[part 1 of 3: package /STLASWCs]
AUTOSAR XML (schema 4-3-0)
package /STLASWCs
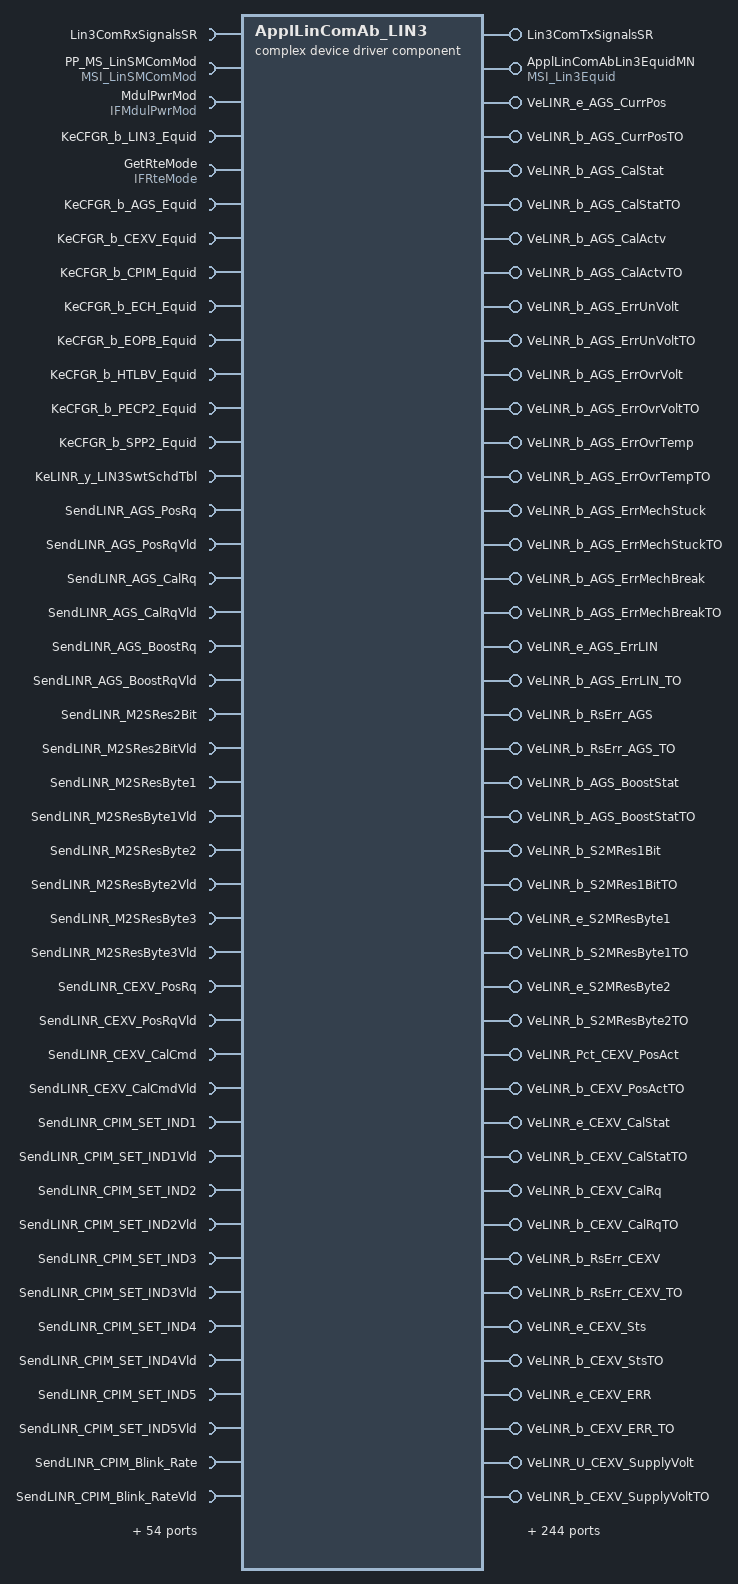
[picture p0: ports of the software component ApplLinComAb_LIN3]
  complex device driver sw component type ApplLinComAb_LIN3  # Application CAN Communication Abstraction Component - is responsible with receiving and sending CAN data from/to the lower BSW COM layers
    provide port Lin3ComTxSignalsSR: provided-interface=Lin3ComTxSignalsSR
      provided-com-specs:
        data-element=COMTXL_AGS_PosRq_ECM_AGS_DEMAND_Lin3, init-value=constant-reference=COMTXL_AGS_PosRq_ECM_AGS_DEMAND_Lin3_Init
        data-element=COMTXL_AGS_CalRq_ECM_AGS_DEMAND_Lin3, init-value=constant-reference=COMTXL_AGS_CalRq_ECM_AGS_DEMAND_Lin3_Init
        data-element=COMTXL_AGS_BoostRq_ECM_AGS_DEMAND_Lin3, init-value=constant-reference=COMTXL_AGS_BoostRq_ECM_AGS_DEMAND_Lin3_Init
        data-element=COMTXL_M2SRes2Bit_ECM_AGS_DEMAND_Lin3, init-value=constant-reference=COMTXL_M2SRes2Bit_ECM_AGS_DEMAND_Lin3_Init
        data-element=COMTXL_M2SResByte{1..3}_ECM_AGS_DEMAND_Lin3, init-value=constant-reference=COMTXL_M2SResByte{1..3}_ECM_AGS_DEMAND_Lin3_Init
        data-element=COMTXL_CEXV_PosRq_CEXV_REQ_Lin3, init-value=constant-reference=COMTXL_CEXV_PosRq_CEXV_REQ_Lin3_Init
        data-element=COMTXL_CEXV_CalCmd_CEXV_REQ_Lin3, init-value=constant-reference=COMTXL_CEXV_CalCmd_CEXV_REQ_Lin3_Init
        data-element=COMTXL_CPIM_SET_IND{1..5}_HCP_CPIM_COMMAND_Lin3, init-value=constant-reference=COMTXL_CPIM_SET_IND{1..5}_HCP_CPIM_COMMAND_Lin3_Init
        data-element=COMTXL_CPIM_Blink_Rate_HCP_CPIM_COMMAND_Lin3, init-value=constant-reference=COMTXL_CPIM_Blink_Rate_HCP_CPIM_COMMAND_Lin3_Init
        data-element=COMTXL_CPIM_IND_Color_HCP_CPIM_COMMAND_Lin3, init-value=constant-reference=COMTXL_CPIM_IND_Color_HCP_CPIM_COMMAND_Lin3_Init
        data-element=COMTXL_ChrgPortLock_Cmd_HCP_CPIM_COMMAND_Lin3, init-value=constant-reference=COMTXL_ChrgPortLock_Cmd_HCP_CPIM_COMMAND_Lin3_Init
        data-element=COMTXL_Set_Icon1_cmd_HCP_CPIM_COMMAND_Lin3, init-value=constant-reference=COMTXL_Set_Icon1_cmd_HCP_CPIM_COMMAND_Lin3_Init
        data-element=COMTXL_Set_Icon2_cmd_HCP_CPIM_COMMAND_Lin3, init-value=constant-reference=COMTXL_Set_Icon2_cmd_HCP_CPIM_COMMAND_Lin3_Init
        data-element=COMTXL_DAY_LGT_MD_CPIM_HCP_CPIM_COMMAND_Lin3, init-value=constant-reference=COMTXL_DAY_LGT_MD_CPIM_HCP_CPIM_COMMAND_Lin3_Init
        data-element=COMTXL_Backlight_Cmd_HCP_CPIM_COMMAND_Lin3, init-value=constant-reference=COMTXL_Backlight_Cmd_HCP_CPIM_COMMAND_Lin3_Init
        data-element=COMTXL_HvWtrHeatrPwrCnsAllwd_CCMLIN18Fr02_Lin3, init-value=constant-reference=COMTXL_HvWtrHeatrPwrCnsAllwd_CCMLIN18Fr02_Lin3_Init
        data-element=COMTXL_HvWtrHeatrWtrTDes_CCMLIN18Fr02_Lin3, init-value=constant-reference=COMTXL_HvWtrHeatrWtrTDes_CCMLIN18Fr02_Lin3_Init
        data-element=COMTXL_HvCooltHeatrEnad_CCMLIN18Fr02_Lin3, init-value=constant-reference=COMTXL_HvCooltHeatrEnad_CCMLIN18Fr02_Lin3_Init
        data-element=COMTXL_HVH_OverheatUnlock_CCMLIN18Fr02_Lin3, init-value=constant-reference=COMTXL_HVH_OverheatUnlock_CCMLIN18Fr02_Lin3_Init
        data-element=COMTXL_EOPB_RPM_COM_EOPB_REQ_Lin3, init-value=constant-reference=COMTXL_EOPB_RPM_COM_EOPB_REQ_Lin3_Init
        data-element=COMTXL_EOPB_POST_RUN_COM_EOPB_REQ_Lin3, init-value=constant-reference=COMTXL_EOPB_POST_RUN_COM_EOPB_REQ_Lin3_Init
        data-element=COMTXL_HTLBV_PosRq_HTLBV_REQ_Lin3, init-value=constant-reference=COMTXL_HTLBV_PosRq_HTLBV_REQ_Lin3_Init
        data-element=COMTXL_HTLBV_PosSv_HTLBV_REQ_Lin3, init-value=constant-reference=COMTXL_HTLBV_PosSv_HTLBV_REQ_Lin3_Init
        data-element=COMTXL_HTLBV_CalRq_HTLBV_REQ_Lin3, init-value=constant-reference=COMTXL_HTLBV_CalRq_HTLBV_REQ_Lin3_Init
        data-element=COMTXL_PECP2_RPM_REQ_PERCT_PECP2_REQ_GLOBAL_Lin3, init-value=constant-reference=COMTXL_PECP2_RPM_REQ_PERCT_PECP2_REQ_GLOBAL_Lin3_Init
        data-element=COMTXL_PECP2_POST_RUN_REQ_PECP2_REQ_GLOBAL_Lin3, init-value=constant-reference=COMTXL_PECP2_POST_RUN_REQ_PECP2_REQ_GLOBAL_Lin3_Init
        data-element=COMTXL_PECP2_FL_SAFE_ACTVT_PECP2_REQ_GLOBAL_Lin3, init-value=constant-reference=COMTXL_PECP2_FL_SAFE_ACTVT_PECP2_REQ_GLOBAL_Lin3_Init
        data-element=COMTXL_PowerPanel2_LED_A_Command_PowerPanel2_REQ_Lin3, init-value=constant-reference=COMTXL_PowerPanel2_LED_A_Command_PowerPanel2_REQ_Lin3_Init
        data-element=COMTXL_PowerPanel2_LED_B_Command_PowerPanel2_REQ_Lin3, init-value=constant-reference=COMTXL_PowerPanel2_LED_B_Command_PowerPanel2_REQ_Lin3_Init
        data-element=COMTXL_DAY_LGT_MD_PowerPanel2_PowerPanel2_REQ_Lin3, init-value=constant-reference=COMTXL_DAY_LGT_MD_PowerPanel2_PowerPanel2_REQ_Lin3_Init
        data-element=COMTXL_PowerPanel2_LED_A_Color_Command_PowerPanel2_REQ_Lin3, init-value=constant-reference=COMTXL_PowerPanel2_LED_A_Color_Command_PowerPanel2_REQ_Lin3_Init
        data-element=COMTXL_PowerPanel2_LED_B_Color_Command_PowerPanel2_REQ_Lin3, init-value=constant-reference=COMTXL_PowerPanel2_LED_B_Color_Command_PowerPanel2_REQ_Lin3_Init
    14 x require port:
      Lin3ComRxSignalsSR: required-interface=Lin3ComRxSignalsSR
        required-com-specs:
          data-element=COMRXL_AGS_CurrPos_AGS_ECM_STATUS_Lin3, alive-timeout=2.5, handle-never-received=true, init-value=constant-reference=COMRXL_AGS_CurrPos_AGS_ECM_STATUS_Lin3_Init
          data-element=COMRXL_AGS_CalStat_AGS_ECM_STATUS_Lin3, alive-timeout=2.5, handle-never-received=true, init-value=constant-reference=COMRXL_AGS_CalStat_AGS_ECM_STATUS_Lin3_Init
          data-element=COMRXL_AGS_CalActv_AGS_ECM_STATUS_Lin3, alive-timeout=2.5, handle-never-received=true, init-value=constant-reference=COMRXL_AGS_CalActv_AGS_ECM_STATUS_Lin3_Init
          data-element=COMRXL_AGS_ErrUnVolt_AGS_ECM_STATUS_Lin3, alive-timeout=2.5, handle-never-received=true, init-value=constant-reference=COMRXL_AGS_ErrUnVolt_AGS_ECM_STATUS_Lin3_Init
          data-element=COMRXL_AGS_ErrOvrVolt_AGS_ECM_STATUS_Lin3, alive-timeout=2.5, handle-never-received=true, init-value=constant-reference=COMRXL_AGS_ErrOvrVolt_AGS_ECM_STATUS_Lin3_Init
          data-element=COMRXL_AGS_ErrOvrTemp_AGS_ECM_STATUS_Lin3, alive-timeout=2.5, handle-never-received=true, init-value=constant-reference=COMRXL_AGS_ErrOvrTemp_AGS_ECM_STATUS_Lin3_Init
          data-element=COMRXL_AGS_ErrMechStuck_AGS_ECM_STATUS_Lin3, alive-timeout=2.5, handle-never-received=true, init-value=constant-reference=COMRXL_AGS_ErrMechStuck_AGS_ECM_STATUS_Lin3_Init
          data-element=COMRXL_AGS_ErrMechBreak_AGS_ECM_STATUS_Lin3, alive-timeout=2.5, handle-never-received=true, init-value=constant-reference=COMRXL_AGS_ErrMechBreak_AGS_ECM_STATUS_Lin3_Init
          data-element=COMRXL_AGS_ErrLIN_AGS_ECM_STATUS_Lin3, alive-timeout=2.5, handle-never-received=true, init-value=constant-reference=COMRXL_AGS_ErrLIN_AGS_ECM_STATUS_Lin3_Init
          data-element=COMRXL_RsErr_AGS_AGS_ECM_STATUS_Lin3, alive-timeout=2.5, handle-never-received=true, init-value=constant-reference=COMRXL_RsErr_AGS_AGS_ECM_STATUS_Lin3_Init
          data-element=COMRXL_AGS_BoostStat_AGS_ECM_STATUS_Lin3, alive-timeout=2.5, handle-never-received=true, init-value=constant-reference=COMRXL_AGS_BoostStat_AGS_ECM_STATUS_Lin3_Init
          data-element=COMRXL_S2MRes1Bit_AGS_ECM_STATUS_Lin3, alive-timeout=2.5, handle-never-received=true, init-value=constant-reference=COMRXL_S2MRes1Bit_AGS_ECM_STATUS_Lin3_Init
          data-element=COMRXL_S2MResByte1_AGS_ECM_STATUS_Lin3, alive-timeout=2.5, handle-never-received=true, init-value=constant-reference=COMRXL_S2MResByte1_AGS_ECM_STATUS_Lin3_Init
          data-element=COMRXL_S2MResByte2_AGS_ECM_STATUS_Lin3, alive-timeout=2.5, handle-never-received=true, init-value=constant-reference=COMRXL_S2MResByte2_AGS_ECM_STATUS_Lin3_Init
          data-element=COMRXL_CEXV_PosAct_CEXV_STAT_Lin3, alive-timeout=2.5, handle-never-received=true, init-value=constant-reference=COMRXL_CEXV_PosAct_CEXV_STAT_Lin3_Init
          data-element=COMRXL_CEXV_CalStat_CEXV_STAT_Lin3, alive-timeout=2.5, handle-never-received=true, init-value=constant-reference=COMRXL_CEXV_CalStat_CEXV_STAT_Lin3_Init
          data-element=COMRXL_CEXV_CalRq_CEXV_STAT_Lin3, alive-timeout=2.5, handle-never-received=true, init-value=constant-reference=COMRXL_CEXV_CalRq_CEXV_STAT_Lin3_Init
          data-element=COMRXL_RsErr_CEXV_CEXV_STAT_Lin3, alive-timeout=2.5, handle-never-received=true, init-value=constant-reference=COMRXL_RsErr_CEXV_CEXV_STAT_Lin3_Init
          data-element=COMRXL_CEXV_Sts_CEXV_STAT_Lin3, alive-timeout=2.5, handle-never-received=true, init-value=constant-reference=COMRXL_CEXV_Sts_CEXV_STAT_Lin3_Init
          data-element=COMRXL_CEXV_ERR_CEXV_STAT_Lin3, alive-timeout=2.5, handle-never-received=true, init-value=constant-reference=COMRXL_CEXV_ERR_CEXV_STAT_Lin3_Init
          data-element=COMRXL_CEXV_SupplyVolt_CEXV_STAT_Lin3, alive-timeout=2.5, handle-never-received=true, init-value=constant-reference=COMRXL_CEXV_SupplyVolt_CEXV_STAT_Lin3_Init
          data-element=COMRXL_CEXV_Refrigerant_Pressure_CEXV_STAT_Lin3, alive-timeout=2.5, handle-never-received=true, init-value=constant-reference=COMRXL_CEXV_Refrigerant_Pressure_CEXV_STAT_Lin3_Init
          data-element=COMRXL_CEXV_Board_Temp_CEXV_STAT_Lin3, alive-timeout=2.5, handle-never-received=true, init-value=constant-reference=COMRXL_CEXV_Board_Temp_CEXV_STAT_Lin3_Init
          data-element=COMRXL_CEXV_Refrigerant_Temp_CEXV_STAT_Lin3, alive-timeout=2.5, handle-never-received=true, init-value=constant-reference=COMRXL_CEXV_Refrigerant_Temp_CEXV_STAT_Lin3_Init
          data-element=COMRXL_Inlet_Temp1_DC_CPIM_HCP_FEEDBACK2_Lin3, alive-timeout=2.5, handle-never-received=true, init-value=constant-reference=COMRXL_Inlet_Temp1_DC_CPIM_HCP_FEEDBACK2_Lin3_Init
          data-element=COMRXL_Inlet_Temp2_DC_CPIM_HCP_FEEDBACK2_Lin3, alive-timeout=2.5, handle-never-received=true, init-value=constant-reference=COMRXL_Inlet_Temp2_DC_CPIM_HCP_FEEDBACK2_Lin3_Init
          data-element=COMRXL_CPIM_IND{1..5}_Fdbk_CPIM_HCP_FEEDBACK_Lin3, alive-timeout=2.5, handle-never-received=true, init-value=constant-reference=COMRXL_CPIM_IND{1..5}_Fdbk_CPIM_HCP_FEEDBACK_Lin3_Init
          data-element=COMRXL_CPIM_IND_Color_Fdbk_CPIM_HCP_FEEDBACK_Lin3, alive-timeout=2.5, handle-never-received=true, init-value=constant-reference=COMRXL_CPIM_IND_Color_Fdbk_CPIM_HCP_FEEDBACK_Lin3_Init
          data-element=COMRXL_CPIM_IND{1..5}_FailSts_CPIM_HCP_FEEDBACK_Lin3, alive-timeout=2.5, handle-never-received=true, init-value=constant-reference=COMRXL_CPIM_IND{1..5}_FailSts_CPIM_HCP_FEEDBACK_Lin3_Init
          data-element=COMRXL_CPIM_Undervoltage_CPIM_HCP_FEEDBACK_Lin3, alive-timeout=2.5, handle-never-received=true, init-value=constant-reference=COMRXL_CPIM_Undervoltage_CPIM_HCP_FEEDBACK_Lin3_Init
          data-element=COMRXL_CPIM_Over_Temperature_CPIM_HCP_FEEDBACK_Lin3, alive-timeout=2.5, handle-never-received=true, init-value=constant-reference=COMRXL_CPIM_Over_Temperature_CPIM_HCP_FEEDBACK_Lin3_Init
          data-element=COMRXL_CPIM_LIN_Parity_Error_CPIM_HCP_FEEDBACK_Lin3, alive-timeout=2.5, handle-never-received=true, init-value=constant-reference=COMRXL_CPIM_LIN_Parity_Error_CPIM_HCP_FEEDBACK_Lin3_Init
          data-element=COMRXL_CPIM_LIN_Checksum_Error_CPIM_HCP_FEEDBACK_Lin3, alive-timeout=2.5, handle-never-received=true, init-value=constant-reference=COMRXL_CPIM_LIN_Checksum_Error_CPIM_HCP_FEEDBACK_Lin3_Init
          data-element=COMRXL_CPIM_LIN_Data_Error_CPIM_HCP_FEEDBACK_Lin3, alive-timeout=2.5, handle-never-received=true, init-value=constant-reference=COMRXL_CPIM_LIN_Data_Error_CPIM_HCP_FEEDBACK_Lin3_Init
          data-element=COMRXL_ChrgPortLock_Sts_CPIM_HCP_FEEDBACK_Lin3, alive-timeout=2.5, handle-never-received=true, init-value=constant-reference=COMRXL_ChrgPortLock_Sts_CPIM_HCP_FEEDBACK_Lin3_Init
          data-element=COMRXL_ChrgPortButton_Sts_CPIM_HCP_FEEDBACK_Lin3, alive-timeout=2.5, handle-never-received=true, init-value=constant-reference=COMRXL_ChrgPortButton_Sts_CPIM_HCP_FEEDBACK_Lin3_Init
          data-element=COMRXL_Ambient_Temp_CPIM_HCP_FEEDBACK_Lin3, alive-timeout=2.5, handle-never-received=true, init-value=constant-reference=COMRXL_Ambient_Temp_CPIM_HCP_FEEDBACK_Lin3_Init
          data-element=COMRXL_Chrg_Inlet_Temp_CPIM_HCP_FEEDBACK_Lin3, alive-timeout=2.5, handle-never-received=true, init-value=constant-reference=COMRXL_Chrg_Inlet_Temp_CPIM_HCP_FEEDBACK_Lin3_Init
          data-element=COMRXL_ResponseErrorStsCPIM_CPIM_HCP_FEEDBACK_Lin3, alive-timeout=2.5, handle-never-received=true, init-value=constant-reference=COMRXL_ResponseErrorStsCPIM_CPIM_HCP_FEEDBACK_Lin3_Init
          data-element=COMRXL_ChrgPortLock_FailSts_CPIM_HCP_FEEDBACK_Lin3, alive-timeout=2.5, handle-never-received=true, init-value=constant-reference=COMRXL_ChrgPortLock_FailSts_CPIM_HCP_FEEDBACK_Lin3_Init
          data-element=COMRXL_Icon1_Sts_CPIM_HCP_FEEDBACK_Lin3, alive-timeout=2.5, handle-never-received=true, init-value=constant-reference=COMRXL_Icon1_Sts_CPIM_HCP_FEEDBACK_Lin3_Init
          data-element=COMRXL_Icon1_FailSts_CPIM_HCP_FEEDBACK_Lin3, alive-timeout=2.5, handle-never-received=true, init-value=constant-reference=COMRXL_Icon1_FailSts_CPIM_HCP_FEEDBACK_Lin3_Init
          data-element=COMRXL_Icon2_Sts_CPIM_HCP_FEEDBACK_Lin3, alive-timeout=2.5, handle-never-received=true, init-value=constant-reference=COMRXL_Icon2_Sts_CPIM_HCP_FEEDBACK_Lin3_Init
          data-element=COMRXL_Icon2_FailSts_CPIM_HCP_FEEDBACK_Lin3, alive-timeout=2.5, handle-never-received=true, init-value=constant-reference=COMRXL_Icon2_FailSts_CPIM_HCP_FEEDBACK_Lin3_Init
          data-element=COMRXL_ChrgPortDoor_Sts_CPIM_HCP_FEEDBACK_Lin3, alive-timeout=2.5, handle-never-received=true, init-value=constant-reference=COMRXL_ChrgPortDoor_Sts_CPIM_HCP_FEEDBACK_Lin3_Init
          data-element=COMRXL_HvCooltHeatrSts_HVCHLIN18Fr01_Lin3, alive-timeout=2.5, handle-never-received=true, init-value=constant-reference=COMRXL_HvCooltHeatrSts_HVCHLIN18Fr01_Lin3_Init
          data-element=COMRXL_ECH_InterlockStat_HVCHLIN18Fr01_Lin3, alive-timeout=2.5, handle-never-received=true, init-value=constant-reference=COMRXL_ECH_InterlockStat_HVCHLIN18Fr01_Lin3_Init
          data-element=COMRXL_Below_60V_HVCHLIN18Fr01_Lin3, alive-timeout=2.5, handle-never-received=true, init-value=constant-reference=COMRXL_Below_60V_HVCHLIN18Fr01_Lin3_Init
          data-element=COMRXL_HvCooltWtrHeatrWtrTInIntk_HVCHLIN18Fr01_Lin3, alive-timeout=2.5, handle-never-received=true, init-value=constant-reference=COMRXL_HvCooltWtrHeatrWtrTInIntk_HVCHLIN18Fr01_Lin3_Init
          data-element=COMRXL_HvWtrHeatrWtrT_HVCHLIN18Fr01_Lin3, alive-timeout=2.5, handle-never-received=true, init-value=constant-reference=COMRXL_HvWtrHeatrWtrT_HVCHLIN18Fr01_Lin3_Init
          data-element=COMRXL_HvCooltHeatrICns_HVCHLIN18Fr01_Lin3, alive-timeout=2.5, handle-never-received=true, init-value=constant-reference=COMRXL_HvCooltHeatrICns_HVCHLIN18Fr01_Lin3_Init
          data-element=COMRXL_HvCooltHVmeas_HVCHLIN18Fr01_Lin3, alive-timeout=2.5, handle-never-received=true, init-value=constant-reference=COMRXL_HvCooltHVmeas_HVCHLIN18Fr01_Lin3_Init
          data-element=COMRXL_HvHeatrPwrCns_HVCHLIN18Fr01_Lin3, alive-timeout=2.5, handle-never-received=true, init-value=constant-reference=COMRXL_HvHeatrPwrCns_HVCHLIN18Fr01_Lin3_Init
          data-element=COMRXL_HvHeatrPwrCnsDes_HVCHLIN18Fr01_Lin3, alive-timeout=2.5, handle-never-received=true, init-value=constant-reference=COMRXL_HvHeatrPwrCnsDes_HVCHLIN18Fr01_Lin3_Init
          data-element=COMRXL_HVH_UnlockCounter_HVCHLIN18Fr01_Lin3, alive-timeout=2.5, handle-never-received=true, init-value=constant-reference=COMRXL_HVH_UnlockCounter_HVCHLIN18Fr01_Lin3_Init
          data-element=COMRXL_RsErr_ECH_HVCHLIN18Fr02_Lin3, alive-timeout=2.5, handle-never-received=true, init-value=constant-reference=COMRXL_RsErr_ECH_HVCHLIN18Fr02_Lin3_Init
          data-element=COMRXL_HvCooltHeatrWarnFltInCom_HVCHLIN18Fr02_Lin3, alive-timeout=2.5, handle-never-received=true, init-value=constant-reference=COMRXL_HvCooltHeatrWarnFltInCom_HVCHLIN18Fr02_Lin3_Init
          data-element=COMRXL_HvCooltHeatrWarnHvOutOfRng_HVCHLIN18Fr02_Lin3, alive-timeout=2.5, handle-never-received=true, init-value=constant-reference=COMRXL_HvCooltHeatrWarnHvOutOfRng_HVCHLIN18Fr02_Lin3_Init
          data-element=COMRXL_HvCooltHeatrWarnULoOutOfRng_HVCHLIN18Fr02_Lin3, alive-timeout=2.5, handle-never-received=true, init-value=constant-reference=COMRXL_HvCooltHeatrWarnULoOutOfRng_HVCHLIN18Fr02_Lin3_Init
          data-element=COMRXL_HvCooltHeatrWarnCooltTOutOfRng_HVCHLIN18Fr02_Lin3, alive-timeout=2.5, handle-never-received=true, init-value=constant-reference=COMRXL_HvCooltHeatrWarnCooltTOutOfRng_HVCHLIN18Fr02_Lin3_Init
          data-element=COMRXL_HvCooltHeatrProtnOfSelfTmpHwProtn_HVCHLIN18Fr02_Lin3, alive-timeout=2.5, handle-never-received=true, init-value=constant-reference=COMRXL_HvCooltHeatrProtnOfSelfTmpHwProtn_HVCHLIN18Fr02_Lin3_Init
          data-element=COMRXL_HvCooltHeatrProtnOfSelfTmpOvrheatg_HVCHLIN18Fr02_Lin3, alive-timeout=2.5, handle-never-received=true, init-value=constant-reference=COMRXL_HvCooltHeatrProtnOfSelfTmpOvrheatg_HVCHLIN18Fr02_Lin3_Init
          data-element=COMRXL_HvCooltHeatrSnsrFltCooltTInSnsrFlt_HVCHLIN18Fr02_Lin3, alive-timeout=2.5, handle-never-received=true, init-value=constant-reference=COMRXL_HvCooltHeatrSnsrFltCooltTInSnsrFlt_HVCHLIN18Fr02_Lin3_Init
          data-element=COMRXL_HvCooltHeatrSnsrFltCooltTOutSnsrFlt_HVCHLIN18Fr02_Lin3, alive-timeout=2.5, handle-never-received=true, init-value=constant-reference=COMRXL_HvCooltHeatrSnsrFltCooltTOutSnsrFlt_HVCHLIN18Fr02_Lin3_Init
          data-element=COMRXL_HvCooltHeatrSnsrFltTInMtrlSnsrFlt_HVCHLIN18Fr02_Lin3, alive-timeout=2.5, handle-never-received=true, init-value=constant-reference=COMRXL_HvCooltHeatrSnsrFltTInMtrlSnsrFlt_HVCHLIN18Fr02_Lin3_Init
          data-element=COMRXL_HvCooltHeatrSrvRqrdCircForDrvrShoOrOpen_HVCHLIN18Fr02_Lin3, alive-timeout=2.5, handle-never-received=true, init-value=constant-reference=COMRXL_HvCooltHeatrSrvRqrdCircForDrvrShoOrOpen_HVCHLIN18Fr02_Lin3_Init
          data-element=COMRXL_HvCooltHeatrSrvRqrdICnsOutOfRng_HVCHLIN18Fr02_Lin3, alive-timeout=2.5, handle-never-received=true, init-value=constant-reference=COMRXL_HvCooltHeatrSrvRqrdICnsOutOfRng_HVCHLIN18Fr02_Lin3_Init
          data-element=COMRXL_HvCooltHeatrSrvRqrdMemErr_HVCHLIN18Fr02_Lin3, alive-timeout=2.5, handle-never-received=true, init-value=constant-reference=COMRXL_HvCooltHeatrSrvRqrdMemErr_HVCHLIN18Fr02_Lin3_Init
          data-element=COMRXL_HvCooltHeatrSrvRqrdSrvRqrd_HVCHLIN18Fr02_Lin3, alive-timeout=2.5, handle-never-received=true, init-value=constant-reference=COMRXL_HvCooltHeatrSrvRqrdSrvRqrd_HVCHLIN18Fr02_Lin3_Init
          data-element=COMRXL_EOPB_RPM_TGT_EOPB_STAT_Lin3, alive-timeout=2.5, handle-never-received=true, init-value=constant-reference=COMRXL_EOPB_RPM_TGT_EOPB_STAT_Lin3_Init
          data-element=COMRXL_EOPB_RPM_ACTL_EOPB_STAT_Lin3, alive-timeout=2.5, handle-never-received=true, init-value=constant-reference=COMRXL_EOPB_RPM_ACTL_EOPB_STAT_Lin3_Init
          data-element=COMRXL_EOPB_VLTG_EOPB_STAT_Lin3, alive-timeout=2.5, handle-never-received=true, init-value=constant-reference=COMRXL_EOPB_VLTG_EOPB_STAT_Lin3_Init
          data-element=COMRXL_EOPB_TEMP_EOPB_STAT_Lin3, alive-timeout=2.5, handle-never-received=true, init-value=constant-reference=COMRXL_EOPB_TEMP_EOPB_STAT_Lin3_Init
          data-element=COMRXL_EOPB_CURR_EOPB_STAT_Lin3, alive-timeout=2.5, handle-never-received=true, init-value=constant-reference=COMRXL_EOPB_CURR_EOPB_STAT_Lin3_Init
          data-element=COMRXL_EOPB_LOW_TMP_STAT_EOPB_STAT_Lin3, alive-timeout=2.5, handle-never-received=true, init-value=constant-reference=COMRXL_EOPB_LOW_TMP_STAT_EOPB_STAT_Lin3_Init
          data-element=COMRXL_EOPB_MONTRNG_RPM_EOPB_STAT_Lin3, alive-timeout=2.5, handle-never-received=true, init-value=constant-reference=COMRXL_EOPB_MONTRNG_RPM_EOPB_STAT_Lin3_Init
          data-element=COMRXL_EOPB_LMP_HM_AN_ON_EOPB_STAT_Lin3, alive-timeout=2.5, handle-never-received=true, init-value=constant-reference=COMRXL_EOPB_LMP_HM_AN_ON_EOPB_STAT_Lin3_Init
          data-element=COMRXL_EOPB_OV_TMP_ER_EOPB_STAT_Lin3, alive-timeout=2.5, handle-never-received=true, init-value=constant-reference=COMRXL_EOPB_OV_TMP_ER_EOPB_STAT_Lin3_Init
          data-element=COMRXL_EOPB_OV_CUR_ER_EOPB_STAT_Lin3, alive-timeout=2.5, handle-never-received=true, init-value=constant-reference=COMRXL_EOPB_OV_CUR_ER_EOPB_STAT_Lin3_Init
          data-element=COMRXL_EOPB_DR_RN_ER_EOPB_STAT_Lin3, alive-timeout=2.5, handle-never-received=true, init-value=constant-reference=COMRXL_EOPB_DR_RN_ER_EOPB_STAT_Lin3_Init
          data-element=COMRXL_EOPB_VLTG_ER_EOPB_STAT_Lin3, alive-timeout=2.5, handle-never-received=true, init-value=constant-reference=COMRXL_EOPB_VLTG_ER_EOPB_STAT_Lin3_Init
          data-element=COMRXL_EOPB_Stall_Event_EOPB_STAT_Lin3, alive-timeout=2.5, handle-never-received=true, init-value=constant-reference=COMRXL_EOPB_Stall_Event_EOPB_STAT_Lin3_Init
          data-element=COMRXL_EOPB_POST_RUN_STAT_EOPB_STAT_Lin3, alive-timeout=2.5, handle-never-received=true, init-value=constant-reference=COMRXL_EOPB_POST_RUN_STAT_EOPB_STAT_Lin3_Init
          data-element=COMRXL_RsErr_EOPB_EOPB_STAT_Lin3, alive-timeout=2.5, handle-never-received=true, init-value=constant-reference=COMRXL_RsErr_EOPB_EOPB_STAT_Lin3_Init
          data-element=COMRXL_EOPB_OIL_TEMP_EOPB_STAT2_Lin3, alive-timeout=2.5, handle-never-received=true, init-value=constant-reference=COMRXL_EOPB_OIL_TEMP_EOPB_STAT2_Lin3_Init
          data-element=COMRXL_EOPB_HW_VER_EOPB_VER_Lin3, alive-timeout=2.5, handle-never-received=true, init-value=constant-reference=COMRXL_EOPB_HW_VER_EOPB_VER_Lin3_Init
          data-element=COMRXL_EOPB_SW_VER_EOPB_VER_Lin3, alive-timeout=2.5, handle-never-received=true, init-value=constant-reference=COMRXL_EOPB_SW_VER_EOPB_VER_Lin3_Init
          data-element=COMRXL_HTLBV_PosAct_HTLBV_STAT_Lin3, alive-timeout=2.5, handle-never-received=true, init-value=constant-reference=COMRXL_HTLBV_PosAct_HTLBV_STAT_Lin3_Init
          data-element=COMRXL_HTLBV_ERR_HTLBV_STAT_Lin3, alive-timeout=2.5, handle-never-received=true, init-value=constant-reference=COMRXL_HTLBV_ERR_HTLBV_STAT_Lin3_Init
          data-element=COMRXL_HTLBV_MotorVolt_HTLBV_STAT_Lin3, alive-timeout=2.5, handle-never-received=true, init-value=constant-reference=COMRXL_HTLBV_MotorVolt_HTLBV_STAT_Lin3_Init
          data-element=COMRXL_HTLBV_Sts_HTLBV_STAT_Lin3, alive-timeout=2.5, handle-never-received=true, init-value=constant-reference=COMRXL_HTLBV_Sts_HTLBV_STAT_Lin3_Init
          data-element=COMRXL_RsErr_HTLBV_HTLBV_STAT_Lin3, alive-timeout=2.5, handle-never-received=true, init-value=constant-reference=COMRXL_RsErr_HTLBV_HTLBV_STAT_Lin3_Init
          data-element=COMRXL_HTLBV_CalStat_HTLBV_STAT_Lin3, alive-timeout=2.5, handle-never-received=true, init-value=constant-reference=COMRXL_HTLBV_CalStat_HTLBV_STAT_Lin3_Init
          data-element=COMRXL_PECP2_RPM_TGT_PERCT_PECP2_STAT_GLOBAL_Lin3, alive-timeout=2.5, handle-never-received=true, init-value=constant-reference=COMRXL_PECP2_RPM_TGT_PERCT_PECP2_STAT_GLOBAL_Lin3_Init
          data-element=COMRXL_PECP2_RPM_ACTL_PERCT_PECP2_STAT_GLOBAL_Lin3, alive-timeout=2.5, handle-never-received=true, init-value=constant-reference=COMRXL_PECP2_RPM_ACTL_PERCT_PECP2_STAT_GLOBAL_Lin3_Init
          data-element=COMRXL_PECP2_VLTG_PECP2_STAT_GLOBAL_Lin3, alive-timeout=2.5, handle-never-received=true, init-value=constant-reference=COMRXL_PECP2_VLTG_PECP2_STAT_GLOBAL_Lin3_Init
          data-element=COMRXL_PECP2_TEMP_PECP2_STAT_GLOBAL_Lin3, alive-timeout=2.5, handle-never-received=true, init-value=constant-reference=COMRXL_PECP2_TEMP_PECP2_STAT_GLOBAL_Lin3_Init
          data-element=COMRXL_PECP2_CURR_PECP2_STAT_GLOBAL_Lin3, alive-timeout=2.5, handle-never-received=true, init-value=constant-reference=COMRXL_PECP2_CURR_PECP2_STAT_GLOBAL_Lin3_Init
          data-element=COMRXL_PECP2_FL_SAFE_ACTVTD_PECP2_STAT_GLOBAL_Lin3, alive-timeout=2.5, handle-never-received=true, init-value=constant-reference=COMRXL_PECP2_FL_SAFE_ACTVTD_PECP2_STAT_GLOBAL_Lin3_Init
          data-element=COMRXL_PECP2_LMP_HM_AN_ON_PECP2_STAT_GLOBAL_Lin3, alive-timeout=2.5, handle-never-received=true, init-value=constant-reference=COMRXL_PECP2_LMP_HM_AN_ON_PECP2_STAT_GLOBAL_Lin3_Init
          data-element=COMRXL_PECP2_AIR_PRE_ERR_PECP2_STAT_GLOBAL_Lin3, alive-timeout=2.5, handle-never-received=true, init-value=constant-reference=COMRXL_PECP2_AIR_PRE_ERR_PECP2_STAT_GLOBAL_Lin3_Init
          data-element=COMRXL_PECP2_OVR_TMP_ERR_PECP2_STAT_GLOBAL_Lin3, alive-timeout=2.5, handle-never-received=true, init-value=constant-reference=COMRXL_PECP2_OVR_TMP_ERR_PECP2_STAT_GLOBAL_Lin3_Init
          data-element=COMRXL_PECP2_OVR_CUR_ERR_PECP2_STAT_GLOBAL_Lin3, alive-timeout=2.5, handle-never-received=true, init-value=constant-reference=COMRXL_PECP2_OVR_CUR_ERR_PECP2_STAT_GLOBAL_Lin3_Init
          data-element=COMRXL_PECP2_DR_RN_ERR_PECP2_STAT_GLOBAL_Lin3, alive-timeout=2.5, handle-never-received=true, init-value=constant-reference=COMRXL_PECP2_DR_RN_ERR_PECP2_STAT_GLOBAL_Lin3_Init
          data-element=COMRXL_PECP2_VLTG_ERR_PECP2_STAT_GLOBAL_Lin3, alive-timeout=2.5, handle-never-received=true, init-value=constant-reference=COMRXL_PECP2_VLTG_ERR_PECP2_STAT_GLOBAL_Lin3_Init
          data-element=COMRXL_PECP2_DBLK_ACTV_PECP2_STAT_GLOBAL_Lin3, alive-timeout=2.5, handle-never-received=true, init-value=constant-reference=COMRXL_PECP2_DBLK_ACTV_PECP2_STAT_GLOBAL_Lin3_Init
          data-element=COMRXL_PECP2_MONTRNG_RPM_PECP2_STAT_GLOBAL_Lin3, alive-timeout=2.5, handle-never-received=true, init-value=constant-reference=COMRXL_PECP2_MONTRNG_RPM_PECP2_STAT_GLOBAL_Lin3_Init
          data-element=COMRXL_PECP2_NODE_ERR_PECP2_STAT_GLOBAL_Lin3, alive-timeout=2.5, handle-never-received=true, init-value=constant-reference=COMRXL_PECP2_NODE_ERR_PECP2_STAT_GLOBAL_Lin3_Init
          data-element=COMRXL_PECP2_POST_RUN_STAT_PECP2_STAT_GLOBAL_Lin3, alive-timeout=2.5, handle-never-received=true, init-value=constant-reference=COMRXL_PECP2_POST_RUN_STAT_PECP2_STAT_GLOBAL_Lin3_Init
          data-element=COMRXL_RsErr_PECP2_PUMP_PECP2_STAT_GLOBAL_Lin3, alive-timeout=2.5, handle-never-received=true, init-value=constant-reference=COMRXL_RsErr_PECP2_PUMP_PECP2_STAT_GLOBAL_Lin3_Init
          data-element=COMRXL_PECP2_VERSION_PECP2_VER_Lin3, alive-timeout=2.5, handle-never-received=true, init-value=constant-reference=COMRXL_PECP2_VERSION_PECP2_VER_Lin3_Init
          data-element=COMRXL_PECP2_SUPPLIER_PECP2_VER_Lin3, alive-timeout=2.5, handle-never-received=true, init-value=constant-reference=COMRXL_PECP2_SUPPLIER_PECP2_VER_Lin3_Init
          data-element=COMRXL_PowerPanel2_Button_State_PowerPanel2_STAT_Lin3, alive-timeout=2.5, handle-never-received=true, init-value=constant-reference=COMRXL_PowerPanel2_Button_State_PowerPanel2_STAT_Lin3_Init
          data-element=COMRXL_PowerPanel2_Lid_Switch_Sts_120A_PowerPanel2_STAT_Lin3, alive-timeout=2.5, handle-never-received=true, init-value=constant-reference=COMRXL_PowerPanel2_Lid_Switch_Sts_120A_PowerPanel2_STAT_Lin3_Init
          data-element=COMRXL_PowerPanel2_Lid_Switch_Sts_120B_PowerPanel2_STAT_Lin3, alive-timeout=2.5, handle-never-received=true, init-value=constant-reference=COMRXL_PowerPanel2_Lid_Switch_Sts_120B_PowerPanel2_STAT_Lin3_Init
          data-element=COMRXL_PowerPanel2_Lid_Switch_Sts_240_PowerPanel2_STAT_Lin3, alive-timeout=2.5, handle-never-received=true, init-value=constant-reference=COMRXL_PowerPanel2_Lid_Switch_Sts_240_PowerPanel2_STAT_Lin3_Init
          data-element=COMRXL_PowerPanel2_AC_Present_Sens1_PowerPanel2_STAT_Lin3, alive-timeout=2.5, handle-never-received=true, init-value=constant-reference=COMRXL_PowerPanel2_AC_Present_Sens1_PowerPanel2_STAT_Lin3_Init
          data-element=COMRXL_PowerPanel2_AC_Present_Sens2_PowerPanel2_STAT_Lin3, alive-timeout=2.5, handle-never-received=true, init-value=constant-reference=COMRXL_PowerPanel2_AC_Present_Sens2_PowerPanel2_STAT_Lin3_Init
          data-element=COMRXL_PowerPanel2_Fault_Reason_PowerPanel2_STAT_Lin3, alive-timeout=2.5, handle-never-received=true, init-value=constant-reference=COMRXL_PowerPanel2_Fault_Reason_PowerPanel2_STAT_Lin3_Init
          data-element=COMRXL_RsErr_SPP2_PowerPanel2_STAT_Lin3, alive-timeout=2.5, handle-never-received=true, init-value=constant-reference=COMRXL_RsErr_SPP2_PowerPanel2_STAT_Lin3_Init
          data-element=COMRXL_PowerPanel2_LED_A_Feedback_PowerPanel2_STAT_Lin3, alive-timeout=2.5, handle-never-received=true, init-value=constant-reference=COMRXL_PowerPanel2_LED_A_Feedback_PowerPanel2_STAT_Lin3_Init
          data-element=COMRXL_PowerPanel2_LED_B_Feedback_PowerPanel2_STAT_Lin3, alive-timeout=2.5, handle-never-received=true, init-value=constant-reference=COMRXL_PowerPanel2_LED_B_Feedback_PowerPanel2_STAT_Lin3_Init
          data-element=COMRXL_PowerPanel2_LED_A_FailStatus_PowerPanel2_STAT_Lin3, alive-timeout=2.5, handle-never-received=true, init-value=constant-reference=COMRXL_PowerPanel2_LED_A_FailStatus_PowerPanel2_STAT_Lin3_Init
          data-element=COMRXL_PowerPanel2_LED_B_FailStatus_PowerPanel2_STAT_Lin3, alive-timeout=2.5, handle-never-received=true, init-value=constant-reference=COMRXL_PowerPanel2_LED_B_FailStatus_PowerPanel2_STAT_Lin3_Init
          data-element=COMRXL_PowerPanel2_LED_A_Color_Feedback_PowerPanel2_STAT_Lin3, alive-timeout=2.5, handle-never-received=true, init-value=constant-reference=COMRXL_PowerPanel2_LED_A_Color_Feedback_PowerPanel2_STAT_Lin3_Init
          data-element=COMRXL_PowerPanel2_LED_B_Color_Feedback_PowerPanel2_STAT_Lin3, alive-timeout=2.5, handle-never-received=true, init-value=constant-reference=COMRXL_PowerPanel2_LED_B_Color_Feedback_PowerPanel2_STAT_Lin3_Init
          data-element=COMRXL_PowerPanel2_LIN_Checksum_Error_PowerPanel2_STAT_Lin3, alive-timeout=2.5, handle-never-received=true, init-value=constant-reference=COMRXL_PowerPanel2_LIN_Checksum_Error_PowerPanel2_STAT_Lin3_Init
          data-element=COMRXL_PowerPanel2_LIN_Data_Error_PowerPanel2_STAT_Lin3, alive-timeout=2.5, handle-never-received=true, init-value=constant-reference=COMRXL_PowerPanel2_LIN_Data_Error_PowerPanel2_STAT_Lin3_Init
          data-element=COMRXL_PowerPanel2_LIN_Parity_Error_PowerPanel2_STAT_Lin3, alive-timeout=2.5, handle-never-received=true, init-value=constant-reference=COMRXL_PowerPanel2_LIN_Parity_Error_PowerPanel2_STAT_Lin3_Init
          data-element=COMRXL_PowerPanel2_Gnd_Fault_Detected_PowerPanel2_STAT_Lin3, alive-timeout=2.5, handle-never-received=true, init-value=constant-reference=COMRXL_PowerPanel2_Gnd_Fault_Detected_PowerPanel2_STAT_Lin3_Init
          data-element=COMRXL_PowerPanel2_Current_Draw_Sens1_PowerPanel2_STAT_Lin3, alive-timeout=2.5, handle-never-received=true, init-value=constant-reference=COMRXL_PowerPanel2_Current_Draw_Sens1_PowerPanel2_STAT_Lin3_Init
          data-element=COMRXL_PowerPanel2_Current_Draw_Sens2_PowerPanel2_STAT_Lin3, alive-timeout=2.5, handle-never-received=true, init-value=constant-reference=COMRXL_PowerPanel2_Current_Draw_Sens2_PowerPanel2_STAT_Lin3_Init
          data-element=COMRXL_PowerPanel2_Fault_PowerPanel2_STAT_Lin3, alive-timeout=2.5, handle-never-received=true, init-value=constant-reference=COMRXL_PowerPanel2_Fault_PowerPanel2_STAT_Lin3_Init
          data-element=COMRXL_PowerPanel2_RatedPower_PowerPanel2_STAT_Lin3, alive-timeout=2.5, handle-never-received=true, init-value=constant-reference=COMRXL_PowerPanel2_RatedPower_PowerPanel2_STAT_Lin3_Init
      PP_MS_LinSMComMod: mode-switch-receiver-com-spec=MDGP_MSI_LinSMComMod, required-interface=MSI_LinSMComMod  # Mode switch port used to indicate Linsm comm state
      MdulPwrMod: mode-switch-receiver-com-spec=AppMode_MDGP_ESH_Mode, required-interface=IFMdulPwrMod  # Mode switch port used to indicate ECU state
      KeCFGR_b_LIN3_Equid: parameter-require-com-spec{init-value=Value:1, parameter=KeCFGR_b_LIN3_Equid}, required-interface=KeCFGR_b_LIN3_Equid
      GetRteMode: client-com-spec=GetMODR_b_InPostRunMode, required-interface=IFRteMode
      KeCFGR_b_AGS_Equid: parameter-require-com-spec{init-value=Value:0, parameter=KeCFGR_b_AGS_Equid}, required-interface=KeCFGR_b_AGS_Equid
      KeCFGR_b_CEXV_Equid: parameter-require-com-spec{init-value=Value:0, parameter=KeCFGR_b_CEXV_Equid}, required-interface=KeCFGR_b_CEXV_Equid
      KeCFGR_b_CPIM_Equid: parameter-require-com-spec{init-value=Value:0, parameter=KeCFGR_b_CPIM_Equid}, required-interface=KeCFGR_b_CPIM_Equid
      KeCFGR_b_ECH_Equid: parameter-require-com-spec{init-value=Value:0, parameter=KeCFGR_b_ECH_Equid}, required-interface=KeCFGR_b_ECH_Equid
      KeCFGR_b_EOPB_Equid: parameter-require-com-spec{init-value=Value:0, parameter=KeCFGR_b_EOPB_Equid}, required-interface=KeCFGR_b_EOPB_Equid
      KeCFGR_b_HTLBV_Equid: parameter-require-com-spec{init-value=Value:0, parameter=KeCFGR_b_HTLBV_Equid}, required-interface=KeCFGR_b_HTLBV_Equid
      KeCFGR_b_PECP2_Equid: parameter-require-com-spec{init-value=Value:0, parameter=KeCFGR_b_PECP2_Equid}, required-interface=KeCFGR_b_PECP2_Equid
      KeCFGR_b_SPP2_Equid: parameter-require-com-spec{init-value=Value:0, parameter=KeCFGR_b_SPP2_Equid}, required-interface=KeCFGR_b_SPP2_Equid
      KeLINR_y_LIN3SwtSchdTbl: parameter-require-com-spec{init-value=Value:0, parameter=KeLINR_y_LIN3SwtSchdTbl}, required-interface=KeLINR_y_LIN3SwtSchdTbl
    257 x provide port:
      ApplLinComAbLin3EquidMN: mode-switch-sender-com-spec{mode-group=MDGP_MSI_Lin3Equid, queue-length=1}, provided-interface=MSI_Lin3Equid
      VeLINR_e_AGS_CurrPos: nonqueued-sender-com-spec{data-element=VeLINR_e_AGS_CurrPos, init-value=VeLINR_e_AGS_CurrPosValue:0}, provided-interface=VeLINR_e_AGS_CurrPos
      VeLINR_b_AGS_CurrPosTO: nonqueued-sender-com-spec{data-element=VeLINR_b_AGS_CurrPosTO, init-value=VeLINR_b_AGS_CurrPosTOValue:0}, provided-interface=VeLINR_b_AGS_CurrPosTO
      VeLINR_b_AGS_CalStat: nonqueued-sender-com-spec{data-element=VeLINR_b_AGS_CalStat, init-value=VeLINR_b_AGS_CalStatValue:0}, provided-interface=VeLINR_b_AGS_CalStat
      VeLINR_b_AGS_CalStatTO: nonqueued-sender-com-spec{data-element=VeLINR_b_AGS_CalStatTO, init-value=VeLINR_b_AGS_CalStatTOValue:0}, provided-interface=VeLINR_b_AGS_CalStatTO
      VeLINR_b_AGS_CalActv: nonqueued-sender-com-spec{data-element=VeLINR_b_AGS_CalActv, init-value=VeLINR_b_AGS_CalActvValue:0}, provided-interface=VeLINR_b_AGS_CalActv
      VeLINR_b_AGS_CalActvTO: nonqueued-sender-com-spec{data-element=VeLINR_b_AGS_CalActvTO, init-value=VeLINR_b_AGS_CalActvTOValue:0}, provided-interface=VeLINR_b_AGS_CalActvTO
      VeLINR_b_AGS_ErrUnVolt: nonqueued-sender-com-spec{data-element=VeLINR_b_AGS_ErrUnVolt, init-value=VeLINR_b_AGS_ErrUnVoltValue:0}, provided-interface=VeLINR_b_AGS_ErrUnVolt
      VeLINR_b_AGS_ErrUnVoltTO: nonqueued-sender-com-spec{data-element=VeLINR_b_AGS_ErrUnVoltTO, init-value=VeLINR_b_AGS_ErrUnVoltTOValue:0}, provided-interface=VeLINR_b_AGS_ErrUnVoltTO
      VeLINR_b_AGS_ErrOvrVolt: nonqueued-sender-com-spec{data-element=VeLINR_b_AGS_ErrOvrVolt, init-value=VeLINR_b_AGS_ErrOvrVoltValue:0}, provided-interface=VeLINR_b_AGS_ErrOvrVolt
      VeLINR_b_AGS_ErrOvrVoltTO: nonqueued-sender-com-spec{data-element=VeLINR_b_AGS_ErrOvrVoltTO, init-value=VeLINR_b_AGS_ErrOvrVoltTOValue:0}, provided-interface=VeLINR_b_AGS_ErrOvrVoltTO
      VeLINR_b_AGS_ErrOvrTemp: nonqueued-sender-com-spec{data-element=VeLINR_b_AGS_ErrOvrTemp, init-value=VeLINR_b_AGS_ErrOvrTempValue:0}, provided-interface=VeLINR_b_AGS_ErrOvrTemp
      VeLINR_b_AGS_ErrOvrTempTO: nonqueued-sender-com-spec{data-element=VeLINR_b_AGS_ErrOvrTempTO, init-value=VeLINR_b_AGS_ErrOvrTempTOValue:0}, provided-interface=VeLINR_b_AGS_ErrOvrTempTO
      VeLINR_b_AGS_ErrMechStuck: nonqueued-sender-com-spec{data-element=VeLINR_b_AGS_ErrMechStuck, init-value=VeLINR_b_AGS_ErrMechStuckValue:0}, provided-interface=VeLINR_b_AGS_ErrMechStuck
      VeLINR_b_AGS_ErrMechStuckTO: nonqueued-sender-com-spec{data-element=VeLINR_b_AGS_ErrMechStuckTO, init-value=VeLINR_b_AGS_ErrMechStuckTOValue:0}, provided-interface=VeLINR_b_AGS_ErrMechStuckTO
      VeLINR_b_AGS_ErrMechBreak: nonqueued-sender-com-spec{data-element=VeLINR_b_AGS_ErrMechBreak, init-value=VeLINR_b_AGS_ErrMechBreakValue:0}, provided-interface=VeLINR_b_AGS_ErrMechBreak
      VeLINR_b_AGS_ErrMechBreakTO: nonqueued-sender-com-spec{data-element=VeLINR_b_AGS_ErrMechBreakTO, init-value=VeLINR_b_AGS_ErrMechBreakTOValue:0}, provided-interface=VeLINR_b_AGS_ErrMechBreakTO
      VeLINR_e_AGS_ErrLIN: nonqueued-sender-com-spec{data-element=VeLINR_e_AGS_ErrLIN, init-value=VeLINR_e_AGS_ErrLINValue:0}, provided-interface=VeLINR_e_AGS_ErrLIN
      VeLINR_b_AGS_ErrLIN_TO: nonqueued-sender-com-spec{data-element=VeLINR_b_AGS_ErrLIN_TO, init-value=VeLINR_b_AGS_ErrLIN_TOValue:0}, provided-interface=VeLINR_b_AGS_ErrLIN_TO
      VeLINR_b_RsErr_AGS: nonqueued-sender-com-spec{data-element=VeLINR_b_RsErr_AGS, init-value=VeLINR_b_RsErr_AGSValue:0}, provided-interface=VeLINR_b_RsErr_AGS
      VeLINR_b_RsErr_AGS_TO: nonqueued-sender-com-spec{data-element=VeLINR_b_RsErr_AGS_TO, init-value=VeLINR_b_RsErr_AGS_TOValue:0}, provided-interface=VeLINR_b_RsErr_AGS_TO
      VeLINR_b_AGS_BoostStat: nonqueued-sender-com-spec{data-element=VeLINR_b_AGS_BoostStat, init-value=VeLINR_b_AGS_BoostStatValue:0}, provided-interface=VeLINR_b_AGS_BoostStat
      VeLINR_b_AGS_BoostStatTO: nonqueued-sender-com-spec{data-element=VeLINR_b_AGS_BoostStatTO, init-value=VeLINR_b_AGS_BoostStatTOValue:0}, provided-interface=VeLINR_b_AGS_BoostStatTO
      VeLINR_b_S2MRes1Bit: nonqueued-sender-com-spec{data-element=VeLINR_b_S2MRes1Bit, init-value=VeLINR_b_S2MRes1BitValue:0}, provided-interface=VeLINR_b_S2MRes1Bit
      VeLINR_b_S2MRes1BitTO: nonqueued-sender-com-spec{data-element=VeLINR_b_S2MRes1BitTO, init-value=VeLINR_b_S2MRes1BitTOValue:0}, provided-interface=VeLINR_b_S2MRes1BitTO
      VeLINR_e_S2MResByte1: nonqueued-sender-com-spec{data-element=VeLINR_e_S2MResByte1, init-value=VeLINR_e_S2MResByte1Value:0}, provided-interface=VeLINR_e_S2MResByte1
      VeLINR_b_S2MResByte1TO: nonqueued-sender-com-spec{data-element=VeLINR_b_S2MResByte1TO, init-value=VeLINR_b_S2MResByte1TOValue:0}, provided-interface=VeLINR_b_S2MResByte1TO
      VeLINR_e_S2MResByte2: nonqueued-sender-com-spec{data-element=VeLINR_e_S2MResByte2, init-value=VeLINR_e_S2MResByte2Value:0}, provided-interface=VeLINR_e_S2MResByte2
      VeLINR_b_S2MResByte2TO: nonqueued-sender-com-spec{data-element=VeLINR_b_S2MResByte2TO, init-value=VeLINR_b_S2MResByte2TOValue:0}, provided-interface=VeLINR_b_S2MResByte2TO
      VeLINR_Pct_CEXV_PosAct: nonqueued-sender-com-spec{data-element=VeLINR_Pct_CEXV_PosAct, init-value=VeLINR_Pct_CEXV_PosActValue:0}, provided-interface=VeLINR_Pct_CEXV_PosAct
      VeLINR_b_CEXV_PosActTO: nonqueued-sender-com-spec{data-element=VeLINR_b_CEXV_PosActTO, init-value=VeLINR_b_CEXV_PosActTOValue:0}, provided-interface=VeLINR_b_CEXV_PosActTO
      VeLINR_e_CEXV_CalStat: nonqueued-sender-com-spec{data-element=VeLINR_e_CEXV_CalStat, init-value=VeLINR_e_CEXV_CalStatValue:0}, provided-interface=VeLINR_e_CEXV_CalStat
      VeLINR_b_CEXV_CalStatTO: nonqueued-sender-com-spec{data-element=VeLINR_b_CEXV_CalStatTO, init-value=VeLINR_b_CEXV_CalStatTOValue:0}, provided-interface=VeLINR_b_CEXV_CalStatTO
      VeLINR_b_CEXV_CalRq: nonqueued-sender-com-spec{data-element=VeLINR_b_CEXV_CalRq, init-value=VeLINR_b_CEXV_CalRqValue:0}, provided-interface=VeLINR_b_CEXV_CalRq
      VeLINR_b_CEXV_CalRqTO: nonqueued-sender-com-spec{data-element=VeLINR_b_CEXV_CalRqTO, init-value=VeLINR_b_CEXV_CalRqTOValue:0}, provided-interface=VeLINR_b_CEXV_CalRqTO
      VeLINR_b_RsErr_CEXV: nonqueued-sender-com-spec{data-element=VeLINR_b_RsErr_CEXV, init-value=VeLINR_b_RsErr_CEXVValue:0}, provided-interface=VeLINR_b_RsErr_CEXV
      VeLINR_b_RsErr_CEXV_TO: nonqueued-sender-com-spec{data-element=VeLINR_b_RsErr_CEXV_TO, init-value=VeLINR_b_RsErr_CEXV_TOValue:0}, provided-interface=VeLINR_b_RsErr_CEXV_TO
      VeLINR_e_CEXV_Sts: nonqueued-sender-com-spec{data-element=VeLINR_e_CEXV_Sts, init-value=VeLINR_e_CEXV_StsValue:0}, provided-interface=VeLINR_e_CEXV_Sts
      VeLINR_b_CEXV_StsTO: nonqueued-sender-com-spec{data-element=VeLINR_b_CEXV_StsTO, init-value=VeLINR_b_CEXV_StsTOValue:0}, provided-interface=VeLINR_b_CEXV_StsTO
      VeLINR_e_CEXV_ERR: nonqueued-sender-com-spec{data-element=VeLINR_e_CEXV_ERR, init-value=VeLINR_e_CEXV_ERRValue:0}, provided-interface=VeLINR_e_CEXV_ERR
      VeLINR_b_CEXV_ERR_TO: nonqueued-sender-com-spec{data-element=VeLINR_b_CEXV_ERR_TO, init-value=VeLINR_b_CEXV_ERR_TOValue:0}, provided-interface=VeLINR_b_CEXV_ERR_TO
      VeLINR_U_CEXV_SupplyVolt: nonqueued-sender-com-spec{data-element=VeLINR_U_CEXV_SupplyVolt, init-value=VeLINR_U_CEXV_SupplyVoltValue:0}, provided-interface=VeLINR_U_CEXV_SupplyVolt
      VeLINR_b_CEXV_SupplyVoltTO: nonqueued-sender-com-spec{data-element=VeLINR_b_CEXV_SupplyVoltTO, init-value=VeLINR_b_CEXV_SupplyVoltTOValue:0}, provided-interface=VeLINR_b_CEXV_SupplyVoltTO
      VeLINR_e_CEXV_Refrigerant_Press: nonqueued-sender-com-spec{data-element=VeLINR_e_CEXV_Refrigerant_Press, init-value=VeLINR_e_CEXV_Refrigerant_PressValue:1638.3}, provided-interface=VeLINR_e_CEXV_Refrigerant_Press
      VeLINR_b_CEXV_Refrigerant_PressTO: nonqueued-sender-com-spec{data-element=VeLINR_b_CEXV_Refrigerant_PressTO, init-value=VeLINR_b_CEXV_Refrigerant_PressTOValue:0}, provided-interface=VeLINR_b_CEXV_Refrigerant_PressTO
      VeLINR_T_CEXV_Board_Temp: nonqueued-sender-com-spec{data-element=VeLINR_T_CEXV_Board_Temp, init-value=VeLINR_T_CEXV_Board_TempValue:-40}, provided-interface=VeLINR_T_CEXV_Board_Temp
      VeLINR_b_CEXV_Board_TempTO: nonqueued-sender-com-spec{data-element=VeLINR_b_CEXV_Board_TempTO, init-value=VeLINR_b_CEXV_Board_TempTOValue:0}, provided-interface=VeLINR_b_CEXV_Board_TempTO
      VeLINR_e_CEXV_Refrigerant_Temp: nonqueued-sender-com-spec{data-element=VeLINR_e_CEXV_Refrigerant_Temp, init-value=VeLINR_e_CEXV_Refrigerant_TempValue:-40}, provided-interface=VeLINR_e_CEXV_Refrigerant_Temp
      VeLINR_b_CEXV_Refrigerant_TempTO: nonqueued-sender-com-spec{data-element=VeLINR_b_CEXV_Refrigerant_TempTO, init-value=VeLINR_b_CEXV_Refrigerant_TempTOValue:0}, provided-interface=VeLINR_b_CEXV_Refrigerant_TempTO
      VeLINR_e_Inlet_Temp1_DC: nonqueued-sender-com-spec{data-element=VeLINR_e_Inlet_Temp1_DC, init-value=VeLINR_e_Inlet_Temp1_DCValue:-40}, provided-interface=VeLINR_e_Inlet_Temp1_DC
      VeLINR_b_Inlet_Temp1_DC_TO: nonqueued-sender-com-spec{data-element=VeLINR_b_Inlet_Temp1_DC_TO, init-value=VeLINR_b_Inlet_Temp1_DC_TOValue:0}, provided-interface=VeLINR_b_Inlet_Temp1_DC_TO
      VeLINR_e_Inlet_Temp2_DC: nonqueued-sender-com-spec{data-element=VeLINR_e_Inlet_Temp2_DC, init-value=VeLINR_e_Inlet_Temp2_DCValue:-40}, provided-interface=VeLINR_e_Inlet_Temp2_DC
      VeLINR_b_Inlet_Temp2_DC_TO: nonqueued-sender-com-spec{data-element=VeLINR_b_Inlet_Temp2_DC_TO, init-value=VeLINR_b_Inlet_Temp2_DC_TOValue:0}, provided-interface=VeLINR_b_Inlet_Temp2_DC_TO
      VeLINR_e_CPIM_IND1_Fdbk: nonqueued-sender-com-spec{data-element=VeLINR_e_CPIM_IND1_Fdbk, init-value=VeLINR_e_CPIM_IND1_FdbkValue:0}, provided-interface=VeLINR_e_CPIM_IND1_Fdbk
      VeLINR_b_CPIM_IND1_FdbkTO: nonqueued-sender-com-spec{data-element=VeLINR_b_CPIM_IND1_FdbkTO, init-value=VeLINR_b_CPIM_IND1_FdbkTOValue:0}, provided-interface=VeLINR_b_CPIM_IND1_FdbkTO
      VeLINR_e_CPIM_IND2_Fdbk: nonqueued-sender-com-spec{data-element=VeLINR_e_CPIM_IND2_Fdbk, init-value=VeLINR_e_CPIM_IND2_FdbkValue:0}, provided-interface=VeLINR_e_CPIM_IND2_Fdbk
      VeLINR_b_CPIM_IND2_FdbkTO: nonqueued-sender-com-spec{data-element=VeLINR_b_CPIM_IND2_FdbkTO, init-value=VeLINR_b_CPIM_IND2_FdbkTOValue:0}, provided-interface=VeLINR_b_CPIM_IND2_FdbkTO
      VeLINR_e_CPIM_IND3_Fdbk: nonqueued-sender-com-spec{data-element=VeLINR_e_CPIM_IND3_Fdbk, init-value=VeLINR_e_CPIM_IND3_FdbkValue:0}, provided-interface=VeLINR_e_CPIM_IND3_Fdbk
      VeLINR_b_CPIM_IND3_FdbkTO: nonqueued-sender-com-spec{data-element=VeLINR_b_CPIM_IND3_FdbkTO, init-value=VeLINR_b_CPIM_IND3_FdbkTOValue:0}, provided-interface=VeLINR_b_CPIM_IND3_FdbkTO
      VeLINR_e_CPIM_IND4_Fdbk: nonqueued-sender-com-spec{data-element=VeLINR_e_CPIM_IND4_Fdbk, init-value=VeLINR_e_CPIM_IND4_FdbkValue:0}, provided-interface=VeLINR_e_CPIM_IND4_Fdbk
      VeLINR_b_CPIM_IND4_FdbkTO: nonqueued-sender-com-spec{data-element=VeLINR_b_CPIM_IND4_FdbkTO, init-value=VeLINR_b_CPIM_IND4_FdbkTOValue:0}, provided-interface=VeLINR_b_CPIM_IND4_FdbkTO
      VeLINR_e_CPIM_IND5_Fdbk: nonqueued-sender-com-spec{data-element=VeLINR_e_CPIM_IND5_Fdbk, init-value=VeLINR_e_CPIM_IND5_FdbkValue:0}, provided-interface=VeLINR_e_CPIM_IND5_Fdbk
      VeLINR_b_CPIM_IND5_FdbkTO: nonqueued-sender-com-spec{data-element=VeLINR_b_CPIM_IND5_FdbkTO, init-value=VeLINR_b_CPIM_IND5_FdbkTOValue:0}, provided-interface=VeLINR_b_CPIM_IND5_FdbkTO
      VeLINR_e_CPIM_IND_Color_Fdbk: nonqueued-sender-com-spec{data-element=VeLINR_e_CPIM_IND_Color_Fdbk, init-value=VeLINR_e_CPIM_IND_Color_FdbkValue:0}, provided-interface=VeLINR_e_CPIM_IND_Color_Fdbk
      VeLINR_b_CPIM_IND_Color_FdbkTO: nonqueued-sender-com-spec{data-element=VeLINR_b_CPIM_IND_Color_FdbkTO, init-value=VeLINR_b_CPIM_IND_Color_FdbkTOValue:0}, provided-interface=VeLINR_b_CPIM_IND_Color_FdbkTO
      VeLINR_e_CPIM_IND1_FailSts: nonqueued-sender-com-spec{data-element=VeLINR_e_CPIM_IND1_FailSts, init-value=VeLINR_e_CPIM_IND1_FailStsValue:0}, provided-interface=VeLINR_e_CPIM_IND1_FailSts
      VeLINR_b_CPIM_IND1_FailStsTO: nonqueued-sender-com-spec{data-element=VeLINR_b_CPIM_IND1_FailStsTO, init-value=VeLINR_b_CPIM_IND1_FailStsTOValue:0}, provided-interface=VeLINR_b_CPIM_IND1_FailStsTO
      VeLINR_e_CPIM_IND2_FailSts: nonqueued-sender-com-spec{data-element=VeLINR_e_CPIM_IND2_FailSts, init-value=VeLINR_e_CPIM_IND2_FailStsValue:0}, provided-interface=VeLINR_e_CPIM_IND2_FailSts
      VeLINR_b_CPIM_IND2_FailStsTO: nonqueued-sender-com-spec{data-element=VeLINR_b_CPIM_IND2_FailStsTO, init-value=VeLINR_b_CPIM_IND2_FailStsTOValue:0}, provided-interface=VeLINR_b_CPIM_IND2_FailStsTO
      VeLINR_e_CPIM_IND3_FailSts: nonqueued-sender-com-spec{data-element=VeLINR_e_CPIM_IND3_FailSts, init-value=VeLINR_e_CPIM_IND3_FailStsValue:0}, provided-interface=VeLINR_e_CPIM_IND3_FailSts
      VeLINR_b_CPIM_IND3_FailStsTO: nonqueued-sender-com-spec{data-element=VeLINR_b_CPIM_IND3_FailStsTO, init-value=VeLINR_b_CPIM_IND3_FailStsTOValue:0}, provided-interface=VeLINR_b_CPIM_IND3_FailStsTO
      VeLINR_e_CPIM_IND4_FailSts: nonqueued-sender-com-spec{data-element=VeLINR_e_CPIM_IND4_FailSts, init-value=VeLINR_e_CPIM_IND4_FailStsValue:0}, provided-interface=VeLINR_e_CPIM_IND4_FailSts
      VeLINR_b_CPIM_IND4_FailStsTO: nonqueued-sender-com-spec{data-element=VeLINR_b_CPIM_IND4_FailStsTO, init-value=VeLINR_b_CPIM_IND4_FailStsTOValue:0}, provided-interface=VeLINR_b_CPIM_IND4_FailStsTO
      VeLINR_e_CPIM_IND5_FailSts: nonqueued-sender-com-spec{data-element=VeLINR_e_CPIM_IND5_FailSts, init-value=VeLINR_e_CPIM_IND5_FailStsValue:0}, provided-interface=VeLINR_e_CPIM_IND5_FailSts
      VeLINR_b_CPIM_IND5_FailStsTO: nonqueued-sender-com-spec{data-element=VeLINR_b_CPIM_IND5_FailStsTO, init-value=VeLINR_b_CPIM_IND5_FailStsTOValue:0}, provided-interface=VeLINR_b_CPIM_IND5_FailStsTO
      VeLINR_b_CPIM_Undervoltage: nonqueued-sender-com-spec{data-element=VeLINR_b_CPIM_Undervoltage, init-value=VeLINR_b_CPIM_UndervoltageValue:0}, provided-interface=VeLINR_b_CPIM_Undervoltage
      VeLINR_b_CPIM_UndervoltageTO: nonqueued-sender-com-spec{data-element=VeLINR_b_CPIM_UndervoltageTO, init-value=VeLINR_b_CPIM_UndervoltageTOValue:0}, provided-interface=VeLINR_b_CPIM_UndervoltageTO
      VeLINR_b_CPIM_Over_Temperature: nonqueued-sender-com-spec{data-element=VeLINR_b_CPIM_Over_Temperature, init-value=VeLINR_b_CPIM_Over_TemperatureValue:0}, provided-interface=VeLINR_b_CPIM_Over_Temperature
      VeLINR_b_CPIM_Over_TemperatureTO: nonqueued-sender-com-spec{data-element=VeLINR_b_CPIM_Over_TemperatureTO, init-value=VeLINR_b_CPIM_Over_TemperatureTOValue:0}, provided-interface=VeLINR_b_CPIM_Over_TemperatureTO
      VeLINR_b_CPIM_LIN_Parity_Error: nonqueued-sender-com-spec{data-element=VeLINR_b_CPIM_LIN_Parity_Error, init-value=VeLINR_b_CPIM_LIN_Parity_ErrorValue:0}, provided-interface=VeLINR_b_CPIM_LIN_Parity_Error
      VeLINR_b_CPIM_LIN_Parity_ErrorTO: nonqueued-sender-com-spec{data-element=VeLINR_b_CPIM_LIN_Parity_ErrorTO, init-value=VeLINR_b_CPIM_LIN_Parity_ErrorTOValue:0}, provided-interface=VeLINR_b_CPIM_LIN_Parity_ErrorTO
      VeLINR_b_CPIM_LIN_ChecksumError: nonqueued-sender-com-spec{data-element=VeLINR_b_CPIM_LIN_ChecksumError, init-value=VeLINR_b_CPIM_LIN_ChecksumErrorValue:0}, provided-interface=VeLINR_b_CPIM_LIN_ChecksumError
      VeLINR_b_CPIM_LIN_ChecksumErrorTO: nonqueued-sender-com-spec{data-element=VeLINR_b_CPIM_LIN_ChecksumErrorTO, init-value=VeLINR_b_CPIM_LIN_ChecksumErrorTOValue:0}, provided-interface=VeLINR_b_CPIM_LIN_ChecksumErrorTO
      VeLINR_b_CPIM_LIN_Data_Error: nonqueued-sender-com-spec{data-element=VeLINR_b_CPIM_LIN_Data_Error, init-value=VeLINR_b_CPIM_LIN_Data_ErrorValue:0}, provided-interface=VeLINR_b_CPIM_LIN_Data_Error
      VeLINR_b_CPIM_LIN_Data_ErrorTO: nonqueued-sender-com-spec{data-element=VeLINR_b_CPIM_LIN_Data_ErrorTO, init-value=VeLINR_b_CPIM_LIN_Data_ErrorTOValue:0}, provided-interface=VeLINR_b_CPIM_LIN_Data_ErrorTO
      VeLINR_b_ChrgPortLock_Sts: nonqueued-sender-com-spec{data-element=VeLINR_b_ChrgPortLock_Sts, init-value=VeLINR_b_ChrgPortLock_StsValue:0}, provided-interface=VeLINR_b_ChrgPortLock_Sts
      VeLINR_b_ChrgPortLock_StsTO: nonqueued-sender-com-spec{data-element=VeLINR_b_ChrgPortLock_StsTO, init-value=VeLINR_b_ChrgPortLock_StsTOValue:0}, provided-interface=VeLINR_b_ChrgPortLock_StsTO
      VeLINR_b_ChrgPortButton_Sts: nonqueued-sender-com-spec{data-element=VeLINR_b_ChrgPortButton_Sts, init-value=VeLINR_b_ChrgPortButton_StsValue:0}, provided-interface=VeLINR_b_ChrgPortButton_Sts
      VeLINR_b_ChrgPortButton_StsTO: nonqueued-sender-com-spec{data-element=VeLINR_b_ChrgPortButton_StsTO, init-value=VeLINR_b_ChrgPortButton_StsTOValue:0}, provided-interface=VeLINR_b_ChrgPortButton_StsTO
      VeLINR_e_Ambient_Temp: nonqueued-sender-com-spec{data-element=VeLINR_e_Ambient_Temp, init-value=VeLINR_e_Ambient_TempValue:-40}, provided-interface=VeLINR_e_Ambient_Temp
      VeLINR_b_Ambient_TempTO: nonqueued-sender-com-spec{data-element=VeLINR_b_Ambient_TempTO, init-value=VeLINR_b_Ambient_TempTOValue:0}, provided-interface=VeLINR_b_Ambient_TempTO
      VeLINR_e_Chrg_Inlet_Temp: nonqueued-sender-com-spec{data-element=VeLINR_e_Chrg_Inlet_Temp, init-value=VeLINR_e_Chrg_Inlet_TempValue:-40}, provided-interface=VeLINR_e_Chrg_Inlet_Temp
      VeLINR_b_Chrg_Inlet_TempTO: nonqueued-sender-com-spec{data-element=VeLINR_b_Chrg_Inlet_TempTO, init-value=VeLINR_b_Chrg_Inlet_TempTOValue:0}, provided-interface=VeLINR_b_Chrg_Inlet_TempTO
      VeLINR_b_ResponseErrorStsCPIM: nonqueued-sender-com-spec{data-element=VeLINR_b_ResponseErrorStsCPIM, init-value=VeLINR_b_ResponseErrorStsCPIMValue:0}, provided-interface=VeLINR_b_ResponseErrorStsCPIM
      VeLINR_b_ResponseErrorStsCPIM_TO: nonqueued-sender-com-spec{data-element=VeLINR_b_ResponseErrorStsCPIM_TO, init-value=VeLINR_b_ResponseErrorStsCPIM_TOValue:0}, provided-interface=VeLINR_b_ResponseErrorStsCPIM_TO
      VeLINR_e_ChrgPortLock_FailSts: nonqueued-sender-com-spec{data-element=VeLINR_e_ChrgPortLock_FailSts, init-value=VeLINR_e_ChrgPortLock_FailStsValue:0}, provided-interface=VeLINR_e_ChrgPortLock_FailSts
      VeLINR_b_ChrgPortLock_FailStsTO: nonqueued-sender-com-spec{data-element=VeLINR_b_ChrgPortLock_FailStsTO, init-value=VeLINR_b_ChrgPortLock_FailStsTOValue:0}, provided-interface=VeLINR_b_ChrgPortLock_FailStsTO
      VeLINR_e_Icon1_Sts: nonqueued-sender-com-spec{data-element=VeLINR_e_Icon1_Sts, init-value=VeLINR_e_Icon1_StsValue:0}, provided-interface=VeLINR_e_Icon1_Sts
      VeLINR_b_Icon1_StsTO: nonqueued-sender-com-spec{data-element=VeLINR_b_Icon1_StsTO, init-value=VeLINR_b_Icon1_StsTOValue:0}, provided-interface=VeLINR_b_Icon1_StsTO
      VeLINR_b_Icon1_FailSts: nonqueued-sender-com-spec{data-element=VeLINR_b_Icon1_FailSts, init-value=VeLINR_b_Icon1_FailStsValue:0}, provided-interface=VeLINR_b_Icon1_FailSts
      VeLINR_b_Icon1_FailStsTO: nonqueued-sender-com-spec{data-element=VeLINR_b_Icon1_FailStsTO, init-value=VeLINR_b_Icon1_FailStsTOValue:0}, provided-interface=VeLINR_b_Icon1_FailStsTO
      VeLINR_e_Icon2_Sts: nonqueued-sender-com-spec{data-element=VeLINR_e_Icon2_Sts, init-value=VeLINR_e_Icon2_StsValue:0}, provided-interface=VeLINR_e_Icon2_Sts
      VeLINR_b_Icon2_StsTO: nonqueued-sender-com-spec{data-element=VeLINR_b_Icon2_StsTO, init-value=VeLINR_b_Icon2_StsTOValue:0}, provided-interface=VeLINR_b_Icon2_StsTO
      VeLINR_b_Icon2_FailSts: nonqueued-sender-com-spec{data-element=VeLINR_b_Icon2_FailSts, init-value=VeLINR_b_Icon2_FailStsValue:0}, provided-interface=VeLINR_b_Icon2_FailSts
      VeLINR_b_Icon2_FailStsTO: nonqueued-sender-com-spec{data-element=VeLINR_b_Icon2_FailStsTO, init-value=VeLINR_b_Icon2_FailStsTOValue:0}, provided-interface=VeLINR_b_Icon2_FailStsTO
      VeLINR_e_ChrgPortDoor_Sts: nonqueued-sender-com-spec{data-element=VeLINR_e_ChrgPortDoor_Sts, init-value=VeLINR_e_ChrgPortDoor_StsValue:0}, provided-interface=VeLINR_e_ChrgPortDoor_Sts
      VeLINR_b_ChrgPortDoor_StsTO: nonqueued-sender-com-spec{data-element=VeLINR_b_ChrgPortDoor_StsTO, init-value=VeLINR_b_ChrgPortDoor_StsTOValue:0}, provided-interface=VeLINR_b_ChrgPortDoor_StsTO
      VeLINR_e_HvCooltHeatrSts: nonqueued-sender-com-spec{data-element=VeLINR_e_HvCooltHeatrSts, init-value=VeLINR_e_HvCooltHeatrStsValue:0}, provided-interface=VeLINR_e_HvCooltHeatrSts
      VeLINR_b_HvCooltHeatrStsTO: nonqueued-sender-com-spec{data-element=VeLINR_b_HvCooltHeatrStsTO, init-value=VeLINR_b_HvCooltHeatrStsTOValue:0}, provided-interface=VeLINR_b_HvCooltHeatrStsTO
      VeLINR_e_ECH_InterlockStat: nonqueued-sender-com-spec{data-element=VeLINR_e_ECH_InterlockStat, init-value=VeLINR_e_ECH_InterlockStatValue:0}, provided-interface=VeLINR_e_ECH_InterlockStat
      VeLINR_b_ECH_InterlockStatTO: nonqueued-sender-com-spec{data-element=VeLINR_b_ECH_InterlockStatTO, init-value=VeLINR_b_ECH_InterlockStatTOValue:0}, provided-interface=VeLINR_b_ECH_InterlockStatTO
      VeLINR_e_Below_60V: nonqueued-sender-com-spec{data-element=VeLINR_e_Below_60V, init-value=VeLINR_e_Below_60VValue:3}, provided-interface=VeLINR_e_Below_60V
      VeLINR_b_Below_60V_TO: nonqueued-sender-com-spec{data-element=VeLINR_b_Below_60V_TO, init-value=VeLINR_b_Below_60V_TOValue:0}, provided-interface=VeLINR_b_Below_60V_TO
      VeLINR_T_HvCltWtrHtrWtrTInIntk: nonqueued-sender-com-spec{data-element=VeLINR_T_HvCltWtrHtrWtrTInIntk, init-value=VeLINR_T_HvCltWtrHtrWtrTInIntkValue:215}, provided-interface=VeLINR_T_HvCltWtrHtrWtrTInIntk
      VeLINR_b_HvCltWtrHtrWtrTInIntkTO: nonqueued-sender-com-spec{data-element=VeLINR_b_HvCltWtrHtrWtrTInIntkTO, init-value=VeLINR_b_HvCltWtrHtrWtrTInIntkTOValue:0}, provided-interface=VeLINR_b_HvCltWtrHtrWtrTInIntkTO
      VeLINR_T_HvWtrHeatrWtrT: nonqueued-sender-com-spec{data-element=VeLINR_T_HvWtrHeatrWtrT, init-value=VeLINR_T_HvWtrHeatrWtrTValue:215}, provided-interface=VeLINR_T_HvWtrHeatrWtrT
      VeLINR_b_HvWtrHeatrWtrT_TO: nonqueued-sender-com-spec{data-element=VeLINR_b_HvWtrHeatrWtrT_TO, init-value=VeLINR_b_HvWtrHeatrWtrT_TOValue:0}, provided-interface=VeLINR_b_HvWtrHeatrWtrT_TO
      VeLINR_I_HvCooltHeatrICns: nonqueued-sender-com-spec{data-element=VeLINR_I_HvCooltHeatrICns, init-value=VeLINR_I_HvCooltHeatrICnsValue:63.75}, provided-interface=VeLINR_I_HvCooltHeatrICns
      VeLINR_b_HvCooltHeatrICnsTO: nonqueued-sender-com-spec{data-element=VeLINR_b_HvCooltHeatrICnsTO, init-value=VeLINR_b_HvCooltHeatrICnsTOValue:0}, provided-interface=VeLINR_b_HvCooltHeatrICnsTO
      VeLINR_U_HvCooltHVmeas: nonqueued-sender-com-spec{data-element=VeLINR_U_HvCooltHVmeas, init-value=VeLINR_U_HvCooltHVmeasValue:1023}, provided-interface=VeLINR_U_HvCooltHVmeas
      VeLINR_b_HvCooltHVmeasTO: nonqueued-sender-com-spec{data-element=VeLINR_b_HvCooltHVmeasTO, init-value=VeLINR_b_HvCooltHVmeasTOValue:0}, provided-interface=VeLINR_b_HvCooltHVmeasTO
      VeLINR_P_HvHeatrPwrCns: nonqueued-sender-com-spec{data-element=VeLINR_P_HvHeatrPwrCns, init-value=VeLINR_P_HvHeatrPwrCnsValue:20460}, provided-interface=VeLINR_P_HvHeatrPwrCns
      VeLINR_b_HvHeatrPwrCnsTO: nonqueued-sender-com-spec{data-element=VeLINR_b_HvHeatrPwrCnsTO, init-value=VeLINR_b_HvHeatrPwrCnsTOValue:0}, provided-interface=VeLINR_b_HvHeatrPwrCnsTO
      VeLINR_P_HvHeatrPwrCnsDes: nonqueued-sender-com-spec{data-element=VeLINR_P_HvHeatrPwrCnsDes, init-value=VeLINR_P_HvHeatrPwrCnsDesValue:20460}, provided-interface=VeLINR_P_HvHeatrPwrCnsDes
      VeLINR_b_HvHeatrPwrCnsDesTO: nonqueued-sender-com-spec{data-element=VeLINR_b_HvHeatrPwrCnsDesTO, init-value=VeLINR_b_HvHeatrPwrCnsDesTOValue:0}, provided-interface=VeLINR_b_HvHeatrPwrCnsDesTO
      VeLINR_e_HVH_UnlockCounter: nonqueued-sender-com-spec{data-element=VeLINR_e_HVH_UnlockCounter, init-value=VeLINR_e_HVH_UnlockCounterValue:0}, provided-interface=VeLINR_e_HVH_UnlockCounter
      VeLINR_b_HVH_UnlockCounterTO: nonqueued-sender-com-spec{data-element=VeLINR_b_HVH_UnlockCounterTO, init-value=VeLINR_b_HVH_UnlockCounterTOValue:0}, provided-interface=VeLINR_b_HVH_UnlockCounterTO
      VeLINR_b_RsErr_ECH: nonqueued-sender-com-spec{data-element=VeLINR_b_RsErr_ECH, init-value=VeLINR_b_RsErr_ECHValue:0}, provided-interface=VeLINR_b_RsErr_ECH
      VeLINR_b_RsErr_ECH_TO: nonqueued-sender-com-spec{data-element=VeLINR_b_RsErr_ECH_TO, init-value=VeLINR_b_RsErr_ECH_TOValue:0}, provided-interface=VeLINR_b_RsErr_ECH_TO
      VeLINR_e_HvCltHtrWrnFltInCom: nonqueued-sender-com-spec{data-element=VeLINR_e_HvCltHtrWrnFltInCom, init-value=VeLINR_e_HvCltHtrWrnFltInComValue:3}, provided-interface=VeLINR_e_HvCltHtrWrnFltInCom
      VeLINR_b_HvCltHtrWrnFltInComTO: nonqueued-sender-com-spec{data-element=VeLINR_b_HvCltHtrWrnFltInComTO, init-value=VeLINR_b_HvCltHtrWrnFltInComTOValue:0}, provided-interface=VeLINR_b_HvCltHtrWrnFltInComTO
      VeLINR_e_HvCltHtrWrnHvOtOfRng: nonqueued-sender-com-spec{data-element=VeLINR_e_HvCltHtrWrnHvOtOfRng, init-value=VeLINR_e_HvCltHtrWrnHvOtOfRngValue:3}, provided-interface=VeLINR_e_HvCltHtrWrnHvOtOfRng
      VeLINR_b_HvCltHtrWrnHvOtOfRngTO: nonqueued-sender-com-spec{data-element=VeLINR_b_HvCltHtrWrnHvOtOfRngTO, init-value=VeLINR_b_HvCltHtrWrnHvOtOfRngTOValue:0}, provided-interface=VeLINR_b_HvCltHtrWrnHvOtOfRngTO
      VeLINR_e_HvCltHtrWrnULoOtOfRng: nonqueued-sender-com-spec{data-element=VeLINR_e_HvCltHtrWrnULoOtOfRng, init-value=VeLINR_e_HvCltHtrWrnULoOtOfRngValue:3}, provided-interface=VeLINR_e_HvCltHtrWrnULoOtOfRng
      VeLINR_b_HvCltHtrWrnULoOtOfRngTO: nonqueued-sender-com-spec{data-element=VeLINR_b_HvCltHtrWrnULoOtOfRngTO, init-value=VeLINR_b_HvCltHtrWrnULoOtOfRngTOValue:0}, provided-interface=VeLINR_b_HvCltHtrWrnULoOtOfRngTO
      VeLINR_e_HvCltHtrWrnCltTOtOfRng: nonqueued-sender-com-spec{data-element=VeLINR_e_HvCltHtrWrnCltTOtOfRng, init-value=VeLINR_e_HvCltHtrWrnCltTOtOfRngValue:3}, provided-interface=VeLINR_e_HvCltHtrWrnCltTOtOfRng
      VeLINR_b_HvCltHtrWrnCltTOtOfRngTO: nonqueued-sender-com-spec{data-element=VeLINR_b_HvCltHtrWrnCltTOtOfRngTO, init-value=VeLINR_b_HvCltHtrWrnCltTOtOfRngTOValue:0}, provided-interface=VeLINR_b_HvCltHtrWrnCltTOtOfRngTO
      VeLINR_e_HvCltHrPrtnSfTmpHwPrtn: nonqueued-sender-com-spec{data-element=VeLINR_e_HvCltHrPrtnSfTmpHwPrtn, init-value=VeLINR_e_HvCltHrPrtnSfTmpHwPrtnValue:3}, provided-interface=VeLINR_e_HvCltHrPrtnSfTmpHwPrtn
      VeLINR_b_HvCltHrPrtnSfTmpHwPrtnTO: nonqueued-sender-com-spec{data-element=VeLINR_b_HvCltHrPrtnSfTmpHwPrtnTO, init-value=VeLINR_b_HvCltHrPrtnSfTmpHwPrtnTOValue:0}, provided-interface=VeLINR_b_HvCltHrPrtnSfTmpHwPrtnTO
      VeLINR_e_HvCltHrPrtnSfTmpOvrhtg: nonqueued-sender-com-spec{data-element=VeLINR_e_HvCltHrPrtnSfTmpOvrhtg, init-value=VeLINR_e_HvCltHrPrtnSfTmpOvrhtgValue:3}, provided-interface=VeLINR_e_HvCltHrPrtnSfTmpOvrhtg
      VeLINR_b_HvCltHrPrtnSfTmpOvrhtgTO: nonqueued-sender-com-spec{data-element=VeLINR_b_HvCltHrPrtnSfTmpOvrhtgTO, init-value=VeLINR_b_HvCltHrPrtnSfTmpOvrhtgTOValue:0}, provided-interface=VeLINR_b_HvCltHrPrtnSfTmpOvrhtgTO
      VeLINR_e_HClHrSrFtClTInSnFlt: nonqueued-sender-com-spec{data-element=VeLINR_e_HClHrSrFtClTInSnFlt, init-value=VeLINR_e_HClHrSrFtClTInSnFltValue:3}, provided-interface=VeLINR_e_HClHrSrFtClTInSnFlt
      VeLINR_b_HClHrSrFtClTInSnFltTO: nonqueued-sender-com-spec{data-element=VeLINR_b_HClHrSrFtClTInSnFltTO, init-value=VeLINR_b_HClHrSrFtClTInSnFltTOValue:0}, provided-interface=VeLINR_b_HClHrSrFtClTInSnFltTO
      VeLINR_e_HClHrSrFtClTOtSnFlt: nonqueued-sender-com-spec{data-element=VeLINR_e_HClHrSrFtClTOtSnFlt, init-value=VeLINR_e_HClHrSrFtClTOtSnFltValue:3}, provided-interface=VeLINR_e_HClHrSrFtClTOtSnFlt
      VeLINR_b_HClHrSrFtClTOtSnFltTO: nonqueued-sender-com-spec{data-element=VeLINR_b_HClHrSrFtClTOtSnFltTO, init-value=VeLINR_b_HClHrSrFtClTOtSnFltTOValue:0}, provided-interface=VeLINR_b_HClHrSrFtClTOtSnFltTO
      VeLINR_e_HClHrSrFtTInMtrlSnFlt: nonqueued-sender-com-spec{data-element=VeLINR_e_HClHrSrFtTInMtrlSnFlt, init-value=VeLINR_e_HClHrSrFtTInMtrlSnFltValue:3}, provided-interface=VeLINR_e_HClHrSrFtTInMtrlSnFlt
      VeLINR_b_HClHrSrFtTInMtrlSnFltTO: nonqueued-sender-com-spec{data-element=VeLINR_b_HClHrSrFtTInMtrlSnFltTO, init-value=VeLINR_b_HClHrSrFtTInMtrlSnFltTOValue:0}, provided-interface=VeLINR_b_HClHrSrFtTInMtrlSnFltTO
      VeLINR_e_HClHrSrRqCrFrDrShOrOp: nonqueued-sender-com-spec{data-element=VeLINR_e_HClHrSrRqCrFrDrShOrOp, init-value=VeLINR_e_HClHrSrRqCrFrDrShOrOpValue:3}, provided-interface=VeLINR_e_HClHrSrRqCrFrDrShOrOp
      VeLINR_b_HClHrSrRqCrFrDrShOrOpTO: nonqueued-sender-com-spec{data-element=VeLINR_b_HClHrSrRqCrFrDrShOrOpTO, init-value=VeLINR_b_HClHrSrRqCrFrDrShOrOpTOValue:0}, provided-interface=VeLINR_b_HClHrSrRqCrFrDrShOrOpTO
      VeLINR_e_HClHrSrRqICnsOtOfRng: nonqueued-sender-com-spec{data-element=VeLINR_e_HClHrSrRqICnsOtOfRng, init-value=VeLINR_e_HClHrSrRqICnsOtOfRngValue:3}, provided-interface=VeLINR_e_HClHrSrRqICnsOtOfRng
      VeLINR_b_HClHrSrRqICnsOtOfRngTO: nonqueued-sender-com-spec{data-element=VeLINR_b_HClHrSrRqICnsOtOfRngTO, init-value=VeLINR_b_HClHrSrRqICnsOtOfRngTOValue:0}, provided-interface=VeLINR_b_HClHrSrRqICnsOtOfRngTO
      VeLINR_e_HClHrSrRqMemErr: nonqueued-sender-com-spec{data-element=VeLINR_e_HClHrSrRqMemErr, init-value=VeLINR_e_HClHrSrRqMemErrValue:3}, provided-interface=VeLINR_e_HClHrSrRqMemErr
      VeLINR_b_HClHrSrRqMemErrTO: nonqueued-sender-com-spec{data-element=VeLINR_b_HClHrSrRqMemErrTO, init-value=VeLINR_b_HClHrSrRqMemErrTOValue:0}, provided-interface=VeLINR_b_HClHrSrRqMemErrTO
      VeLINR_e_HClHrSrRqSrvRq: nonqueued-sender-com-spec{data-element=VeLINR_e_HClHrSrRqSrvRq, init-value=VeLINR_e_HClHrSrRqSrvRqValue:3}, provided-interface=VeLINR_e_HClHrSrRqSrvRq
      VeLINR_b_HClHrSrRqSrvRqTO: nonqueued-sender-com-spec{data-element=VeLINR_b_HClHrSrRqSrvRqTO, init-value=VeLINR_b_HClHrSrRqSrvRqTOValue:0}, provided-interface=VeLINR_b_HClHrSrRqSrvRqTO
      VeLINR_e_EOPB_RPM_TGT: nonqueued-sender-com-spec{data-element=VeLINR_e_EOPB_RPM_TGT, init-value=VeLINR_e_EOPB_RPM_TGTValue:6120}, provided-interface=VeLINR_e_EOPB_RPM_TGT
      VeLINR_b_EOPB_RPM_TGT_TO: nonqueued-sender-com-spec{data-element=VeLINR_b_EOPB_RPM_TGT_TO, init-value=VeLINR_b_EOPB_RPM_TGT_TOValue:0}, provided-interface=VeLINR_b_EOPB_RPM_TGT_TO
      VeLINR_e_EOPB_RPM_ACTL: nonqueued-sender-com-spec{data-element=VeLINR_e_EOPB_RPM_ACTL, init-value=VeLINR_e_EOPB_RPM_ACTLValue:6120}, provided-interface=VeLINR_e_EOPB_RPM_ACTL
      VeLINR_b_EOPB_RPM_ACTL_TO: nonqueued-sender-com-spec{data-element=VeLINR_b_EOPB_RPM_ACTL_TO, init-value=VeLINR_b_EOPB_RPM_ACTL_TOValue:0}, provided-interface=VeLINR_b_EOPB_RPM_ACTL_TO
      VeLINR_U_EOPB_VLTG: nonqueued-sender-com-spec{data-element=VeLINR_U_EOPB_VLTG, init-value=VeLINR_U_EOPB_VLTGValue:25.5}, provided-interface=VeLINR_U_EOPB_VLTG
      VeLINR_b_EOPB_VLTG_TO: nonqueued-sender-com-spec{data-element=VeLINR_b_EOPB_VLTG_TO, init-value=VeLINR_b_EOPB_VLTG_TOValue:0}, provided-interface=VeLINR_b_EOPB_VLTG_TO
      VeLINR_T_EOPB_TEMP: nonqueued-sender-com-spec{data-element=VeLINR_T_EOPB_TEMP, init-value=VeLINR_T_EOPB_TEMPValue:205}, provided-interface=VeLINR_T_EOPB_TEMP
      VeLINR_b_EOPB_TEMP_TO: nonqueued-sender-com-spec{data-element=VeLINR_b_EOPB_TEMP_TO, init-value=VeLINR_b_EOPB_TEMP_TOValue:0}, provided-interface=VeLINR_b_EOPB_TEMP_TO
      VeLINR_I_EOPB_CURR: nonqueued-sender-com-spec{data-element=VeLINR_I_EOPB_CURR, init-value=VeLINR_I_EOPB_CURRValue:51}, provided-interface=VeLINR_I_EOPB_CURR
      VeLINR_b_EOPB_CURR_TO: nonqueued-sender-com-spec{data-element=VeLINR_b_EOPB_CURR_TO, init-value=VeLINR_b_EOPB_CURR_TOValue:0}, provided-interface=VeLINR_b_EOPB_CURR_TO
      VeLINR_e_EOPB_LOW_TMP_STAT: nonqueued-sender-com-spec{data-element=VeLINR_e_EOPB_LOW_TMP_STAT, init-value=VeLINR_e_EOPB_LOW_TMP_STATValue:3}, provided-interface=VeLINR_e_EOPB_LOW_TMP_STAT
      VeLINR_b_EOPB_LOW_TMP_STAT_TO: nonqueued-sender-com-spec{data-element=VeLINR_b_EOPB_LOW_TMP_STAT_TO, init-value=VeLINR_b_EOPB_LOW_TMP_STAT_TOValue:0}, provided-interface=VeLINR_b_EOPB_LOW_TMP_STAT_TO
      VeLINR_e_EOPB_MONTRNG_RPM: nonqueued-sender-com-spec{data-element=VeLINR_e_EOPB_MONTRNG_RPM, init-value=VeLINR_e_EOPB_MONTRNG_RPMValue:3}, provided-interface=VeLINR_e_EOPB_MONTRNG_RPM
      VeLINR_b_EOPB_MONTRNG_RPM_TO: nonqueued-sender-com-spec{data-element=VeLINR_b_EOPB_MONTRNG_RPM_TO, init-value=VeLINR_b_EOPB_MONTRNG_RPM_TOValue:0}, provided-interface=VeLINR_b_EOPB_MONTRNG_RPM_TO
      VeLINR_e_EOPB_LMP_HM_AN_ON: nonqueued-sender-com-spec{data-element=VeLINR_e_EOPB_LMP_HM_AN_ON, init-value=VeLINR_e_EOPB_LMP_HM_AN_ONValue:3}, provided-interface=VeLINR_e_EOPB_LMP_HM_AN_ON
      VeLINR_b_EOPB_LMP_HM_AN_ON_TO: nonqueued-sender-com-spec{data-element=VeLINR_b_EOPB_LMP_HM_AN_ON_TO, init-value=VeLINR_b_EOPB_LMP_HM_AN_ON_TOValue:0}, provided-interface=VeLINR_b_EOPB_LMP_HM_AN_ON_TO
      VeLINR_e_EOPB_OV_TMP_ER: nonqueued-sender-com-spec{data-element=VeLINR_e_EOPB_OV_TMP_ER, init-value=VeLINR_e_EOPB_OV_TMP_ERValue:3}, provided-interface=VeLINR_e_EOPB_OV_TMP_ER
      VeLINR_b_EOPB_OV_TMP_ER_TO: nonqueued-sender-com-spec{data-element=VeLINR_b_EOPB_OV_TMP_ER_TO, init-value=VeLINR_b_EOPB_OV_TMP_ER_TOValue:0}, provided-interface=VeLINR_b_EOPB_OV_TMP_ER_TO
      VeLINR_e_EOPB_OV_CUR_ER: nonqueued-sender-com-spec{data-element=VeLINR_e_EOPB_OV_CUR_ER, init-value=VeLINR_e_EOPB_OV_CUR_ERValue:3}, provided-interface=VeLINR_e_EOPB_OV_CUR_ER
      VeLINR_b_EOPB_OV_CUR_ER_TO: nonqueued-sender-com-spec{data-element=VeLINR_b_EOPB_OV_CUR_ER_TO, init-value=VeLINR_b_EOPB_OV_CUR_ER_TOValue:0}, provided-interface=VeLINR_b_EOPB_OV_CUR_ER_TO
      VeLINR_e_EOPB_DR_RN_ER: nonqueued-sender-com-spec{data-element=VeLINR_e_EOPB_DR_RN_ER, init-value=VeLINR_e_EOPB_DR_RN_ERValue:3}, provided-interface=VeLINR_e_EOPB_DR_RN_ER
      VeLINR_b_EOPB_DR_RN_ER_TO: nonqueued-sender-com-spec{data-element=VeLINR_b_EOPB_DR_RN_ER_TO, init-value=VeLINR_b_EOPB_DR_RN_ER_TOValue:0}, provided-interface=VeLINR_b_EOPB_DR_RN_ER_TO
      VeLINR_e_EOPB_VLTG_ER: nonqueued-sender-com-spec{data-element=VeLINR_e_EOPB_VLTG_ER, init-value=VeLINR_e_EOPB_VLTG_ERValue:3}, provided-interface=VeLINR_e_EOPB_VLTG_ER
      VeLINR_b_EOPB_VLTG_ER_TO: nonqueued-sender-com-spec{data-element=VeLINR_b_EOPB_VLTG_ER_TO, init-value=VeLINR_b_EOPB_VLTG_ER_TOValue:0}, provided-interface=VeLINR_b_EOPB_VLTG_ER_TO
      VeLINR_e_EOPB_Stall_Event: nonqueued-sender-com-spec{data-element=VeLINR_e_EOPB_Stall_Event, init-value=VeLINR_e_EOPB_Stall_EventValue:3}, provided-interface=VeLINR_e_EOPB_Stall_Event
      VeLINR_b_EOPB_Stall_EventTO: nonqueued-sender-com-spec{data-element=VeLINR_b_EOPB_Stall_EventTO, init-value=VeLINR_b_EOPB_Stall_EventTOValue:0}, provided-interface=VeLINR_b_EOPB_Stall_EventTO
      VeLINR_e_EOPB_POST_RUN_STAT: nonqueued-sender-com-spec{data-element=VeLINR_e_EOPB_POST_RUN_STAT, init-value=VeLINR_e_EOPB_POST_RUN_STATValue:7}, provided-interface=VeLINR_e_EOPB_POST_RUN_STAT
      VeLINR_b_EOPB_POST_RUN_STAT_TO: nonqueued-sender-com-spec{data-element=VeLINR_b_EOPB_POST_RUN_STAT_TO, init-value=VeLINR_b_EOPB_POST_RUN_STAT_TOValue:0}, provided-interface=VeLINR_b_EOPB_POST_RUN_STAT_TO
      VeLINR_b_RsErr_EOPB: nonqueued-sender-com-spec{data-element=VeLINR_b_RsErr_EOPB, init-value=VeLINR_b_RsErr_EOPBValue:0}, provided-interface=VeLINR_b_RsErr_EOPB
      VeLINR_b_RsErr_EOPB_TO: nonqueued-sender-com-spec{data-element=VeLINR_b_RsErr_EOPB_TO, init-value=VeLINR_b_RsErr_EOPB_TOValue:0}, provided-interface=VeLINR_b_RsErr_EOPB_TO
      VeLINR_T_EOPB_OIL_TEMP: nonqueued-sender-com-spec{data-element=VeLINR_T_EOPB_OIL_TEMP, init-value=VeLINR_T_EOPB_OIL_TEMPValue:205}, provided-interface=VeLINR_T_EOPB_OIL_TEMP
      VeLINR_b_EOPB_OIL_TEMP_TO: nonqueued-sender-com-spec{data-element=VeLINR_b_EOPB_OIL_TEMP_TO, init-value=VeLINR_b_EOPB_OIL_TEMP_TOValue:0}, provided-interface=VeLINR_b_EOPB_OIL_TEMP_TO
      VeLINR_y_EOPB_HW_VER: nonqueued-sender-com-spec{data-element=VeLINR_y_EOPB_HW_VER, init-value=VeLINR_y_EOPB_HW_VERValue:255}, provided-interface=VeLINR_y_EOPB_HW_VER
      VeLINR_b_EOPB_HW_VER_TO: nonqueued-sender-com-spec{data-element=VeLINR_b_EOPB_HW_VER_TO, init-value=VeLINR_b_EOPB_HW_VER_TOValue:0}, provided-interface=VeLINR_b_EOPB_HW_VER_TO
      VeLINR_y_EOPB_SW_VER: nonqueued-sender-com-spec{data-element=VeLINR_y_EOPB_SW_VER, init-value=VeLINR_y_EOPB_SW_VERValue:255}, provided-interface=VeLINR_y_EOPB_SW_VER
      VeLINR_b_EOPB_SW_VER_TO: nonqueued-sender-com-spec{data-element=VeLINR_b_EOPB_SW_VER_TO, init-value=VeLINR_b_EOPB_SW_VER_TOValue:0}, provided-interface=VeLINR_b_EOPB_SW_VER_TO
      VeLINR_Pct_HTLBV_PosAct: nonqueued-sender-com-spec{data-element=VeLINR_Pct_HTLBV_PosAct, init-value=VeLINR_Pct_HTLBV_PosActValue:0}, provided-interface=VeLINR_Pct_HTLBV_PosAct
      VeLINR_b_HTLBV_PosActTO: nonqueued-sender-com-spec{data-element=VeLINR_b_HTLBV_PosActTO, init-value=VeLINR_b_HTLBV_PosActTOValue:0}, provided-interface=VeLINR_b_HTLBV_PosActTO
      VeLINR_e_HTLBV_ERR: nonqueued-sender-com-spec{data-element=VeLINR_e_HTLBV_ERR, init-value=VeLINR_e_HTLBV_ERRValue:0}, provided-interface=VeLINR_e_HTLBV_ERR
      VeLINR_b_HTLBV_ERR_TO: nonqueued-sender-com-spec{data-element=VeLINR_b_HTLBV_ERR_TO, init-value=VeLINR_b_HTLBV_ERR_TOValue:0}, provided-interface=VeLINR_b_HTLBV_ERR_TO
      VeLINR_U_HTLBV_MotorVolt: nonqueued-sender-com-spec{data-element=VeLINR_U_HTLBV_MotorVolt, init-value=VeLINR_U_HTLBV_MotorVoltValue:0}, provided-interface=VeLINR_U_HTLBV_MotorVolt
      VeLINR_b_HTLBV_MotorVoltTO: nonqueued-sender-com-spec{data-element=VeLINR_b_HTLBV_MotorVoltTO, init-value=VeLINR_b_HTLBV_MotorVoltTOValue:0}, provided-interface=VeLINR_b_HTLBV_MotorVoltTO
      VeLINR_e_HTLBV_Sts: nonqueued-sender-com-spec{data-element=VeLINR_e_HTLBV_Sts, init-value=VeLINR_e_HTLBV_StsValue:0}, provided-interface=VeLINR_e_HTLBV_Sts
      VeLINR_b_HTLBV_StsTO: nonqueued-sender-com-spec{data-element=VeLINR_b_HTLBV_StsTO, init-value=VeLINR_b_HTLBV_StsTOValue:0}, provided-interface=VeLINR_b_HTLBV_StsTO
      VeLINR_b_RsErr_HTLBV: nonqueued-sender-com-spec{data-element=VeLINR_b_RsErr_HTLBV, init-value=VeLINR_b_RsErr_HTLBVValue:0}, provided-interface=VeLINR_b_RsErr_HTLBV
      VeLINR_b_RsErr_HTLBV_TO: nonqueued-sender-com-spec{data-element=VeLINR_b_RsErr_HTLBV_TO, init-value=VeLINR_b_RsErr_HTLBV_TOValue:0}, provided-interface=VeLINR_b_RsErr_HTLBV_TO
      VeLINR_e_HTLBV_CalStat: nonqueued-sender-com-spec{data-element=VeLINR_e_HTLBV_CalStat, init-value=VeLINR_e_HTLBV_CalStatValue:0}, provided-interface=VeLINR_e_HTLBV_CalStat
      VeLINR_b_HTLBV_CalStatTO: nonqueued-sender-com-spec{data-element=VeLINR_b_HTLBV_CalStatTO, init-value=VeLINR_b_HTLBV_CalStatTOValue:0}, provided-interface=VeLINR_b_HTLBV_CalStatTO
      VeLINR_Pct_PECP2_RPM_TGT_PERCT: nonqueued-sender-com-spec{data-element=VeLINR_Pct_PECP2_RPM_TGT_PERCT, init-value=VeLINR_Pct_PECP2_RPM_TGT_PERCTValue:100.3935}, provided-interface=VeLINR_Pct_PECP2_RPM_TGT_PERCT
      VeLINR_b_PECP2_RPM_TGT_PERCT_TO: nonqueued-sender-com-spec{data-element=VeLINR_b_PECP2_RPM_TGT_PERCT_TO, init-value=VeLINR_b_PECP2_RPM_TGT_PERCT_TOValue:0}, provided-interface=VeLINR_b_PECP2_RPM_TGT_PERCT_TO
      VeLINR_Pct_PECP2_RPM_ACTL_PERCT: nonqueued-sender-com-spec{data-element=VeLINR_Pct_PECP2_RPM_ACTL_PERCT, init-value=VeLINR_Pct_PECP2_RPM_ACTL_PERCTValue:100.3935}, provided-interface=VeLINR_Pct_PECP2_RPM_ACTL_PERCT
      VeLINR_b_PECP2_RPM_ACTL_PERCT_TO: nonqueued-sender-com-spec{data-element=VeLINR_b_PECP2_RPM_ACTL_PERCT_TO, init-value=VeLINR_b_PECP2_RPM_ACTL_PERCT_TOValue:0}, provided-interface=VeLINR_b_PECP2_RPM_ACTL_PERCT_TO
      VeLINR_U_PECP2_VLTG: nonqueued-sender-com-spec{data-element=VeLINR_U_PECP2_VLTG, init-value=VeLINR_U_PECP2_VLTGValue:25.5}, provided-interface=VeLINR_U_PECP2_VLTG
      VeLINR_b_PECP2_VLTG_TO: nonqueued-sender-com-spec{data-element=VeLINR_b_PECP2_VLTG_TO, init-value=VeLINR_b_PECP2_VLTG_TOValue:0}, provided-interface=VeLINR_b_PECP2_VLTG_TO
      VeLINR_T_PECP2_TEMP: nonqueued-sender-com-spec{data-element=VeLINR_T_PECP2_TEMP, init-value=VeLINR_T_PECP2_TEMPValue:205}, provided-interface=VeLINR_T_PECP2_TEMP
      VeLINR_b_PECP2_TEMP_TO: nonqueued-sender-com-spec{data-element=VeLINR_b_PECP2_TEMP_TO, init-value=VeLINR_b_PECP2_TEMP_TOValue:0}, provided-interface=VeLINR_b_PECP2_TEMP_TO
      VeLINR_I_PECP2_CURR: nonqueued-sender-com-spec{data-element=VeLINR_I_PECP2_CURR, init-value=VeLINR_I_PECP2_CURRValue:51}, provided-interface=VeLINR_I_PECP2_CURR
      VeLINR_b_PECP2_CURR_TO: nonqueued-sender-com-spec{data-element=VeLINR_b_PECP2_CURR_TO, init-value=VeLINR_b_PECP2_CURR_TOValue:0}, provided-interface=VeLINR_b_PECP2_CURR_TO
      VeLINR_e_PECP2_FL_SAFE_ACTVTD: nonqueued-sender-com-spec{data-element=VeLINR_e_PECP2_FL_SAFE_ACTVTD, init-value=VeLINR_e_PECP2_FL_SAFE_ACTVTDValue:3}, provided-interface=VeLINR_e_PECP2_FL_SAFE_ACTVTD
      VeLINR_b_PECP2_FL_SAFE_ACTVTD_TO: nonqueued-sender-com-spec{data-element=VeLINR_b_PECP2_FL_SAFE_ACTVTD_TO, init-value=VeLINR_b_PECP2_FL_SAFE_ACTVTD_TOValue:0}, provided-interface=VeLINR_b_PECP2_FL_SAFE_ACTVTD_TO
      VeLINR_e_PECP2_LMP_HM_AN_ON: nonqueued-sender-com-spec{data-element=VeLINR_e_PECP2_LMP_HM_AN_ON, init-value=VeLINR_e_PECP2_LMP_HM_AN_ONValue:3}, provided-interface=VeLINR_e_PECP2_LMP_HM_AN_ON
      VeLINR_b_PECP2_LMP_HM_AN_ON_TO: nonqueued-sender-com-spec{data-element=VeLINR_b_PECP2_LMP_HM_AN_ON_TO, init-value=VeLINR_b_PECP2_LMP_HM_AN_ON_TOValue:0}, provided-interface=VeLINR_b_PECP2_LMP_HM_AN_ON_TO
      VeLINR_e_PECP2_AIR_PRE_ERR: nonqueued-sender-com-spec{data-element=VeLINR_e_PECP2_AIR_PRE_ERR, init-value=VeLINR_e_PECP2_AIR_PRE_ERRValue:3}, provided-interface=VeLINR_e_PECP2_AIR_PRE_ERR
      VeLINR_b_PECP2_AIR_PRE_ERR_TO: nonqueued-sender-com-spec{data-element=VeLINR_b_PECP2_AIR_PRE_ERR_TO, init-value=VeLINR_b_PECP2_AIR_PRE_ERR_TOValue:0}, provided-interface=VeLINR_b_PECP2_AIR_PRE_ERR_TO
      VeLINR_e_PECP2_OVR_TMP_ERR: nonqueued-sender-com-spec{data-element=VeLINR_e_PECP2_OVR_TMP_ERR, init-value=VeLINR_e_PECP2_OVR_TMP_ERRValue:3}, provided-interface=VeLINR_e_PECP2_OVR_TMP_ERR
      VeLINR_b_PECP2_OVR_TMP_ERR_TO: nonqueued-sender-com-spec{data-element=VeLINR_b_PECP2_OVR_TMP_ERR_TO, init-value=VeLINR_b_PECP2_OVR_TMP_ERR_TOValue:0}, provided-interface=VeLINR_b_PECP2_OVR_TMP_ERR_TO
      VeLINR_e_PECP2_OVR_CUR_ERR: nonqueued-sender-com-spec{data-element=VeLINR_e_PECP2_OVR_CUR_ERR, init-value=VeLINR_e_PECP2_OVR_CUR_ERRValue:3}, provided-interface=VeLINR_e_PECP2_OVR_CUR_ERR
      VeLINR_b_PECP2_OVR_CUR_ERR_TO: nonqueued-sender-com-spec{data-element=VeLINR_b_PECP2_OVR_CUR_ERR_TO, init-value=VeLINR_b_PECP2_OVR_CUR_ERR_TOValue:0}, provided-interface=VeLINR_b_PECP2_OVR_CUR_ERR_TO
      VeLINR_e_PECP2_DR_RN_ERR: nonqueued-sender-com-spec{data-element=VeLINR_e_PECP2_DR_RN_ERR, init-value=VeLINR_e_PECP2_DR_RN_ERRValue:3}, provided-interface=VeLINR_e_PECP2_DR_RN_ERR
      VeLINR_b_PECP2_DR_RN_ERR_TO: nonqueued-sender-com-spec{data-element=VeLINR_b_PECP2_DR_RN_ERR_TO, init-value=VeLINR_b_PECP2_DR_RN_ERR_TOValue:0}, provided-interface=VeLINR_b_PECP2_DR_RN_ERR_TO
      VeLINR_e_PECP2_VLTG_ERR: nonqueued-sender-com-spec{data-element=VeLINR_e_PECP2_VLTG_ERR, init-value=VeLINR_e_PECP2_VLTG_ERRValue:3}, provided-interface=VeLINR_e_PECP2_VLTG_ERR
      VeLINR_b_PECP2_VLTG_ERR_TO: nonqueued-sender-com-spec{data-element=VeLINR_b_PECP2_VLTG_ERR_TO, init-value=VeLINR_b_PECP2_VLTG_ERR_TOValue:0}, provided-interface=VeLINR_b_PECP2_VLTG_ERR_TO
      VeLINR_e_PECP2_DBLK_ACTV: nonqueued-sender-com-spec{data-element=VeLINR_e_PECP2_DBLK_ACTV, init-value=VeLINR_e_PECP2_DBLK_ACTVValue:3}, provided-interface=VeLINR_e_PECP2_DBLK_ACTV
      VeLINR_b_PECP2_DBLK_ACTV_TO: nonqueued-sender-com-spec{data-element=VeLINR_b_PECP2_DBLK_ACTV_TO, init-value=VeLINR_b_PECP2_DBLK_ACTV_TOValue:0}, provided-interface=VeLINR_b_PECP2_DBLK_ACTV_TO
      VeLINR_e_PECP2_MONTRNG_RPM: nonqueued-sender-com-spec{data-element=VeLINR_e_PECP2_MONTRNG_RPM, init-value=VeLINR_e_PECP2_MONTRNG_RPMValue:3}, provided-interface=VeLINR_e_PECP2_MONTRNG_RPM
      VeLINR_b_PECP2_MONTRNG_RPM_TO: nonqueued-sender-com-spec{data-element=VeLINR_b_PECP2_MONTRNG_RPM_TO, init-value=VeLINR_b_PECP2_MONTRNG_RPM_TOValue:0}, provided-interface=VeLINR_b_PECP2_MONTRNG_RPM_TO
      VeLINR_e_PECP2_NODE_ERR: nonqueued-sender-com-spec{data-element=VeLINR_e_PECP2_NODE_ERR, init-value=VeLINR_e_PECP2_NODE_ERRValue:3}, provided-interface=VeLINR_e_PECP2_NODE_ERR
      VeLINR_b_PECP2_NODE_ERR_TO: nonqueued-sender-com-spec{data-element=VeLINR_b_PECP2_NODE_ERR_TO, init-value=VeLINR_b_PECP2_NODE_ERR_TOValue:0}, provided-interface=VeLINR_b_PECP2_NODE_ERR_TO
      VeLINR_e_PECP2_POST_RUN_STAT: nonqueued-sender-com-spec{data-element=VeLINR_e_PECP2_POST_RUN_STAT, init-value=VeLINR_e_PECP2_POST_RUN_STATValue:7}, provided-interface=VeLINR_e_PECP2_POST_RUN_STAT
      VeLINR_b_PECP2_POST_RUN_STAT_TO: nonqueued-sender-com-spec{data-element=VeLINR_b_PECP2_POST_RUN_STAT_TO, init-value=VeLINR_b_PECP2_POST_RUN_STAT_TOValue:0}, provided-interface=VeLINR_b_PECP2_POST_RUN_STAT_TO
      VeLINR_b_RsErr_PECP2_PUMP: nonqueued-sender-com-spec{data-element=VeLINR_b_RsErr_PECP2_PUMP, init-value=VeLINR_b_RsErr_PECP2_PUMPValue:0}, provided-interface=VeLINR_b_RsErr_PECP2_PUMP
      VeLINR_b_RsErr_PECP2_PUMP_TO: nonqueued-sender-com-spec{data-element=VeLINR_b_RsErr_PECP2_PUMP_TO, init-value=VeLINR_b_RsErr_PECP2_PUMP_TOValue:0}, provided-interface=VeLINR_b_RsErr_PECP2_PUMP_TO
      VeLINR_y_PECP2_VERSION: nonqueued-sender-com-spec{data-element=VeLINR_y_PECP2_VERSION, init-value=VeLINR_y_PECP2_VERSIONValue:255}, provided-interface=VeLINR_y_PECP2_VERSION
      VeLINR_b_PECP2_VERSION_TO: nonqueued-sender-com-spec{data-element=VeLINR_b_PECP2_VERSION_TO, init-value=VeLINR_b_PECP2_VERSION_TOValue:0}, provided-interface=VeLINR_b_PECP2_VERSION_TO
      VeLINR_e_PECP2_SUPPLIER: nonqueued-sender-com-spec{data-element=VeLINR_e_PECP2_SUPPLIER, init-value=VeLINR_e_PECP2_SUPPLIERValue:0}, provided-interface=VeLINR_e_PECP2_SUPPLIER
      VeLINR_b_PECP2_SUPPLIER_TO: nonqueued-sender-com-spec{data-element=VeLINR_b_PECP2_SUPPLIER_TO, init-value=VeLINR_b_PECP2_SUPPLIER_TOValue:0}, provided-interface=VeLINR_b_PECP2_SUPPLIER_TO
      VeLINR_b_PowerPanel2ButtonState: nonqueued-sender-com-spec{data-element=VeLINR_b_PowerPanel2ButtonState, init-value=VeLINR_b_PowerPanel2ButtonStateValue:0}, provided-interface=VeLINR_b_PowerPanel2ButtonState
      VeLINR_b_PowerPanel2ButtonStateTO: nonqueued-sender-com-spec{data-element=VeLINR_b_PowerPanel2ButtonStateTO, init-value=VeLINR_b_PowerPanel2ButtonStateTOValue:0}, provided-interface=VeLINR_b_PowerPanel2ButtonStateTO
      VeLINR_b_PwrPanel2LidSwtSts120A: nonqueued-sender-com-spec{data-element=VeLINR_b_PwrPanel2LidSwtSts120A, init-value=VeLINR_b_PwrPanel2LidSwtSts120AValue:0}, provided-interface=VeLINR_b_PwrPanel2LidSwtSts120A
      VeLINR_b_PwrPanel2LidSwtSts120A_TO: nonqueued-sender-com-spec{data-element=VeLINR_b_PwrPanel2LidSwtSts120A_TO, init-value=VeLINR_b_PwrPanel2LidSwtSts120A_TOValue:0}, provided-interface=VeLINR_b_PwrPanel2LidSwtSts120A_TO
      VeLINR_b_PwrPanel2LidSwtSts120B: nonqueued-sender-com-spec{data-element=VeLINR_b_PwrPanel2LidSwtSts120B, init-value=VeLINR_b_PwrPanel2LidSwtSts120BValue:0}, provided-interface=VeLINR_b_PwrPanel2LidSwtSts120B
      VeLINR_b_PwrPanel2LidSwtSts120B_TO: nonqueued-sender-com-spec{data-element=VeLINR_b_PwrPanel2LidSwtSts120B_TO, init-value=VeLINR_b_PwrPanel2LidSwtSts120B_TOValue:0}, provided-interface=VeLINR_b_PwrPanel2LidSwtSts120B_TO
      VeLINR_b_PwrPanel2LidSwtSts240: nonqueued-sender-com-spec{data-element=VeLINR_b_PwrPanel2LidSwtSts240, init-value=VeLINR_b_PwrPanel2LidSwtSts240Value:0}, provided-interface=VeLINR_b_PwrPanel2LidSwtSts240
      VeLINR_b_PwrPanel2LidSwtSts240TO: nonqueued-sender-com-spec{data-element=VeLINR_b_PwrPanel2LidSwtSts240TO, init-value=VeLINR_b_PwrPanel2LidSwtSts240TOValue:0}, provided-interface=VeLINR_b_PwrPanel2LidSwtSts240TO
      VeLINR_b_PwrPanel2AC_PrsntSens1: nonqueued-sender-com-spec{data-element=VeLINR_b_PwrPanel2AC_PrsntSens1, init-value=VeLINR_b_PwrPanel2AC_PrsntSens1Value:0}, provided-interface=VeLINR_b_PwrPanel2AC_PrsntSens1
      VeLINR_b_PwrPanel2AC_PrsntSens1TO: nonqueued-sender-com-spec{data-element=VeLINR_b_PwrPanel2AC_PrsntSens1TO, init-value=VeLINR_b_PwrPanel2AC_PrsntSens1TOValue:0}, provided-interface=VeLINR_b_PwrPanel2AC_PrsntSens1TO
      VeLINR_b_PwrPanel2AC_PrsntSens2: nonqueued-sender-com-spec{data-element=VeLINR_b_PwrPanel2AC_PrsntSens2, init-value=VeLINR_b_PwrPanel2AC_PrsntSens2Value:0}, provided-interface=VeLINR_b_PwrPanel2AC_PrsntSens2
      VeLINR_b_PwrPanel2AC_PrsntSens2TO: nonqueued-sender-com-spec{data-element=VeLINR_b_PwrPanel2AC_PrsntSens2TO, init-value=VeLINR_b_PwrPanel2AC_PrsntSens2TOValue:0}, provided-interface=VeLINR_b_PwrPanel2AC_PrsntSens2TO
      VeLINR_e_PwrPanel2_Fault_Reason: nonqueued-sender-com-spec{data-element=VeLINR_e_PwrPanel2_Fault_Reason, init-value=VeLINR_e_PwrPanel2_Fault_ReasonValue:0}, provided-interface=VeLINR_e_PwrPanel2_Fault_Reason
      VeLINR_b_PwrPanel2_Fault_ReasonTO: nonqueued-sender-com-spec{data-element=VeLINR_b_PwrPanel2_Fault_ReasonTO, init-value=VeLINR_b_PwrPanel2_Fault_ReasonTOValue:0}, provided-interface=VeLINR_b_PwrPanel2_Fault_ReasonTO
      VeLINR_b_RsErr_SPP2: nonqueued-sender-com-spec{data-element=VeLINR_b_RsErr_SPP2, init-value=VeLINR_b_RsErr_SPP2Value:0}, provided-interface=VeLINR_b_RsErr_SPP2
      VeLINR_b_RsErr_SPP2TO: nonqueued-sender-com-spec{data-element=VeLINR_b_RsErr_SPP2TO, init-value=VeLINR_b_RsErr_SPP2TOValue:0}, provided-interface=VeLINR_b_RsErr_SPP2TO
    80 x require port:
      SendLINR_AGS_PosRq: nonqueued-receiver-com-spec{data-element=SendLINR_AGS_PosRq, init-value=SendLINR_AGS_PosRqValue:0}, required-interface=SendLINR_AGS_PosRq
      SendLINR_AGS_PosRqVld: nonqueued-receiver-com-spec{data-element=SendLINR_AGS_PosRqVld, init-value=SendLINR_AGS_PosRqVldValue:1}, required-interface=SendLINR_AGS_PosRqVld
      SendLINR_AGS_CalRq: nonqueued-receiver-com-spec{data-element=SendLINR_AGS_CalRq, init-value=SendLINR_AGS_CalRqValue:0}, required-interface=SendLINR_AGS_CalRq
      SendLINR_AGS_CalRqVld: nonqueued-receiver-com-spec{data-element=SendLINR_AGS_CalRqVld, init-value=SendLINR_AGS_CalRqVldValue:1}, required-interface=SendLINR_AGS_CalRqVld
      SendLINR_AGS_BoostRq: nonqueued-receiver-com-spec{data-element=SendLINR_AGS_BoostRq, init-value=SendLINR_AGS_BoostRqValue:0}, required-interface=SendLINR_AGS_BoostRq
      SendLINR_AGS_BoostRqVld: nonqueued-receiver-com-spec{data-element=SendLINR_AGS_BoostRqVld, init-value=SendLINR_AGS_BoostRqVldValue:1}, required-interface=SendLINR_AGS_BoostRqVld
      SendLINR_M2SRes2Bit: nonqueued-receiver-com-spec{data-element=SendLINR_M2SRes2Bit, init-value=SendLINR_M2SRes2BitValue:0}, required-interface=SendLINR_M2SRes2Bit
      SendLINR_M2SRes2BitVld: nonqueued-receiver-com-spec{data-element=SendLINR_M2SRes2BitVld, init-value=SendLINR_M2SRes2BitVldValue:1}, required-interface=SendLINR_M2SRes2BitVld
      SendLINR_M2SResByte1: nonqueued-receiver-com-spec{data-element=SendLINR_M2SResByte1, init-value=SendLINR_M2SResByte1Value:0}, required-interface=SendLINR_M2SResByte1
      SendLINR_M2SResByte1Vld: nonqueued-receiver-com-spec{data-element=SendLINR_M2SResByte1Vld, init-value=SendLINR_M2SResByte1VldValue:1}, required-interface=SendLINR_M2SResByte1Vld
      SendLINR_M2SResByte2: nonqueued-receiver-com-spec{data-element=SendLINR_M2SResByte2, init-value=SendLINR_M2SResByte2Value:0}, required-interface=SendLINR_M2SResByte2
      SendLINR_M2SResByte2Vld: nonqueued-receiver-com-spec{data-element=SendLINR_M2SResByte2Vld, init-value=SendLINR_M2SResByte2VldValue:1}, required-interface=SendLINR_M2SResByte2Vld
      SendLINR_M2SResByte3: nonqueued-receiver-com-spec{data-element=SendLINR_M2SResByte3, init-value=SendLINR_M2SResByte3Value:0}, required-interface=SendLINR_M2SResByte3
      SendLINR_M2SResByte3Vld: nonqueued-receiver-com-spec{data-element=SendLINR_M2SResByte3Vld, init-value=SendLINR_M2SResByte3VldValue:1}, required-interface=SendLINR_M2SResByte3Vld
      SendLINR_CEXV_PosRq: nonqueued-receiver-com-spec{data-element=SendLINR_CEXV_PosRq, init-value=SendLINR_CEXV_PosRqValue:0}, required-interface=SendLINR_CEXV_PosRq
      SendLINR_CEXV_PosRqVld: nonqueued-receiver-com-spec{data-element=SendLINR_CEXV_PosRqVld, init-value=SendLINR_CEXV_PosRqVldValue:1}, required-interface=SendLINR_CEXV_PosRqVld
      SendLINR_CEXV_CalCmd: nonqueued-receiver-com-spec{data-element=SendLINR_CEXV_CalCmd, init-value=SendLINR_CEXV_CalCmdValue:0}, required-interface=SendLINR_CEXV_CalCmd
      SendLINR_CEXV_CalCmdVld: nonqueued-receiver-com-spec{data-element=SendLINR_CEXV_CalCmdVld, init-value=SendLINR_CEXV_CalCmdVldValue:1}, required-interface=SendLINR_CEXV_CalCmdVld
      SendLINR_CPIM_SET_IND1: nonqueued-receiver-com-spec{data-element=SendLINR_CPIM_SET_IND1, init-value=SendLINR_CPIM_SET_IND1Value:0}, required-interface=SendLINR_CPIM_SET_IND1
      SendLINR_CPIM_SET_IND1Vld: nonqueued-receiver-com-spec{data-element=SendLINR_CPIM_SET_IND1Vld, init-value=SendLINR_CPIM_SET_IND1VldValue:1}, required-interface=SendLINR_CPIM_SET_IND1Vld
      SendLINR_CPIM_SET_IND2: nonqueued-receiver-com-spec{data-element=SendLINR_CPIM_SET_IND2, init-value=SendLINR_CPIM_SET_IND2Value:0}, required-interface=SendLINR_CPIM_SET_IND2
      SendLINR_CPIM_SET_IND2Vld: nonqueued-receiver-com-spec{data-element=SendLINR_CPIM_SET_IND2Vld, init-value=SendLINR_CPIM_SET_IND2VldValue:1}, required-interface=SendLINR_CPIM_SET_IND2Vld
      SendLINR_CPIM_SET_IND3: nonqueued-receiver-com-spec{data-element=SendLINR_CPIM_SET_IND3, init-value=SendLINR_CPIM_SET_IND3Value:0}, required-interface=SendLINR_CPIM_SET_IND3
      SendLINR_CPIM_SET_IND3Vld: nonqueued-receiver-com-spec{data-element=SendLINR_CPIM_SET_IND3Vld, init-value=SendLINR_CPIM_SET_IND3VldValue:1}, required-interface=SendLINR_CPIM_SET_IND3Vld
      SendLINR_CPIM_SET_IND4: nonqueued-receiver-com-spec{data-element=SendLINR_CPIM_SET_IND4, init-value=SendLINR_CPIM_SET_IND4Value:0}, required-interface=SendLINR_CPIM_SET_IND4
      SendLINR_CPIM_SET_IND4Vld: nonqueued-receiver-com-spec{data-element=SendLINR_CPIM_SET_IND4Vld, init-value=SendLINR_CPIM_SET_IND4VldValue:1}, required-interface=SendLINR_CPIM_SET_IND4Vld
      SendLINR_CPIM_SET_IND5: nonqueued-receiver-com-spec{data-element=SendLINR_CPIM_SET_IND5, init-value=SendLINR_CPIM_SET_IND5Value:0}, required-interface=SendLINR_CPIM_SET_IND5
      SendLINR_CPIM_SET_IND5Vld: nonqueued-receiver-com-spec{data-element=SendLINR_CPIM_SET_IND5Vld, init-value=SendLINR_CPIM_SET_IND5VldValue:1}, required-interface=SendLINR_CPIM_SET_IND5Vld
      SendLINR_CPIM_Blink_Rate: nonqueued-receiver-com-spec{data-element=SendLINR_CPIM_Blink_Rate, init-value=SendLINR_CPIM_Blink_RateValue:0}, required-interface=SendLINR_CPIM_Blink_Rate
      SendLINR_CPIM_Blink_RateVld: nonqueued-receiver-com-spec{data-element=SendLINR_CPIM_Blink_RateVld, init-value=SendLINR_CPIM_Blink_RateVldValue:1}, required-interface=SendLINR_CPIM_Blink_RateVld
      SendLINR_CPIM_IND_Color: nonqueued-receiver-com-spec{data-element=SendLINR_CPIM_IND_Color, init-value=SendLINR_CPIM_IND_ColorValue:0}, required-interface=SendLINR_CPIM_IND_Color
      SendLINR_CPIM_IND_ColorVld: nonqueued-receiver-com-spec{data-element=SendLINR_CPIM_IND_ColorVld, init-value=SendLINR_CPIM_IND_ColorVldValue:1}, required-interface=SendLINR_CPIM_IND_ColorVld
      SendLINR_ChrgPortLock_Cmd: nonqueued-receiver-com-spec{data-element=SendLINR_ChrgPortLock_Cmd, init-value=SendLINR_ChrgPortLock_CmdValue:0}, required-interface=SendLINR_ChrgPortLock_Cmd
      SendLINR_ChrgPortLock_CmdVld: nonqueued-receiver-com-spec{data-element=SendLINR_ChrgPortLock_CmdVld, init-value=SendLINR_ChrgPortLock_CmdVldValue:1}, required-interface=SendLINR_ChrgPortLock_CmdVld
      SendLINR_Set_Icon1_cmd: nonqueued-receiver-com-spec{data-element=SendLINR_Set_Icon1_cmd, init-value=SendLINR_Set_Icon1_cmdValue:0}, required-interface=SendLINR_Set_Icon1_cmd
      SendLINR_Set_Icon1_cmdVld: nonqueued-receiver-com-spec{data-element=SendLINR_Set_Icon1_cmdVld, init-value=SendLINR_Set_Icon1_cmdVldValue:1}, required-interface=SendLINR_Set_Icon1_cmdVld
      SendLINR_Set_Icon2_cmd: nonqueued-receiver-com-spec{data-element=SendLINR_Set_Icon2_cmd, init-value=SendLINR_Set_Icon2_cmdValue:0}, required-interface=SendLINR_Set_Icon2_cmd
      SendLINR_Set_Icon2_cmdVld: nonqueued-receiver-com-spec{data-element=SendLINR_Set_Icon2_cmdVld, init-value=SendLINR_Set_Icon2_cmdVldValue:1}, required-interface=SendLINR_Set_Icon2_cmdVld
      SendLINR_DAY_LGT_MD_CPIM: nonqueued-receiver-com-spec{data-element=SendLINR_DAY_LGT_MD_CPIM, init-value=SendLINR_DAY_LGT_MD_CPIMValue:0}, required-interface=SendLINR_DAY_LGT_MD_CPIM
      SendLINR_DAY_LGT_MD_CPIM_Vld: nonqueued-receiver-com-spec{data-element=SendLINR_DAY_LGT_MD_CPIM_Vld, init-value=SendLINR_DAY_LGT_MD_CPIM_VldValue:1}, required-interface=SendLINR_DAY_LGT_MD_CPIM_Vld
      SendLINR_Backlight_Cmd: nonqueued-receiver-com-spec{data-element=SendLINR_Backlight_Cmd, init-value=SendLINR_Backlight_CmdValue:0}, required-interface=SendLINR_Backlight_Cmd
      SendLINR_Backlight_CmdVld: nonqueued-receiver-com-spec{data-element=SendLINR_Backlight_CmdVld, init-value=SendLINR_Backlight_CmdVldValue:1}, required-interface=SendLINR_Backlight_CmdVld
      SendLINR_HvWtrHeatrPwrCnsAllwd: nonqueued-receiver-com-spec{data-element=SendLINR_HvWtrHeatrPwrCnsAllwd, init-value=SendLINR_HvWtrHeatrPwrCnsAllwdValue:10200}, required-interface=SendLINR_HvWtrHeatrPwrCnsAllwd
      SendLINR_HvWtrHeatrPwrCnsAllwdVld: nonqueued-receiver-com-spec{data-element=SendLINR_HvWtrHeatrPwrCnsAllwdVld, init-value=SendLINR_HvWtrHeatrPwrCnsAllwdVldValue:1}, required-interface=SendLINR_HvWtrHeatrPwrCnsAllwdVld
      SendLINR_HvWtrHeatrWtrTDes: nonqueued-receiver-com-spec{data-element=SendLINR_HvWtrHeatrWtrTDes, init-value=SendLINR_HvWtrHeatrWtrTDesValue:215}, required-interface=SendLINR_HvWtrHeatrWtrTDes
      SendLINR_HvWtrHeatrWtrTDesVld: nonqueued-receiver-com-spec{data-element=SendLINR_HvWtrHeatrWtrTDesVld, init-value=SendLINR_HvWtrHeatrWtrTDesVldValue:1}, required-interface=SendLINR_HvWtrHeatrWtrTDesVld
      SendLINR_HvCooltHeatrEnad: nonqueued-receiver-com-spec{data-element=SendLINR_HvCooltHeatrEnad, init-value=SendLINR_HvCooltHeatrEnadValue:0}, required-interface=SendLINR_HvCooltHeatrEnad
      SendLINR_HvCooltHeatrEnadVld: nonqueued-receiver-com-spec{data-element=SendLINR_HvCooltHeatrEnadVld, init-value=SendLINR_HvCooltHeatrEnadVldValue:1}, required-interface=SendLINR_HvCooltHeatrEnadVld
      SendLINR_HVH_OverheatUnlock: nonqueued-receiver-com-spec{data-element=SendLINR_HVH_OverheatUnlock, init-value=SendLINR_HVH_OverheatUnlockValue:0}, required-interface=SendLINR_HVH_OverheatUnlock
      SendLINR_HVH_OverheatUnlockVld: nonqueued-receiver-com-spec{data-element=SendLINR_HVH_OverheatUnlockVld, init-value=SendLINR_HVH_OverheatUnlockVldValue:1}, required-interface=SendLINR_HVH_OverheatUnlockVld
      SendLINR_EOPB_RPM_COM: nonqueued-receiver-com-spec{data-element=SendLINR_EOPB_RPM_COM, init-value=SendLINR_EOPB_RPM_COMValue:6120}, required-interface=SendLINR_EOPB_RPM_COM
      SendLINR_EOPB_RPM_COM_Vld: nonqueued-receiver-com-spec{data-element=SendLINR_EOPB_RPM_COM_Vld, init-value=SendLINR_EOPB_RPM_COM_VldValue:1}, required-interface=SendLINR_EOPB_RPM_COM_Vld
      SendLINR_EOPB_POST_RUN_COM: nonqueued-receiver-com-spec{data-element=SendLINR_EOPB_POST_RUN_COM, init-value=SendLINR_EOPB_POST_RUN_COMValue:7}, required-interface=SendLINR_EOPB_POST_RUN_COM
      SendLINR_EOPB_POST_RUN_COM_Vld: nonqueued-receiver-com-spec{data-element=SendLINR_EOPB_POST_RUN_COM_Vld, init-value=SendLINR_EOPB_POST_RUN_COM_VldValue:1}, required-interface=SendLINR_EOPB_POST_RUN_COM_Vld
      SendLINR_HTLBV_PosRq: nonqueued-receiver-com-spec{data-element=SendLINR_HTLBV_PosRq, init-value=SendLINR_HTLBV_PosRqValue:0}, required-interface=SendLINR_HTLBV_PosRq
      SendLINR_HTLBV_PosRqVld: nonqueued-receiver-com-spec{data-element=SendLINR_HTLBV_PosRqVld, init-value=SendLINR_HTLBV_PosRqVldValue:1}, required-interface=SendLINR_HTLBV_PosRqVld
      SendLINR_HTLBV_PosSv: nonqueued-receiver-com-spec{data-element=SendLINR_HTLBV_PosSv, init-value=SendLINR_HTLBV_PosSvValue:0}, required-interface=SendLINR_HTLBV_PosSv
      SendLINR_HTLBV_PosSvVld: nonqueued-receiver-com-spec{data-element=SendLINR_HTLBV_PosSvVld, init-value=SendLINR_HTLBV_PosSvVldValue:1}, required-interface=SendLINR_HTLBV_PosSvVld
      SendLINR_HTLBV_CalRq: nonqueued-receiver-com-spec{data-element=SendLINR_HTLBV_CalRq, init-value=SendLINR_HTLBV_CalRqValue:0}, required-interface=SendLINR_HTLBV_CalRq
      SendLINR_HTLBV_CalRqVld: nonqueued-receiver-com-spec{data-element=SendLINR_HTLBV_CalRqVld, init-value=SendLINR_HTLBV_CalRqVldValue:1}, required-interface=SendLINR_HTLBV_CalRqVld
      SendLINR_PECP2_RPM_REQ_PERCT: nonqueued-receiver-com-spec{data-element=SendLINR_PECP2_RPM_REQ_PERCT, init-value=SendLINR_PECP2_RPM_REQ_PERCTValue:100.3935}, required-interface=SendLINR_PECP2_RPM_REQ_PERCT
      SendLINR_PECP2_RPM_REQ_PERCT_Vld: nonqueued-receiver-com-spec{data-element=SendLINR_PECP2_RPM_REQ_PERCT_Vld, init-value=SendLINR_PECP2_RPM_REQ_PERCT_VldValue:1}, required-interface=SendLINR_PECP2_RPM_REQ_PERCT_Vld
      SendLINR_PECP2_POST_RUN_REQ: nonqueued-receiver-com-spec{data-element=SendLINR_PECP2_POST_RUN_REQ, init-value=SendLINR_PECP2_POST_RUN_REQValue:7}, required-interface=SendLINR_PECP2_POST_RUN_REQ
      SendLINR_PECP2_POST_RUN_REQ_Vld: nonqueued-receiver-com-spec{data-element=SendLINR_PECP2_POST_RUN_REQ_Vld, init-value=SendLINR_PECP2_POST_RUN_REQ_VldValue:1}, required-interface=SendLINR_PECP2_POST_RUN_REQ_Vld
      SendLINR_PECP2_FL_SAFE_ACTVT: nonqueued-receiver-com-spec{data-element=SendLINR_PECP2_FL_SAFE_ACTVT, init-value=SendLINR_PECP2_FL_SAFE_ACTVTValue:3}, required-interface=SendLINR_PECP2_FL_SAFE_ACTVT
      SendLINR_PECP2_FL_SAFE_ACTVT_Vld: nonqueued-receiver-com-spec{data-element=SendLINR_PECP2_FL_SAFE_ACTVT_Vld, init-value=SendLINR_PECP2_FL_SAFE_ACTVT_VldValue:1}, required-interface=SendLINR_PECP2_FL_SAFE_ACTVT_Vld
      SendLINR_PowerPanel2_LED_A_Cmnd: nonqueued-receiver-com-spec{data-element=SendLINR_PowerPanel2_LED_A_Cmnd, init-value=SendLINR_PowerPanel2_LED_A_CmndValue:0}, required-interface=SendLINR_PowerPanel2_LED_A_Cmnd
      SendLINR_PowerPanel2_LED_A_CmndVld: nonqueued-receiver-com-spec{data-element=SendLINR_PowerPanel2_LED_A_CmndVld, init-value=SendLINR_PowerPanel2_LED_A_CmndVldValue:1}, required-interface=SendLINR_PowerPanel2_LED_A_CmndVld
      SendLINR_PowerPanel2_LED_B_Cmnd: nonqueued-receiver-com-spec{data-element=SendLINR_PowerPanel2_LED_B_Cmnd, init-value=SendLINR_PowerPanel2_LED_B_CmndValue:0}, required-interface=SendLINR_PowerPanel2_LED_B_Cmnd
      SendLINR_PowerPanel2_LED_B_CmndVld: nonqueued-receiver-com-spec{data-element=SendLINR_PowerPanel2_LED_B_CmndVld, init-value=SendLINR_PowerPanel2_LED_B_CmndVldValue:1}, required-interface=SendLINR_PowerPanel2_LED_B_CmndVld
      SendLINR_DAY_LGT_MD_PowerPanel2: nonqueued-receiver-com-spec{data-element=SendLINR_DAY_LGT_MD_PowerPanel2, init-value=SendLINR_DAY_LGT_MD_PowerPanel2Value:0}, required-interface=SendLINR_DAY_LGT_MD_PowerPanel2
      SendLINR_DAY_LGT_MD_PowerPanel2Vld: nonqueued-receiver-com-spec{data-element=SendLINR_DAY_LGT_MD_PowerPanel2Vld, init-value=SendLINR_DAY_LGT_MD_PowerPanel2VldValue:1}, required-interface=SendLINR_DAY_LGT_MD_PowerPanel2Vld
      SignalLINR_AGS_RdyForSleep: nonqueued-receiver-com-spec{data-element=SignalLINR_AGS_RdyForSleep, init-value=SignalLINR_AGS_RdyForSleepValue:0}, required-interface=SignalLINR_AGS_RdyForSleep
      SignalLINR_CEXV_RdyForSleep: nonqueued-receiver-com-spec{data-element=SignalLINR_CEXV_RdyForSleep, init-value=SignalLINR_CEXV_RdyForSleepValue:0}, required-interface=SignalLINR_CEXV_RdyForSleep
      SignalLINR_CPIM_RdyForSleep: nonqueued-receiver-com-spec{data-element=SignalLINR_CPIM_RdyForSleep, init-value=SignalLINR_CPIM_RdyForSleepValue:0}, required-interface=SignalLINR_CPIM_RdyForSleep
      SignalLINR_ECH_RdyForSleep: nonqueued-receiver-com-spec{data-element=SignalLINR_ECH_RdyForSleep, init-value=SignalLINR_ECH_RdyForSleepValue:0}, required-interface=SignalLINR_ECH_RdyForSleep
      SignalLINR_EOPB_RdyForSleep: nonqueued-receiver-com-spec{data-element=SignalLINR_EOPB_RdyForSleep, init-value=SignalLINR_EOPB_RdyForSleepValue:0}, required-interface=SignalLINR_EOPB_RdyForSleep
      SignalLINR_HTLBV_RdyForSleep: nonqueued-receiver-com-spec{data-element=SignalLINR_HTLBV_RdyForSleep, init-value=SignalLINR_HTLBV_RdyForSleepValue:0}, required-interface=SignalLINR_HTLBV_RdyForSleep
      SignalLINR_PECP2_RdyForSleep: nonqueued-receiver-com-spec{data-element=SignalLINR_PECP2_RdyForSleep, init-value=SignalLINR_PECP2_RdyForSleepValue:0}, required-interface=SignalLINR_PECP2_RdyForSleep
      SignalLINR_SPP2_RdyForSleep: nonqueued-receiver-com-spec{data-element=SignalLINR_SPP2_RdyForSleep, init-value=SignalLINR_SPP2_RdyForSleepValue:0}, required-interface=SignalLINR_SPP2_RdyForSleep
    22 x provide port:
      VeLINR_b_LIN3_RequestsPostRun: nonqueued-sender-com-spec{data-element=VeSPLR_b_PostRunRqrdSt, init-value=1}, provided-interface=VeSPLR_b_PostRunRqrdSt  # Indicates LIN is ready for power down
      VeLINR_d_LIN_SlavePrsntSts_LIN3: nonqueued-sender-com-spec{data-element=VeLINR_d_LIN_SlavePrsntSts_LIN3, init-value=Value:0}, provided-interface=VeLINR_d_LIN_SlavePrsntSts_LIN3
      VeLINR_e_PowerPanel2_LED_A_Fdbk: nonqueued-sender-com-spec{data-element=VeLINR_e_PowerPanel2_LED_A_Fdbk, init-value=VeLINR_e_PowerPanel2_LED_A_FdbkValue:0}, provided-interface=VeLINR_e_PowerPanel2_LED_A_Fdbk
      VeLINR_b_PowerPanel2_LED_A_FdbkTO: nonqueued-sender-com-spec{data-element=VeLINR_b_PowerPanel2_LED_A_FdbkTO, init-value=VeLINR_b_PowerPanel2_LED_A_FdbkTOValue:0}, provided-interface=VeLINR_b_PowerPanel2_LED_A_FdbkTO
      VeLINR_e_PowerPanel2_LED_B_Fdbk: nonqueued-sender-com-spec{data-element=VeLINR_e_PowerPanel2_LED_B_Fdbk, init-value=VeLINR_e_PowerPanel2_LED_B_FdbkValue:0}, provided-interface=VeLINR_e_PowerPanel2_LED_B_Fdbk
      VeLINR_b_PowerPanel2_LED_B_FdbkTO: nonqueued-sender-com-spec{data-element=VeLINR_b_PowerPanel2_LED_B_FdbkTO, init-value=VeLINR_b_PowerPanel2_LED_B_FdbkTOValue:0}, provided-interface=VeLINR_b_PowerPanel2_LED_B_FdbkTO
      VeLINR_e_PowPan2_LED_A_FailStat: nonqueued-sender-com-spec{data-element=VeLINR_e_PowPan2_LED_A_FailStat, init-value=VeLINR_e_PowPan2_LED_A_FailStatValue:0}, provided-interface=VeLINR_e_PowPan2_LED_A_FailStat
      VeLINR_b_PowPan2_LED_A_FailStatTO: nonqueued-sender-com-spec{data-element=VeLINR_b_PowPan2_LED_A_FailStatTO, init-value=VeLINR_b_PowPan2_LED_A_FailStatTOValue:0}, provided-interface=VeLINR_b_PowPan2_LED_A_FailStatTO
      VeLINR_e_PowPan2_LED_B_FailStat: nonqueued-sender-com-spec{data-element=VeLINR_e_PowPan2_LED_B_FailStat, init-value=VeLINR_e_PowPan2_LED_B_FailStatValue:0}, provided-interface=VeLINR_e_PowPan2_LED_B_FailStat
      VeLINR_b_PowPan2_LED_B_FailStatTO: nonqueued-sender-com-spec{data-element=VeLINR_b_PowPan2_LED_B_FailStatTO, init-value=VeLINR_b_PowPan2_LED_B_FailStatTOValue:0}, provided-interface=VeLINR_b_PowPan2_LED_B_FailStatTO
      VeLINR_e_PowPan2_LED_A_Col_Fdbk: nonqueued-sender-com-spec{data-element=VeLINR_e_PowPan2_LED_A_Col_Fdbk, init-value=VeLINR_e_PowPan2_LED_A_Col_FdbkValue:0}, provided-interface=VeLINR_e_PowPan2_LED_A_Col_Fdbk
      VeLINR_b_PowPan2_LED_A_Col_FdbkTO: nonqueued-sender-com-spec{data-element=VeLINR_b_PowPan2_LED_A_Col_FdbkTO, init-value=VeLINR_b_PowPan2_LED_A_Col_FdbkTOValue:0}, provided-interface=VeLINR_b_PowPan2_LED_A_Col_FdbkTO
      VeLINR_e_PowPan2_LED_B_Col_Fdbk: nonqueued-sender-com-spec{data-element=VeLINR_e_PowPan2_LED_B_Col_Fdbk, init-value=VeLINR_e_PowPan2_LED_B_Col_FdbkValue:0}, provided-interface=VeLINR_e_PowPan2_LED_B_Col_Fdbk
      VeLINR_b_PowPan2_LED_B_Col_FdbkTO: nonqueued-sender-com-spec{data-element=VeLINR_b_PowPan2_LED_B_Col_FdbkTO, init-value=VeLINR_b_PowPan2_LED_B_Col_FdbkTOValue:0}, provided-interface=VeLINR_b_PowPan2_LED_B_Col_FdbkTO
      VeLINR_b_PowPan2_LIN_Cksm_Err: nonqueued-sender-com-spec{data-element=VeLINR_b_PowPan2_LIN_Cksm_Err, init-value=VeLINR_b_PowPan2_LIN_Cksm_ErrValue:0}, provided-interface=VeLINR_b_PowPan2_LIN_Cksm_Err
      VeLINR_b_PowPan2_LIN_Cksm_ErrTO: nonqueued-sender-com-spec{data-element=VeLINR_b_PowPan2_LIN_Cksm_ErrTO, init-value=VeLINR_b_PowPan2_LIN_Cksm_ErrTOValue:0}, provided-interface=VeLINR_b_PowPan2_LIN_Cksm_ErrTO
      VeLINR_b_PowPan2_LIN_Data_Err: nonqueued-sender-com-spec{data-element=VeLINR_b_PowPan2_LIN_Data_Err, init-value=VeLINR_b_PowPan2_LIN_Data_ErrValue:0}, provided-interface=VeLINR_b_PowPan2_LIN_Data_Err
      VeLINR_b_PowPan2_LIN_Data_ErrTO: nonqueued-sender-com-spec{data-element=VeLINR_b_PowPan2_LIN_Data_ErrTO, init-value=VeLINR_b_PowPan2_LIN_Data_ErrTOValue:0}, provided-interface=VeLINR_b_PowPan2_LIN_Data_ErrTO
      VeLINR_b_PowPan2_LIN_Parity_Err: nonqueued-sender-com-spec{data-element=VeLINR_b_PowPan2_LIN_Parity_Err, init-value=VeLINR_b_PowPan2_LIN_Parity_ErrValue:0}, provided-interface=VeLINR_b_PowPan2_LIN_Parity_Err
      VeLINR_b_PowPan2_LIN_Parity_ErrTO: nonqueued-sender-com-spec{data-element=VeLINR_b_PowPan2_LIN_Parity_ErrTO, init-value=VeLINR_b_PowPan2_LIN_Parity_ErrTOValue:0}, provided-interface=VeLINR_b_PowPan2_LIN_Parity_ErrTO
      VeLINR_b_PowPan2_Gnd_Fault_Det: nonqueued-sender-com-spec{data-element=VeLINR_b_PowPan2_Gnd_Fault_Det, init-value=VeLINR_b_PowPan2_Gnd_Fault_DetValue:0}, provided-interface=VeLINR_b_PowPan2_Gnd_Fault_Det
      VeLINR_b_PowPan2_Gnd_Fault_DetTO: nonqueued-sender-com-spec{data-element=VeLINR_b_PowPan2_Gnd_Fault_DetTO, init-value=VeLINR_b_PowPan2_Gnd_Fault_DetTOValue:0}, provided-interface=VeLINR_b_PowPan2_Gnd_Fault_DetTO
    4 x require port:
      SendLINR_PowPan2_LED_A_Col_Comm: nonqueued-receiver-com-spec{data-element=SendLINR_PowPan2_LED_A_Col_Comm, init-value=SendLINR_PowPan2_LED_A_Col_CommValue:0}, required-interface=SendLINR_PowPan2_LED_A_Col_Comm
      SendLINR_PowPan2_LED_A_Col_CommVld: nonqueued-receiver-com-spec{data-element=SendLINR_PowPan2_LED_A_Col_CommVld, init-value=SendLINR_PowPan2_LED_A_Col_CommVldValue:1}, required-interface=SendLINR_PowPan2_LED_A_Col_CommVld
      SendLINR_PowPan2_LED_B_Col_Comm: nonqueued-receiver-com-spec{data-element=SendLINR_PowPan2_LED_B_Col_Comm, init-value=SendLINR_PowPan2_LED_B_Col_CommValue:0}, required-interface=SendLINR_PowPan2_LED_B_Col_Comm
      SendLINR_PowPan2_LED_B_Col_CommVld: nonqueued-receiver-com-spec{data-element=SendLINR_PowPan2_LED_B_Col_CommVld, init-value=SendLINR_PowPan2_LED_B_Col_CommVldValue:1}, required-interface=SendLINR_PowPan2_LED_B_Col_CommVld
    8 x provide port:
      VeLINR_d_PwrPanel2CurrDrawSens1: nonqueued-sender-com-spec{data-element=VeLINR_d_PwrPanel2CurrDrawSens1, init-value=VeLINR_d_PwrPanel2CurrDrawSens1Value:0}, provided-interface=VeLINR_d_PwrPanel2CurrDrawSens1
      VeLINR_b_PwrPanel2CurrDrawSens1TO: nonqueued-sender-com-spec{data-element=VeLINR_b_PwrPanel2CurrDrawSens1TO, init-value=VeLINR_b_PwrPanel2CurrDrawSens1TOValue:0}, provided-interface=VeLINR_b_PwrPanel2CurrDrawSens1TO
      VeLINR_d_PwrPanel2CurrDrawSens2: nonqueued-sender-com-spec{data-element=VeLINR_d_PwrPanel2CurrDrawSens2, init-value=VeLINR_d_PwrPanel2CurrDrawSens2Value:0}, provided-interface=VeLINR_d_PwrPanel2CurrDrawSens2
      VeLINR_b_PwrPanel2CurrDrawSens2TO: nonqueued-sender-com-spec{data-element=VeLINR_b_PwrPanel2CurrDrawSens2TO, init-value=VeLINR_b_PwrPanel2CurrDrawSens2TOValue:0}, provided-interface=VeLINR_b_PwrPanel2CurrDrawSens2TO
      VeLINR_e_PowerPanel2_Fault: nonqueued-sender-com-spec{data-element=VeLINR_e_PowerPanel2_Fault, init-value=VeLINR_e_PowerPanel2_FaultValue:0}, provided-interface=VeLINR_e_PowerPanel2_Fault
      VeLINR_b_PowerPanel2_FaultTO: nonqueued-sender-com-spec{data-element=VeLINR_b_PowerPanel2_FaultTO, init-value=VeLINR_b_PowerPanel2_FaultTOValue:0}, provided-interface=VeLINR_b_PowerPanel2_FaultTO
      VeLINR_y_PowerPanel2_RatedPower: nonqueued-sender-com-spec{data-element=VeLINR_y_PowerPanel2_RatedPower, init-value=VeLINR_y_PowerPanel2_RatedPowerValue:0}, provided-interface=VeLINR_y_PowerPanel2_RatedPower
      VeLINR_b_PowerPanel2_RatedPowerTO: nonqueued-sender-com-spec{data-element=VeLINR_b_PowerPanel2_RatedPowerTO, init-value=VeLINR_b_PowerPanel2_RatedPowerTOValue:0}, provided-interface=VeLINR_b_PowerPanel2_RatedPowerTO
    behavior IBApplLinComAb_LIN3: data-type-mapping=[MG_LinEquid_Mapping, ADTtoIDTMapping, BswMMappingSet], handle-termination-and-restart=NO-SUPPORT
      init event IninEve: start-on-event=ApplLinComAb_LIN3Inin
      swc mode switch event MSELinsmComMod: disabled-mode=[MdulPwrMod.AppMode_MDGP_ESH_Mode.POSTRUN, MdulPwrMod.AppMode_MDGP_ESH_Mode.SHUTDOWN], start-on-event=LinsmComModSetScheduleTbl, activation=ON-ENTRY, mode=PP_MS_LinSMComMod.MDGP_MSI_LinSMComMod.LinSMComMod_FULL_COMM  # Triggered when Linsm goes to FULL COMM mode. Used to set the schedule table based on the equipped/learned state of the slaves.
      swc mode switch event MSELinsmInNoComMod: start-on-event=LinsmComModNotifyRdyToPwrDwn, activation=ON-ENTRY, mode=PP_MS_LinSMComMod.MDGP_MSI_LinSMComMod.LinSMComMod_NO_COMM  # When LinSM goes to NO COMM mode
        disabled-mode:
          MdulPwrMod.AppMode_MDGP_ESH_Mode.RUN
          MdulPwrMod.AppMode_MDGP_ESH_Mode.STARTUP
          MdulPwrMod.AppMode_MDGP_ESH_Mode.WAKEUP
      swc mode switch event MSEMdulInPostrun: start-on-event=LinsmComModPostrun, activation=ON-ENTRY, mode=MdulPwrMod.AppMode_MDGP_ESH_Mode.POSTRUN
      data received event DRECOMRXL_AGS_CurrPos_AGS_ECM_STATUS_Lin3: start-on-event=COMRXL_AGS_CurrPos_AGS_ECM_STATUS_Lin3_Received, data=Lin3ComRxSignalsSR.COMRXL_AGS_CurrPos_AGS_ECM_STATUS_Lin3
      data receive error event DEECOMRXL_AGS_CurrPos_AGS_ECM_STATUS_Lin3: start-on-event=COMRXL_AGS_CurrPos_AGS_ECM_STATUS_Lin3_Error, data=Lin3ComRxSignalsSR.COMRXL_AGS_CurrPos_AGS_ECM_STATUS_Lin3
      data received event DRECOMRXL_AGS_CalStat_AGS_ECM_STATUS_Lin3: start-on-event=COMRXL_AGS_CalStat_AGS_ECM_STATUS_Lin3_Received, data=Lin3ComRxSignalsSR.COMRXL_AGS_CalStat_AGS_ECM_STATUS_Lin3
      data receive error event DEECOMRXL_AGS_CalStat_AGS_ECM_STATUS_Lin3: start-on-event=COMRXL_AGS_CalStat_AGS_ECM_STATUS_Lin3_Error, data=Lin3ComRxSignalsSR.COMRXL_AGS_CalStat_AGS_ECM_STATUS_Lin3
      data received event DRECOMRXL_AGS_CalActv_AGS_ECM_STATUS_Lin3: start-on-event=COMRXL_AGS_CalActv_AGS_ECM_STATUS_Lin3_Received, data=Lin3ComRxSignalsSR.COMRXL_AGS_CalActv_AGS_ECM_STATUS_Lin3
      data receive error event DEECOMRXL_AGS_CalActv_AGS_ECM_STATUS_Lin3: start-on-event=COMRXL_AGS_CalActv_AGS_ECM_STATUS_Lin3_Error, data=Lin3ComRxSignalsSR.COMRXL_AGS_CalActv_AGS_ECM_STATUS_Lin3
      data received event DRECOMRXL_AGS_ErrUnVolt_AGS_ECM_STATUS_Lin3: start-on-event=COMRXL_AGS_ErrUnVolt_AGS_ECM_STATUS_Lin3_Received, data=Lin3ComRxSignalsSR.COMRXL_AGS_ErrUnVolt_AGS_ECM_STATUS_Lin3
      data receive error event DEECOMRXL_AGS_ErrUnVolt_AGS_ECM_STATUS_Lin3: start-on-event=COMRXL_AGS_ErrUnVolt_AGS_ECM_STATUS_Lin3_Error, data=Lin3ComRxSignalsSR.COMRXL_AGS_ErrUnVolt_AGS_ECM_STATUS_Lin3
      data received event DRECOMRXL_AGS_ErrOvrVolt_AGS_ECM_STATUS_Lin3: start-on-event=COMRXL_AGS_ErrOvrVolt_AGS_ECM_STATUS_Lin3_Received, data=Lin3ComRxSignalsSR.COMRXL_AGS_ErrOvrVolt_AGS_ECM_STATUS_Lin3
      data receive error event DEECOMRXL_AGS_ErrOvrVolt_AGS_ECM_STATUS_Lin3: start-on-event=COMRXL_AGS_ErrOvrVolt_AGS_ECM_STATUS_Lin3_Error, data=Lin3ComRxSignalsSR.COMRXL_AGS_ErrOvrVolt_AGS_ECM_STATUS_Lin3
      data received event DRECOMRXL_AGS_ErrOvrTemp_AGS_ECM_STATUS_Lin3: start-on-event=COMRXL_AGS_ErrOvrTemp_AGS_ECM_STATUS_Lin3_Received, data=Lin3ComRxSignalsSR.COMRXL_AGS_ErrOvrTemp_AGS_ECM_STATUS_Lin3
      data receive error event DEECOMRXL_AGS_ErrOvrTemp_AGS_ECM_STATUS_Lin3: start-on-event=COMRXL_AGS_ErrOvrTemp_AGS_ECM_STATUS_Lin3_Error, data=Lin3ComRxSignalsSR.COMRXL_AGS_ErrOvrTemp_AGS_ECM_STATUS_Lin3
      data received event DRECOMRXL_AGS_ErrMechStuck_AGS_ECM_STATUS_Lin3: start-on-event=COMRXL_AGS_ErrMechStuck_AGS_ECM_STATUS_Lin3_Received, data=Lin3ComRxSignalsSR.COMRXL_AGS_ErrMechStuck_AGS_ECM_STATUS_Lin3
      data receive error event DEECOMRXL_AGS_ErrMechStuck_AGS_ECM_STATUS_Lin3: start-on-event=COMRXL_AGS_ErrMechStuck_AGS_ECM_STATUS_Lin3_Error, data=Lin3ComRxSignalsSR.COMRXL_AGS_ErrMechStuck_AGS_ECM_STATUS_Lin3
      data received event DRECOMRXL_AGS_ErrMechBreak_AGS_ECM_STATUS_Lin3: start-on-event=COMRXL_AGS_ErrMechBreak_AGS_ECM_STATUS_Lin3_Received, data=Lin3ComRxSignalsSR.COMRXL_AGS_ErrMechBreak_AGS_ECM_STATUS_Lin3
      data receive error event DEECOMRXL_AGS_ErrMechBreak_AGS_ECM_STATUS_Lin3: start-on-event=COMRXL_AGS_ErrMechBreak_AGS_ECM_STATUS_Lin3_Error, data=Lin3ComRxSignalsSR.COMRXL_AGS_ErrMechBreak_AGS_ECM_STATUS_Lin3
      data received event DRECOMRXL_AGS_ErrLIN_AGS_ECM_STATUS_Lin3: start-on-event=COMRXL_AGS_ErrLIN_AGS_ECM_STATUS_Lin3_Received, data=Lin3ComRxSignalsSR.COMRXL_AGS_ErrLIN_AGS_ECM_STATUS_Lin3
      data receive error event DEECOMRXL_AGS_ErrLIN_AGS_ECM_STATUS_Lin3: start-on-event=COMRXL_AGS_ErrLIN_AGS_ECM_STATUS_Lin3_Error, data=Lin3ComRxSignalsSR.COMRXL_AGS_ErrLIN_AGS_ECM_STATUS_Lin3
      data received event DRECOMRXL_RsErr_AGS_AGS_ECM_STATUS_Lin3: start-on-event=COMRXL_RsErr_AGS_AGS_ECM_STATUS_Lin3_Received, data=Lin3ComRxSignalsSR.COMRXL_RsErr_AGS_AGS_ECM_STATUS_Lin3
      data receive error event DEECOMRXL_RsErr_AGS_AGS_ECM_STATUS_Lin3: start-on-event=COMRXL_RsErr_AGS_AGS_ECM_STATUS_Lin3_Error, data=Lin3ComRxSignalsSR.COMRXL_RsErr_AGS_AGS_ECM_STATUS_Lin3
      data received event DRECOMRXL_AGS_BoostStat_AGS_ECM_STATUS_Lin3: start-on-event=COMRXL_AGS_BoostStat_AGS_ECM_STATUS_Lin3_Received, data=Lin3ComRxSignalsSR.COMRXL_AGS_BoostStat_AGS_ECM_STATUS_Lin3
      data receive error event DEECOMRXL_AGS_BoostStat_AGS_ECM_STATUS_Lin3: start-on-event=COMRXL_AGS_BoostStat_AGS_ECM_STATUS_Lin3_Error, data=Lin3ComRxSignalsSR.COMRXL_AGS_BoostStat_AGS_ECM_STATUS_Lin3
      data received event DRECOMRXL_S2MRes1Bit_AGS_ECM_STATUS_Lin3: start-on-event=COMRXL_S2MRes1Bit_AGS_ECM_STATUS_Lin3_Received, data=Lin3ComRxSignalsSR.COMRXL_S2MRes1Bit_AGS_ECM_STATUS_Lin3
      data receive error event DEECOMRXL_S2MRes1Bit_AGS_ECM_STATUS_Lin3: start-on-event=COMRXL_S2MRes1Bit_AGS_ECM_STATUS_Lin3_Error, data=Lin3ComRxSignalsSR.COMRXL_S2MRes1Bit_AGS_ECM_STATUS_Lin3
      data received event DRECOMRXL_S2MResByte1_AGS_ECM_STATUS_Lin3: start-on-event=COMRXL_S2MResByte1_AGS_ECM_STATUS_Lin3_Received, data=Lin3ComRxSignalsSR.COMRXL_S2MResByte1_AGS_ECM_STATUS_Lin3
      data receive error event DEECOMRXL_S2MResByte1_AGS_ECM_STATUS_Lin3: start-on-event=COMRXL_S2MResByte1_AGS_ECM_STATUS_Lin3_Error, data=Lin3ComRxSignalsSR.COMRXL_S2MResByte1_AGS_ECM_STATUS_Lin3
      data received event DRECOMRXL_S2MResByte2_AGS_ECM_STATUS_Lin3: start-on-event=COMRXL_S2MResByte2_AGS_ECM_STATUS_Lin3_Received, data=Lin3ComRxSignalsSR.COMRXL_S2MResByte2_AGS_ECM_STATUS_Lin3
      data receive error event DEECOMRXL_S2MResByte2_AGS_ECM_STATUS_Lin3: start-on-event=COMRXL_S2MResByte2_AGS_ECM_STATUS_Lin3_Error, data=Lin3ComRxSignalsSR.COMRXL_S2MResByte2_AGS_ECM_STATUS_Lin3
      data received event DRECOMRXL_CEXV_PosAct_CEXV_STAT_Lin3: start-on-event=COMRXL_CEXV_PosAct_CEXV_STAT_Lin3_Received, data=Lin3ComRxSignalsSR.COMRXL_CEXV_PosAct_CEXV_STAT_Lin3
      data receive error event DEECOMRXL_CEXV_PosAct_CEXV_STAT_Lin3: start-on-event=COMRXL_CEXV_PosAct_CEXV_STAT_Lin3_Error, data=Lin3ComRxSignalsSR.COMRXL_CEXV_PosAct_CEXV_STAT_Lin3
      data received event DRECOMRXL_CEXV_CalStat_CEXV_STAT_Lin3: start-on-event=COMRXL_CEXV_CalStat_CEXV_STAT_Lin3_Received, data=Lin3ComRxSignalsSR.COMRXL_CEXV_CalStat_CEXV_STAT_Lin3
      data receive error event DEECOMRXL_CEXV_CalStat_CEXV_STAT_Lin3: start-on-event=COMRXL_CEXV_CalStat_CEXV_STAT_Lin3_Error, data=Lin3ComRxSignalsSR.COMRXL_CEXV_CalStat_CEXV_STAT_Lin3
      data received event DRECOMRXL_CEXV_CalRq_CEXV_STAT_Lin3: start-on-event=COMRXL_CEXV_CalRq_CEXV_STAT_Lin3_Received, data=Lin3ComRxSignalsSR.COMRXL_CEXV_CalRq_CEXV_STAT_Lin3
      data receive error event DEECOMRXL_CEXV_CalRq_CEXV_STAT_Lin3: start-on-event=COMRXL_CEXV_CalRq_CEXV_STAT_Lin3_Error, data=Lin3ComRxSignalsSR.COMRXL_CEXV_CalRq_CEXV_STAT_Lin3
      data received event DRECOMRXL_RsErr_CEXV_CEXV_STAT_Lin3: start-on-event=COMRXL_RsErr_CEXV_CEXV_STAT_Lin3_Received, data=Lin3ComRxSignalsSR.COMRXL_RsErr_CEXV_CEXV_STAT_Lin3
      data receive error event DEECOMRXL_RsErr_CEXV_CEXV_STAT_Lin3: start-on-event=COMRXL_RsErr_CEXV_CEXV_STAT_Lin3_Error, data=Lin3ComRxSignalsSR.COMRXL_RsErr_CEXV_CEXV_STAT_Lin3
      data received event DRECOMRXL_CEXV_Sts_CEXV_STAT_Lin3: start-on-event=COMRXL_CEXV_Sts_CEXV_STAT_Lin3_Received, data=Lin3ComRxSignalsSR.COMRXL_CEXV_Sts_CEXV_STAT_Lin3
      data receive error event DEECOMRXL_CEXV_Sts_CEXV_STAT_Lin3: start-on-event=COMRXL_CEXV_Sts_CEXV_STAT_Lin3_Error, data=Lin3ComRxSignalsSR.COMRXL_CEXV_Sts_CEXV_STAT_Lin3
      data received event DRECOMRXL_CEXV_ERR_CEXV_STAT_Lin3: start-on-event=COMRXL_CEXV_ERR_CEXV_STAT_Lin3_Received, data=Lin3ComRxSignalsSR.COMRXL_CEXV_ERR_CEXV_STAT_Lin3
      data receive error event DEECOMRXL_CEXV_ERR_CEXV_STAT_Lin3: start-on-event=COMRXL_CEXV_ERR_CEXV_STAT_Lin3_Error, data=Lin3ComRxSignalsSR.COMRXL_CEXV_ERR_CEXV_STAT_Lin3
      data received event DRECOMRXL_CEXV_SupplyVolt_CEXV_STAT_Lin3: start-on-event=COMRXL_CEXV_SupplyVolt_CEXV_STAT_Lin3_Received, data=Lin3ComRxSignalsSR.COMRXL_CEXV_SupplyVolt_CEXV_STAT_Lin3
      data receive error event DEECOMRXL_CEXV_SupplyVolt_CEXV_STAT_Lin3: start-on-event=COMRXL_CEXV_SupplyVolt_CEXV_STAT_Lin3_Error, data=Lin3ComRxSignalsSR.COMRXL_CEXV_SupplyVolt_CEXV_STAT_Lin3
      data received event DRECOMRXL_CEXV_Refrigerant_Pressure_CEXV_STAT_Lin3: start-on-event=COMRXL_CEXV_Refrigerant_Pressure_CEXV_STAT_Lin3_Received, data=Lin3ComRxSignalsSR.COMRXL_CEXV_Refrigerant_Pressure_CEXV_STAT_Lin3
      data receive error event DEECOMRXL_CEXV_Refrigerant_Pressure_CEXV_STAT_Lin3: start-on-event=COMRXL_CEXV_Refrigerant_Pressure_CEXV_STAT_Lin3_Error, data=Lin3ComRxSignalsSR.COMRXL_CEXV_Refrigerant_Pressure_CEXV_STAT_Lin3
      data received event DRECOMRXL_CEXV_Board_Temp_CEXV_STAT_Lin3: start-on-event=COMRXL_CEXV_Board_Temp_CEXV_STAT_Lin3_Received, data=Lin3ComRxSignalsSR.COMRXL_CEXV_Board_Temp_CEXV_STAT_Lin3
      data receive error event DEECOMRXL_CEXV_Board_Temp_CEXV_STAT_Lin3: start-on-event=COMRXL_CEXV_Board_Temp_CEXV_STAT_Lin3_Error, data=Lin3ComRxSignalsSR.COMRXL_CEXV_Board_Temp_CEXV_STAT_Lin3
      data received event DRECOMRXL_CEXV_Refrigerant_Temp_CEXV_STAT_Lin3: start-on-event=COMRXL_CEXV_Refrigerant_Temp_CEXV_STAT_Lin3_Received, data=Lin3ComRxSignalsSR.COMRXL_CEXV_Refrigerant_Temp_CEXV_STAT_Lin3
      data receive error event DEECOMRXL_CEXV_Refrigerant_Temp_CEXV_STAT_Lin3: start-on-event=COMRXL_CEXV_Refrigerant_Temp_CEXV_STAT_Lin3_Error, data=Lin3ComRxSignalsSR.COMRXL_CEXV_Refrigerant_Temp_CEXV_STAT_Lin3
      data received event DRECOMRXL_Inlet_Temp1_DC_CPIM_HCP_FEEDBACK2_Lin3: start-on-event=COMRXL_Inlet_Temp1_DC_CPIM_HCP_FEEDBACK2_Lin3_Received, data=Lin3ComRxSignalsSR.COMRXL_Inlet_Temp1_DC_CPIM_HCP_FEEDBACK2_Lin3
      data receive error event DEECOMRXL_Inlet_Temp1_DC_CPIM_HCP_FEEDBACK2_Lin3: start-on-event=COMRXL_Inlet_Temp1_DC_CPIM_HCP_FEEDBACK2_Lin3_Error, data=Lin3ComRxSignalsSR.COMRXL_Inlet_Temp1_DC_CPIM_HCP_FEEDBACK2_Lin3
      data received event DRECOMRXL_Inlet_Temp2_DC_CPIM_HCP_FEEDBACK2_Lin3: start-on-event=COMRXL_Inlet_Temp2_DC_CPIM_HCP_FEEDBACK2_Lin3_Received, data=Lin3ComRxSignalsSR.COMRXL_Inlet_Temp2_DC_CPIM_HCP_FEEDBACK2_Lin3
      data receive error event DEECOMRXL_Inlet_Temp2_DC_CPIM_HCP_FEEDBACK2_Lin3: start-on-event=COMRXL_Inlet_Temp2_DC_CPIM_HCP_FEEDBACK2_Lin3_Error, data=Lin3ComRxSignalsSR.COMRXL_Inlet_Temp2_DC_CPIM_HCP_FEEDBACK2_Lin3
      data received event DRECOMRXL_CPIM_IND1_Fdbk_CPIM_HCP_FEEDBACK_Lin3: start-on-event=COMRXL_CPIM_IND1_Fdbk_CPIM_HCP_FEEDBACK_Lin3_Received, data=Lin3ComRxSignalsSR.COMRXL_CPIM_IND1_Fdbk_CPIM_HCP_FEEDBACK_Lin3
      data receive error event DEECOMRXL_CPIM_IND1_Fdbk_CPIM_HCP_FEEDBACK_Lin3: start-on-event=COMRXL_CPIM_IND1_Fdbk_CPIM_HCP_FEEDBACK_Lin3_Error, data=Lin3ComRxSignalsSR.COMRXL_CPIM_IND1_Fdbk_CPIM_HCP_FEEDBACK_Lin3
      data received event DRECOMRXL_CPIM_IND2_Fdbk_CPIM_HCP_FEEDBACK_Lin3: start-on-event=COMRXL_CPIM_IND2_Fdbk_CPIM_HCP_FEEDBACK_Lin3_Received, data=Lin3ComRxSignalsSR.COMRXL_CPIM_IND2_Fdbk_CPIM_HCP_FEEDBACK_Lin3
      data receive error event DEECOMRXL_CPIM_IND2_Fdbk_CPIM_HCP_FEEDBACK_Lin3: start-on-event=COMRXL_CPIM_IND2_Fdbk_CPIM_HCP_FEEDBACK_Lin3_Error, data=Lin3ComRxSignalsSR.COMRXL_CPIM_IND2_Fdbk_CPIM_HCP_FEEDBACK_Lin3
      data received event DRECOMRXL_CPIM_IND3_Fdbk_CPIM_HCP_FEEDBACK_Lin3: start-on-event=COMRXL_CPIM_IND3_Fdbk_CPIM_HCP_FEEDBACK_Lin3_Received, data=Lin3ComRxSignalsSR.COMRXL_CPIM_IND3_Fdbk_CPIM_HCP_FEEDBACK_Lin3
      data receive error event DEECOMRXL_CPIM_IND3_Fdbk_CPIM_HCP_FEEDBACK_Lin3: start-on-event=COMRXL_CPIM_IND3_Fdbk_CPIM_HCP_FEEDBACK_Lin3_Error, data=Lin3ComRxSignalsSR.COMRXL_CPIM_IND3_Fdbk_CPIM_HCP_FEEDBACK_Lin3
      data received event DRECOMRXL_CPIM_IND4_Fdbk_CPIM_HCP_FEEDBACK_Lin3: start-on-event=COMRXL_CPIM_IND4_Fdbk_CPIM_HCP_FEEDBACK_Lin3_Received, data=Lin3ComRxSignalsSR.COMRXL_CPIM_IND4_Fdbk_CPIM_HCP_FEEDBACK_Lin3
      data receive error event DEECOMRXL_CPIM_IND4_Fdbk_CPIM_HCP_FEEDBACK_Lin3: start-on-event=COMRXL_CPIM_IND4_Fdbk_CPIM_HCP_FEEDBACK_Lin3_Error, data=Lin3ComRxSignalsSR.COMRXL_CPIM_IND4_Fdbk_CPIM_HCP_FEEDBACK_Lin3
      data received event DRECOMRXL_CPIM_IND5_Fdbk_CPIM_HCP_FEEDBACK_Lin3: start-on-event=COMRXL_CPIM_IND5_Fdbk_CPIM_HCP_FEEDBACK_Lin3_Received, data=Lin3ComRxSignalsSR.COMRXL_CPIM_IND5_Fdbk_CPIM_HCP_FEEDBACK_Lin3
      data receive error event DEECOMRXL_CPIM_IND5_Fdbk_CPIM_HCP_FEEDBACK_Lin3: start-on-event=COMRXL_CPIM_IND5_Fdbk_CPIM_HCP_FEEDBACK_Lin3_Error, data=Lin3ComRxSignalsSR.COMRXL_CPIM_IND5_Fdbk_CPIM_HCP_FEEDBACK_Lin3
      data received event DRECOMRXL_CPIM_IND_Color_Fdbk_CPIM_HCP_FEEDBACK_Lin3: start-on-event=COMRXL_CPIM_IND_Color_Fdbk_CPIM_HCP_FEEDBACK_Lin3_Received, data=Lin3ComRxSignalsSR.COMRXL_CPIM_IND_Color_Fdbk_CPIM_HCP_FEEDBACK_Lin3
      data receive error event DEECOMRXL_CPIM_IND_Color_Fdbk_CPIM_HCP_FEEDBACK_Lin3: start-on-event=COMRXL_CPIM_IND_Color_Fdbk_CPIM_HCP_FEEDBACK_Lin3_Error, data=Lin3ComRxSignalsSR.COMRXL_CPIM_IND_Color_Fdbk_CPIM_HCP_FEEDBACK_Lin3
      data received event DRECOMRXL_CPIM_IND1_FailSts_CPIM_HCP_FEEDBACK_Lin3: start-on-event=COMRXL_CPIM_IND1_FailSts_CPIM_HCP_FEEDBACK_Lin3_Received, data=Lin3ComRxSignalsSR.COMRXL_CPIM_IND1_FailSts_CPIM_HCP_FEEDBACK_Lin3
      data receive error event DEECOMRXL_CPIM_IND1_FailSts_CPIM_HCP_FEEDBACK_Lin3: start-on-event=COMRXL_CPIM_IND1_FailSts_CPIM_HCP_FEEDBACK_Lin3_Error, data=Lin3ComRxSignalsSR.COMRXL_CPIM_IND1_FailSts_CPIM_HCP_FEEDBACK_Lin3
      data received event DRECOMRXL_CPIM_IND2_FailSts_CPIM_HCP_FEEDBACK_Lin3: start-on-event=COMRXL_CPIM_IND2_FailSts_CPIM_HCP_FEEDBACK_Lin3_Received, data=Lin3ComRxSignalsSR.COMRXL_CPIM_IND2_FailSts_CPIM_HCP_FEEDBACK_Lin3
      data receive error event DEECOMRXL_CPIM_IND2_FailSts_CPIM_HCP_FEEDBACK_Lin3: start-on-event=COMRXL_CPIM_IND2_FailSts_CPIM_HCP_FEEDBACK_Lin3_Error, data=Lin3ComRxSignalsSR.COMRXL_CPIM_IND2_FailSts_CPIM_HCP_FEEDBACK_Lin3
      data received event DRECOMRXL_CPIM_IND3_FailSts_CPIM_HCP_FEEDBACK_Lin3: start-on-event=COMRXL_CPIM_IND3_FailSts_CPIM_HCP_FEEDBACK_Lin3_Received, data=Lin3ComRxSignalsSR.COMRXL_CPIM_IND3_FailSts_CPIM_HCP_FEEDBACK_Lin3
      data receive error event DEECOMRXL_CPIM_IND3_FailSts_CPIM_HCP_FEEDBACK_Lin3: start-on-event=COMRXL_CPIM_IND3_FailSts_CPIM_HCP_FEEDBACK_Lin3_Error, data=Lin3ComRxSignalsSR.COMRXL_CPIM_IND3_FailSts_CPIM_HCP_FEEDBACK_Lin3
      data received event DRECOMRXL_CPIM_IND4_FailSts_CPIM_HCP_FEEDBACK_Lin3: start-on-event=COMRXL_CPIM_IND4_FailSts_CPIM_HCP_FEEDBACK_Lin3_Received, data=Lin3ComRxSignalsSR.COMRXL_CPIM_IND4_FailSts_CPIM_HCP_FEEDBACK_Lin3
      data receive error event DEECOMRXL_CPIM_IND4_FailSts_CPIM_HCP_FEEDBACK_Lin3: start-on-event=COMRXL_CPIM_IND4_FailSts_CPIM_HCP_FEEDBACK_Lin3_Error, data=Lin3ComRxSignalsSR.COMRXL_CPIM_IND4_FailSts_CPIM_HCP_FEEDBACK_Lin3
      data received event DRECOMRXL_CPIM_IND5_FailSts_CPIM_HCP_FEEDBACK_Lin3: start-on-event=COMRXL_CPIM_IND5_FailSts_CPIM_HCP_FEEDBACK_Lin3_Received, data=Lin3ComRxSignalsSR.COMRXL_CPIM_IND5_FailSts_CPIM_HCP_FEEDBACK_Lin3
      data receive error event DEECOMRXL_CPIM_IND5_FailSts_CPIM_HCP_FEEDBACK_Lin3: start-on-event=COMRXL_CPIM_IND5_FailSts_CPIM_HCP_FEEDBACK_Lin3_Error, data=Lin3ComRxSignalsSR.COMRXL_CPIM_IND5_FailSts_CPIM_HCP_FEEDBACK_Lin3
      data received event DRECOMRXL_CPIM_Undervoltage_CPIM_HCP_FEEDBACK_Lin3: start-on-event=COMRXL_CPIM_Undervoltage_CPIM_HCP_FEEDBACK_Lin3_Received, data=Lin3ComRxSignalsSR.COMRXL_CPIM_Undervoltage_CPIM_HCP_FEEDBACK_Lin3
      data receive error event DEECOMRXL_CPIM_Undervoltage_CPIM_HCP_FEEDBACK_Lin3: start-on-event=COMRXL_CPIM_Undervoltage_CPIM_HCP_FEEDBACK_Lin3_Error, data=Lin3ComRxSignalsSR.COMRXL_CPIM_Undervoltage_CPIM_HCP_FEEDBACK_Lin3
      data received event DRECOMRXL_CPIM_Over_Temperature_CPIM_HCP_FEEDBACK_Lin3: start-on-event=COMRXL_CPIM_Over_Temperature_CPIM_HCP_FEEDBACK_Lin3_Received, data=Lin3ComRxSignalsSR.COMRXL_CPIM_Over_Temperature_CPIM_HCP_FEEDBACK_Lin3
      data receive error event DEECOMRXL_CPIM_Over_Temperature_CPIM_HCP_FEEDBACK_Lin3: start-on-event=COMRXL_CPIM_Over_Temperature_CPIM_HCP_FEEDBACK_Lin3_Error, data=Lin3ComRxSignalsSR.COMRXL_CPIM_Over_Temperature_CPIM_HCP_FEEDBACK_Lin3
      data received event DRECOMRXL_CPIM_LIN_Parity_Error_CPIM_HCP_FEEDBACK_Lin3: start-on-event=COMRXL_CPIM_LIN_Parity_Error_CPIM_HCP_FEEDBACK_Lin3_Received, data=Lin3ComRxSignalsSR.COMRXL_CPIM_LIN_Parity_Error_CPIM_HCP_FEEDBACK_Lin3
      data receive error event DEECOMRXL_CPIM_LIN_Parity_Error_CPIM_HCP_FEEDBACK_Lin3: start-on-event=COMRXL_CPIM_LIN_Parity_Error_CPIM_HCP_FEEDBACK_Lin3_Error, data=Lin3ComRxSignalsSR.COMRXL_CPIM_LIN_Parity_Error_CPIM_HCP_FEEDBACK_Lin3
      data received event DRECOMRXL_CPIM_LIN_Checksum_Error_CPIM_HCP_FEEDBACK_Lin3: start-on-event=COMRXL_CPIM_LIN_Checksum_Error_CPIM_HCP_FEEDBACK_Lin3_Received, data=Lin3ComRxSignalsSR.COMRXL_CPIM_LIN_Checksum_Error_CPIM_HCP_FEEDBACK_Lin3
      data receive error event DEECOMRXL_CPIM_LIN_Checksum_Error_CPIM_HCP_FEEDBACK_Lin3: start-on-event=COMRXL_CPIM_LIN_Checksum_Error_CPIM_HCP_FEEDBACK_Lin3_Error, data=Lin3ComRxSignalsSR.COMRXL_CPIM_LIN_Checksum_Error_CPIM_HCP_FEEDBACK_Lin3
      data received event DRECOMRXL_CPIM_LIN_Data_Error_CPIM_HCP_FEEDBACK_Lin3: start-on-event=COMRXL_CPIM_LIN_Data_Error_CPIM_HCP_FEEDBACK_Lin3_Received, data=Lin3ComRxSignalsSR.COMRXL_CPIM_LIN_Data_Error_CPIM_HCP_FEEDBACK_Lin3
      data receive error event DEECOMRXL_CPIM_LIN_Data_Error_CPIM_HCP_FEEDBACK_Lin3: start-on-event=COMRXL_CPIM_LIN_Data_Error_CPIM_HCP_FEEDBACK_Lin3_Error, data=Lin3ComRxSignalsSR.COMRXL_CPIM_LIN_Data_Error_CPIM_HCP_FEEDBACK_Lin3
      data received event DRECOMRXL_ChrgPortLock_Sts_CPIM_HCP_FEEDBACK_Lin3: start-on-event=COMRXL_ChrgPortLock_Sts_CPIM_HCP_FEEDBACK_Lin3_Received, data=Lin3ComRxSignalsSR.COMRXL_ChrgPortLock_Sts_CPIM_HCP_FEEDBACK_Lin3
      data receive error event DEECOMRXL_ChrgPortLock_Sts_CPIM_HCP_FEEDBACK_Lin3: start-on-event=COMRXL_ChrgPortLock_Sts_CPIM_HCP_FEEDBACK_Lin3_Error, data=Lin3ComRxSignalsSR.COMRXL_ChrgPortLock_Sts_CPIM_HCP_FEEDBACK_Lin3
      data received event DRECOMRXL_ChrgPortButton_Sts_CPIM_HCP_FEEDBACK_Lin3: start-on-event=COMRXL_ChrgPortButton_Sts_CPIM_HCP_FEEDBACK_Lin3_Received, data=Lin3ComRxSignalsSR.COMRXL_ChrgPortButton_Sts_CPIM_HCP_FEEDBACK_Lin3
      data receive error event DEECOMRXL_ChrgPortButton_Sts_CPIM_HCP_FEEDBACK_Lin3: start-on-event=COMRXL_ChrgPortButton_Sts_CPIM_HCP_FEEDBACK_Lin3_Error, data=Lin3ComRxSignalsSR.COMRXL_ChrgPortButton_Sts_CPIM_HCP_FEEDBACK_Lin3
      data received event DRECOMRXL_Ambient_Temp_CPIM_HCP_FEEDBACK_Lin3: start-on-event=COMRXL_Ambient_Temp_CPIM_HCP_FEEDBACK_Lin3_Received, data=Lin3ComRxSignalsSR.COMRXL_Ambient_Temp_CPIM_HCP_FEEDBACK_Lin3
      data receive error event DEECOMRXL_Ambient_Temp_CPIM_HCP_FEEDBACK_Lin3: start-on-event=COMRXL_Ambient_Temp_CPIM_HCP_FEEDBACK_Lin3_Error, data=Lin3ComRxSignalsSR.COMRXL_Ambient_Temp_CPIM_HCP_FEEDBACK_Lin3
      data received event DRECOMRXL_Chrg_Inlet_Temp_CPIM_HCP_FEEDBACK_Lin3: start-on-event=COMRXL_Chrg_Inlet_Temp_CPIM_HCP_FEEDBACK_Lin3_Received, data=Lin3ComRxSignalsSR.COMRXL_Chrg_Inlet_Temp_CPIM_HCP_FEEDBACK_Lin3
      data receive error event DEECOMRXL_Chrg_Inlet_Temp_CPIM_HCP_FEEDBACK_Lin3: start-on-event=COMRXL_Chrg_Inlet_Temp_CPIM_HCP_FEEDBACK_Lin3_Error, data=Lin3ComRxSignalsSR.COMRXL_Chrg_Inlet_Temp_CPIM_HCP_FEEDBACK_Lin3
      data received event DRECOMRXL_ResponseErrorStsCPIM_CPIM_HCP_FEEDBACK_Lin3: start-on-event=COMRXL_ResponseErrorStsCPIM_CPIM_HCP_FEEDBACK_Lin3_Received, data=Lin3ComRxSignalsSR.COMRXL_ResponseErrorStsCPIM_CPIM_HCP_FEEDBACK_Lin3
      data receive error event DEECOMRXL_ResponseErrorStsCPIM_CPIM_HCP_FEEDBACK_Lin3: start-on-event=COMRXL_ResponseErrorStsCPIM_CPIM_HCP_FEEDBACK_Lin3_Error, data=Lin3ComRxSignalsSR.COMRXL_ResponseErrorStsCPIM_CPIM_HCP_FEEDBACK_Lin3
      data received event DRECOMRXL_ChrgPortLock_FailSts_CPIM_HCP_FEEDBACK_Lin3: start-on-event=COMRXL_ChrgPortLock_FailSts_CPIM_HCP_FEEDBACK_Lin3_Received, data=Lin3ComRxSignalsSR.COMRXL_ChrgPortLock_FailSts_CPIM_HCP_FEEDBACK_Lin3
      data receive error event DEECOMRXL_ChrgPortLock_FailSts_CPIM_HCP_FEEDBACK_Lin3: start-on-event=COMRXL_ChrgPortLock_FailSts_CPIM_HCP_FEEDBACK_Lin3_Error, data=Lin3ComRxSignalsSR.COMRXL_ChrgPortLock_FailSts_CPIM_HCP_FEEDBACK_Lin3
      data received event DRECOMRXL_Icon1_Sts_CPIM_HCP_FEEDBACK_Lin3: start-on-event=COMRXL_Icon1_Sts_CPIM_HCP_FEEDBACK_Lin3_Received, data=Lin3ComRxSignalsSR.COMRXL_Icon1_Sts_CPIM_HCP_FEEDBACK_Lin3
      data receive error event DEECOMRXL_Icon1_Sts_CPIM_HCP_FEEDBACK_Lin3: start-on-event=COMRXL_Icon1_Sts_CPIM_HCP_FEEDBACK_Lin3_Error, data=Lin3ComRxSignalsSR.COMRXL_Icon1_Sts_CPIM_HCP_FEEDBACK_Lin3
      data received event DRECOMRXL_Icon1_FailSts_CPIM_HCP_FEEDBACK_Lin3: start-on-event=COMRXL_Icon1_FailSts_CPIM_HCP_FEEDBACK_Lin3_Received, data=Lin3ComRxSignalsSR.COMRXL_Icon1_FailSts_CPIM_HCP_FEEDBACK_Lin3
      data receive error event DEECOMRXL_Icon1_FailSts_CPIM_HCP_FEEDBACK_Lin3: start-on-event=COMRXL_Icon1_FailSts_CPIM_HCP_FEEDBACK_Lin3_Error, data=Lin3ComRxSignalsSR.COMRXL_Icon1_FailSts_CPIM_HCP_FEEDBACK_Lin3
      data received event DRECOMRXL_Icon2_Sts_CPIM_HCP_FEEDBACK_Lin3: start-on-event=COMRXL_Icon2_Sts_CPIM_HCP_FEEDBACK_Lin3_Received, data=Lin3ComRxSignalsSR.COMRXL_Icon2_Sts_CPIM_HCP_FEEDBACK_Lin3
      data receive error event DEECOMRXL_Icon2_Sts_CPIM_HCP_FEEDBACK_Lin3: start-on-event=COMRXL_Icon2_Sts_CPIM_HCP_FEEDBACK_Lin3_Error, data=Lin3ComRxSignalsSR.COMRXL_Icon2_Sts_CPIM_HCP_FEEDBACK_Lin3
      data received event DRECOMRXL_Icon2_FailSts_CPIM_HCP_FEEDBACK_Lin3: start-on-event=COMRXL_Icon2_FailSts_CPIM_HCP_FEEDBACK_Lin3_Received, data=Lin3ComRxSignalsSR.COMRXL_Icon2_FailSts_CPIM_HCP_FEEDBACK_Lin3
      data receive error event DEECOMRXL_Icon2_FailSts_CPIM_HCP_FEEDBACK_Lin3: start-on-event=COMRXL_Icon2_FailSts_CPIM_HCP_FEEDBACK_Lin3_Error, data=Lin3ComRxSignalsSR.COMRXL_Icon2_FailSts_CPIM_HCP_FEEDBACK_Lin3
      data received event DRECOMRXL_ChrgPortDoor_Sts_CPIM_HCP_FEEDBACK_Lin3: start-on-event=COMRXL_ChrgPortDoor_Sts_CPIM_HCP_FEEDBACK_Lin3_Received, data=Lin3ComRxSignalsSR.COMRXL_ChrgPortDoor_Sts_CPIM_HCP_FEEDBACK_Lin3
      data receive error event DEECOMRXL_ChrgPortDoor_Sts_CPIM_HCP_FEEDBACK_Lin3: start-on-event=COMRXL_ChrgPortDoor_Sts_CPIM_HCP_FEEDBACK_Lin3_Error, data=Lin3ComRxSignalsSR.COMRXL_ChrgPortDoor_Sts_CPIM_HCP_FEEDBACK_Lin3
      data received event DRECOMRXL_HvCooltHeatrSts_HVCHLIN18Fr01_Lin3: start-on-event=COMRXL_HvCooltHeatrSts_HVCHLIN18Fr01_Lin3_Received, data=Lin3ComRxSignalsSR.COMRXL_HvCooltHeatrSts_HVCHLIN18Fr01_Lin3
      data receive error event DEECOMRXL_HvCooltHeatrSts_HVCHLIN18Fr01_Lin3: start-on-event=COMRXL_HvCooltHeatrSts_HVCHLIN18Fr01_Lin3_Error, data=Lin3ComRxSignalsSR.COMRXL_HvCooltHeatrSts_HVCHLIN18Fr01_Lin3
      data received event DRECOMRXL_ECH_InterlockStat_HVCHLIN18Fr01_Lin3: start-on-event=COMRXL_ECH_InterlockStat_HVCHLIN18Fr01_Lin3_Received, data=Lin3ComRxSignalsSR.COMRXL_ECH_InterlockStat_HVCHLIN18Fr01_Lin3
      data receive error event DEECOMRXL_ECH_InterlockStat_HVCHLIN18Fr01_Lin3: start-on-event=COMRXL_ECH_InterlockStat_HVCHLIN18Fr01_Lin3_Error, data=Lin3ComRxSignalsSR.COMRXL_ECH_InterlockStat_HVCHLIN18Fr01_Lin3
      data received event DRECOMRXL_Below_60V_HVCHLIN18Fr01_Lin3: start-on-event=COMRXL_Below_60V_HVCHLIN18Fr01_Lin3_Received, data=Lin3ComRxSignalsSR.COMRXL_Below_60V_HVCHLIN18Fr01_Lin3
      data receive error event DEECOMRXL_Below_60V_HVCHLIN18Fr01_Lin3: start-on-event=COMRXL_Below_60V_HVCHLIN18Fr01_Lin3_Error, data=Lin3ComRxSignalsSR.COMRXL_Below_60V_HVCHLIN18Fr01_Lin3
      data received event DRECOMRXL_HvCooltWtrHeatrWtrTInIntk_HVCHLIN18Fr01_Lin3: start-on-event=COMRXL_HvCooltWtrHeatrWtrTInIntk_HVCHLIN18Fr01_Lin3_Received, data=Lin3ComRxSignalsSR.COMRXL_HvCooltWtrHeatrWtrTInIntk_HVCHLIN18Fr01_Lin3
      data receive error event DEECOMRXL_HvCooltWtrHeatrWtrTInIntk_HVCHLIN18Fr01_Lin3: start-on-event=COMRXL_HvCooltWtrHeatrWtrTInIntk_HVCHLIN18Fr01_Lin3_Error, data=Lin3ComRxSignalsSR.COMRXL_HvCooltWtrHeatrWtrTInIntk_HVCHLIN18Fr01_Lin3
      data received event DRECOMRXL_HvWtrHeatrWtrT_HVCHLIN18Fr01_Lin3: start-on-event=COMRXL_HvWtrHeatrWtrT_HVCHLIN18Fr01_Lin3_Received, data=Lin3ComRxSignalsSR.COMRXL_HvWtrHeatrWtrT_HVCHLIN18Fr01_Lin3
      data receive error event DEECOMRXL_HvWtrHeatrWtrT_HVCHLIN18Fr01_Lin3: start-on-event=COMRXL_HvWtrHeatrWtrT_HVCHLIN18Fr01_Lin3_Error, data=Lin3ComRxSignalsSR.COMRXL_HvWtrHeatrWtrT_HVCHLIN18Fr01_Lin3
      data received event DRECOMRXL_HvCooltHeatrICns_HVCHLIN18Fr01_Lin3: start-on-event=COMRXL_HvCooltHeatrICns_HVCHLIN18Fr01_Lin3_Received, data=Lin3ComRxSignalsSR.COMRXL_HvCooltHeatrICns_HVCHLIN18Fr01_Lin3
      data receive error event DEECOMRXL_HvCooltHeatrICns_HVCHLIN18Fr01_Lin3: start-on-event=COMRXL_HvCooltHeatrICns_HVCHLIN18Fr01_Lin3_Error, data=Lin3ComRxSignalsSR.COMRXL_HvCooltHeatrICns_HVCHLIN18Fr01_Lin3
      data received event DRECOMRXL_HvCooltHVmeas_HVCHLIN18Fr01_Lin3: start-on-event=COMRXL_HvCooltHVmeas_HVCHLIN18Fr01_Lin3_Received, data=Lin3ComRxSignalsSR.COMRXL_HvCooltHVmeas_HVCHLIN18Fr01_Lin3
      data receive error event DEECOMRXL_HvCooltHVmeas_HVCHLIN18Fr01_Lin3: start-on-event=COMRXL_HvCooltHVmeas_HVCHLIN18Fr01_Lin3_Error, data=Lin3ComRxSignalsSR.COMRXL_HvCooltHVmeas_HVCHLIN18Fr01_Lin3
      data received event DRECOMRXL_HvHeatrPwrCns_HVCHLIN18Fr01_Lin3: start-on-event=COMRXL_HvHeatrPwrCns_HVCHLIN18Fr01_Lin3_Received, data=Lin3ComRxSignalsSR.COMRXL_HvHeatrPwrCns_HVCHLIN18Fr01_Lin3
      data receive error event DEECOMRXL_HvHeatrPwrCns_HVCHLIN18Fr01_Lin3: start-on-event=COMRXL_HvHeatrPwrCns_HVCHLIN18Fr01_Lin3_Error, data=Lin3ComRxSignalsSR.COMRXL_HvHeatrPwrCns_HVCHLIN18Fr01_Lin3
      data received event DRECOMRXL_HvHeatrPwrCnsDes_HVCHLIN18Fr01_Lin3: start-on-event=COMRXL_HvHeatrPwrCnsDes_HVCHLIN18Fr01_Lin3_Received, data=Lin3ComRxSignalsSR.COMRXL_HvHeatrPwrCnsDes_HVCHLIN18Fr01_Lin3
      data receive error event DEECOMRXL_HvHeatrPwrCnsDes_HVCHLIN18Fr01_Lin3: start-on-event=COMRXL_HvHeatrPwrCnsDes_HVCHLIN18Fr01_Lin3_Error, data=Lin3ComRxSignalsSR.COMRXL_HvHeatrPwrCnsDes_HVCHLIN18Fr01_Lin3
      data received event DRECOMRXL_HVH_UnlockCounter_HVCHLIN18Fr01_Lin3: start-on-event=COMRXL_HVH_UnlockCounter_HVCHLIN18Fr01_Lin3_Received, data=Lin3ComRxSignalsSR.COMRXL_HVH_UnlockCounter_HVCHLIN18Fr01_Lin3
      data receive error event DEECOMRXL_HVH_UnlockCounter_HVCHLIN18Fr01_Lin3: start-on-event=COMRXL_HVH_UnlockCounter_HVCHLIN18Fr01_Lin3_Error, data=Lin3ComRxSignalsSR.COMRXL_HVH_UnlockCounter_HVCHLIN18Fr01_Lin3
      data received event DRECOMRXL_RsErr_ECH_HVCHLIN18Fr02_Lin3: start-on-event=COMRXL_RsErr_ECH_HVCHLIN18Fr02_Lin3_Received, data=Lin3ComRxSignalsSR.COMRXL_RsErr_ECH_HVCHLIN18Fr02_Lin3
      data receive error event DEECOMRXL_RsErr_ECH_HVCHLIN18Fr02_Lin3: start-on-event=COMRXL_RsErr_ECH_HVCHLIN18Fr02_Lin3_Error, data=Lin3ComRxSignalsSR.COMRXL_RsErr_ECH_HVCHLIN18Fr02_Lin3
      data received event DRECOMRXL_HvCooltHeatrWarnFltInCom_HVCHLIN18Fr02_Lin3: start-on-event=COMRXL_HvCooltHeatrWarnFltInCom_HVCHLIN18Fr02_Lin3_Received, data=Lin3ComRxSignalsSR.COMRXL_HvCooltHeatrWarnFltInCom_HVCHLIN18Fr02_Lin3
      data receive error event DEECOMRXL_HvCooltHeatrWarnFltInCom_HVCHLIN18Fr02_Lin3: start-on-event=COMRXL_HvCooltHeatrWarnFltInCom_HVCHLIN18Fr02_Lin3_Error, data=Lin3ComRxSignalsSR.COMRXL_HvCooltHeatrWarnFltInCom_HVCHLIN18Fr02_Lin3
      data received event DRECOMRXL_HvCooltHeatrWarnHvOutOfRng_HVCHLIN18Fr02_Lin3: start-on-event=COMRXL_HvCooltHeatrWarnHvOutOfRng_HVCHLIN18Fr02_Lin3_Received, data=Lin3ComRxSignalsSR.COMRXL_HvCooltHeatrWarnHvOutOfRng_HVCHLIN18Fr02_Lin3
      data receive error event DEECOMRXL_HvCooltHeatrWarnHvOutOfRng_HVCHLIN18Fr02_Lin3: start-on-event=COMRXL_HvCooltHeatrWarnHvOutOfRng_HVCHLIN18Fr02_Lin3_Error, data=Lin3ComRxSignalsSR.COMRXL_HvCooltHeatrWarnHvOutOfRng_HVCHLIN18Fr02_Lin3
      data received event DRECOMRXL_HvCooltHeatrWarnULoOutOfRng_HVCHLIN18Fr02_Lin3: start-on-event=COMRXL_HvCooltHeatrWarnULoOutOfRng_HVCHLIN18Fr02_Lin3_Received, data=Lin3ComRxSignalsSR.COMRXL_HvCooltHeatrWarnULoOutOfRng_HVCHLIN18Fr02_Lin3
      data receive error event DEECOMRXL_HvCooltHeatrWarnULoOutOfRng_HVCHLIN18Fr02_Lin3: start-on-event=COMRXL_HvCooltHeatrWarnULoOutOfRng_HVCHLIN18Fr02_Lin3_Error, data=Lin3ComRxSignalsSR.COMRXL_HvCooltHeatrWarnULoOutOfRng_HVCHLIN18Fr02_Lin3
      data received event DRECOMRXL_HvCooltHeatrWarnCooltTOutOfRng_HVCHLIN18Fr02_Lin3: start-on-event=COMRXL_HvCooltHeatrWarnCooltTOutOfRng_HVCHLIN18Fr02_Lin3_Received, data=Lin3ComRxSignalsSR.COMRXL_HvCooltHeatrWarnCooltTOutOfRng_HVCHLIN18Fr02_Lin3
      data receive error event DEECOMRXL_HvCooltHeatrWarnCooltTOutOfRng_HVCHLIN18Fr02_Lin3: start-on-event=COMRXL_HvCooltHeatrWarnCooltTOutOfRng_HVCHLIN18Fr02_Lin3_Error, data=Lin3ComRxSignalsSR.COMRXL_HvCooltHeatrWarnCooltTOutOfRng_HVCHLIN18Fr02_Lin3
      data received event DRECOMRXL_HvCooltHeatrProtnOfSelfTmpHwProtn_HVCHLIN18Fr02_Lin3: start-on-event=COMRXL_HvCooltHeatrProtnOfSelfTmpHwProtn_HVCHLIN18Fr02_Lin3_Received, data=Lin3ComRxSignalsSR.COMRXL_HvCooltHeatrProtnOfSelfTmpHwProtn_HVCHLIN18Fr02_Lin3
      data receive error event DEECOMRXL_HvCooltHeatrProtnOfSelfTmpHwProtn_HVCHLIN18Fr02_Lin3: start-on-event=COMRXL_HvCooltHeatrProtnOfSelfTmpHwProtn_HVCHLIN18Fr02_Lin3_Error, data=Lin3ComRxSignalsSR.COMRXL_HvCooltHeatrProtnOfSelfTmpHwProtn_HVCHLIN18Fr02_Lin3
      data received event DRECOMRXL_HvCooltHeatrProtnOfSelfTmpOvrheatg_HVCHLIN18Fr02_Lin3: start-on-event=COMRXL_HvCooltHeatrProtnOfSelfTmpOvrheatg_HVCHLIN18Fr02_Lin3_Received, data=Lin3ComRxSignalsSR.COMRXL_HvCooltHeatrProtnOfSelfTmpOvrheatg_HVCHLIN18Fr02_Lin3
      data receive error event DEECOMRXL_HvCooltHeatrProtnOfSelfTmpOvrheatg_HVCHLIN18Fr02_Lin3: start-on-event=COMRXL_HvCooltHeatrProtnOfSelfTmpOvrheatg_HVCHLIN18Fr02_Lin3_Error, data=Lin3ComRxSignalsSR.COMRXL_HvCooltHeatrProtnOfSelfTmpOvrheatg_HVCHLIN18Fr02_Lin3
      data received event DRECOMRXL_HvCooltHeatrSnsrFltCooltTInSnsrFlt_HVCHLIN18Fr02_Lin3: start-on-event=COMRXL_HvCooltHeatrSnsrFltCooltTInSnsrFlt_HVCHLIN18Fr02_Lin3_Received, data=Lin3ComRxSignalsSR.COMRXL_HvCooltHeatrSnsrFltCooltTInSnsrFlt_HVCHLIN18Fr02_Lin3
      data receive error event DEECOMRXL_HvCooltHeatrSnsrFltCooltTInSnsrFlt_HVCHLIN18Fr02_Lin3: start-on-event=COMRXL_HvCooltHeatrSnsrFltCooltTInSnsrFlt_HVCHLIN18Fr02_Lin3_Error, data=Lin3ComRxSignalsSR.COMRXL_HvCooltHeatrSnsrFltCooltTInSnsrFlt_HVCHLIN18Fr02_Lin3
      data received event DRECOMRXL_HvCooltHeatrSnsrFltCooltTOutSnsrFlt_HVCHLIN18Fr02_Lin3: start-on-event=COMRXL_HvCooltHeatrSnsrFltCooltTOutSnsrFlt_HVCHLIN18Fr02_Lin3_Received, data=Lin3ComRxSignalsSR.COMRXL_HvCooltHeatrSnsrFltCooltTOutSnsrFlt_HVCHLIN18Fr02_Lin3
      data receive error event DEECOMRXL_HvCooltHeatrSnsrFltCooltTOutSnsrFlt_HVCHLIN18Fr02_Lin3: start-on-event=COMRXL_HvCooltHeatrSnsrFltCooltTOutSnsrFlt_HVCHLIN18Fr02_Lin3_Error, data=Lin3ComRxSignalsSR.COMRXL_HvCooltHeatrSnsrFltCooltTOutSnsrFlt_HVCHLIN18Fr02_Lin3
      data received event DRECOMRXL_HvCooltHeatrSnsrFltTInMtrlSnsrFlt_HVCHLIN18Fr02_Lin3: start-on-event=COMRXL_HvCooltHeatrSnsrFltTInMtrlSnsrFlt_HVCHLIN18Fr02_Lin3_Received, data=Lin3ComRxSignalsSR.COMRXL_HvCooltHeatrSnsrFltTInMtrlSnsrFlt_HVCHLIN18Fr02_Lin3
      data receive error event DEECOMRXL_HvCooltHeatrSnsrFltTInMtrlSnsrFlt_HVCHLIN18Fr02_Lin3: start-on-event=COMRXL_HvCooltHeatrSnsrFltTInMtrlSnsrFlt_HVCHLIN18Fr02_Lin3_Error, data=Lin3ComRxSignalsSR.COMRXL_HvCooltHeatrSnsrFltTInMtrlSnsrFlt_HVCHLIN18Fr02_Lin3
      data received event DRECOMRXL_HvCooltHeatrSrvRqrdCircForDrvrShoOrOpen_HVCHLIN18Fr02_Lin3: start-on-event=COMRXL_HvCooltHeatrSrvRqrdCircForDrvrShoOrOpen_HVCHLIN18Fr02_Lin3_Received, data=Lin3ComRxSignalsSR.COMRXL_HvCooltHeatrSrvRqrdCircForDrvrShoOrOpen_HVCHLIN18Fr02_Lin3
      data receive error event DEECOMRXL_HvCooltHeatrSrvRqrdCircForDrvrShoOrOpen_HVCHLIN18Fr02_Lin3: start-on-event=COMRXL_HvCooltHeatrSrvRqrdCircForDrvrShoOrOpen_HVCHLIN18Fr02_Lin3_Error, data=Lin3ComRxSignalsSR.COMRXL_HvCooltHeatrSrvRqrdCircForDrvrShoOrOpen_HVCHLIN18Fr02_Lin3
      data received event DRECOMRXL_HvCooltHeatrSrvRqrdICnsOutOfRng_HVCHLIN18Fr02_Lin3: start-on-event=COMRXL_HvCooltHeatrSrvRqrdICnsOutOfRng_HVCHLIN18Fr02_Lin3_Received, data=Lin3ComRxSignalsSR.COMRXL_HvCooltHeatrSrvRqrdICnsOutOfRng_HVCHLIN18Fr02_Lin3
      data receive error event DEECOMRXL_HvCooltHeatrSrvRqrdICnsOutOfRng_HVCHLIN18Fr02_Lin3: start-on-event=COMRXL_HvCooltHeatrSrvRqrdICnsOutOfRng_HVCHLIN18Fr02_Lin3_Error, data=Lin3ComRxSignalsSR.COMRXL_HvCooltHeatrSrvRqrdICnsOutOfRng_HVCHLIN18Fr02_Lin3
      data received event DRECOMRXL_HvCooltHeatrSrvRqrdMemErr_HVCHLIN18Fr02_Lin3: start-on-event=COMRXL_HvCooltHeatrSrvRqrdMemErr_HVCHLIN18Fr02_Lin3_Received, data=Lin3ComRxSignalsSR.COMRXL_HvCooltHeatrSrvRqrdMemErr_HVCHLIN18Fr02_Lin3
      data receive error event DEECOMRXL_HvCooltHeatrSrvRqrdMemErr_HVCHLIN18Fr02_Lin3: start-on-event=COMRXL_HvCooltHeatrSrvRqrdMemErr_HVCHLIN18Fr02_Lin3_Error, data=Lin3ComRxSignalsSR.COMRXL_HvCooltHeatrSrvRqrdMemErr_HVCHLIN18Fr02_Lin3
      data received event DRECOMRXL_HvCooltHeatrSrvRqrdSrvRqrd_HVCHLIN18Fr02_Lin3: start-on-event=COMRXL_HvCooltHeatrSrvRqrdSrvRqrd_HVCHLIN18Fr02_Lin3_Received, data=Lin3ComRxSignalsSR.COMRXL_HvCooltHeatrSrvRqrdSrvRqrd_HVCHLIN18Fr02_Lin3
      data receive error event DEECOMRXL_HvCooltHeatrSrvRqrdSrvRqrd_HVCHLIN18Fr02_Lin3: start-on-event=COMRXL_HvCooltHeatrSrvRqrdSrvRqrd_HVCHLIN18Fr02_Lin3_Error, data=Lin3ComRxSignalsSR.COMRXL_HvCooltHeatrSrvRqrdSrvRqrd_HVCHLIN18Fr02_Lin3
      data received event DRECOMRXL_EOPB_RPM_TGT_EOPB_STAT_Lin3: start-on-event=COMRXL_EOPB_RPM_TGT_EOPB_STAT_Lin3_Received, data=Lin3ComRxSignalsSR.COMRXL_EOPB_RPM_TGT_EOPB_STAT_Lin3
      data receive error event DEECOMRXL_EOPB_RPM_TGT_EOPB_STAT_Lin3: start-on-event=COMRXL_EOPB_RPM_TGT_EOPB_STAT_Lin3_Error, data=Lin3ComRxSignalsSR.COMRXL_EOPB_RPM_TGT_EOPB_STAT_Lin3
      data received event DRECOMRXL_EOPB_RPM_ACTL_EOPB_STAT_Lin3: start-on-event=COMRXL_EOPB_RPM_ACTL_EOPB_STAT_Lin3_Received, data=Lin3ComRxSignalsSR.COMRXL_EOPB_RPM_ACTL_EOPB_STAT_Lin3
      data receive error event DEECOMRXL_EOPB_RPM_ACTL_EOPB_STAT_Lin3: start-on-event=COMRXL_EOPB_RPM_ACTL_EOPB_STAT_Lin3_Error, data=Lin3ComRxSignalsSR.COMRXL_EOPB_RPM_ACTL_EOPB_STAT_Lin3
      data received event DRECOMRXL_EOPB_VLTG_EOPB_STAT_Lin3: start-on-event=COMRXL_EOPB_VLTG_EOPB_STAT_Lin3_Received, data=Lin3ComRxSignalsSR.COMRXL_EOPB_VLTG_EOPB_STAT_Lin3
      data receive error event DEECOMRXL_EOPB_VLTG_EOPB_STAT_Lin3: start-on-event=COMRXL_EOPB_VLTG_EOPB_STAT_Lin3_Error, data=Lin3ComRxSignalsSR.COMRXL_EOPB_VLTG_EOPB_STAT_Lin3
      data received event DRECOMRXL_EOPB_TEMP_EOPB_STAT_Lin3: start-on-event=COMRXL_EOPB_TEMP_EOPB_STAT_Lin3_Received, data=Lin3ComRxSignalsSR.COMRXL_EOPB_TEMP_EOPB_STAT_Lin3
      data receive error event DEECOMRXL_EOPB_TEMP_EOPB_STAT_Lin3: start-on-event=COMRXL_EOPB_TEMP_EOPB_STAT_Lin3_Error, data=Lin3ComRxSignalsSR.COMRXL_EOPB_TEMP_EOPB_STAT_Lin3
      data received event DRECOMRXL_EOPB_CURR_EOPB_STAT_Lin3: start-on-event=COMRXL_EOPB_CURR_EOPB_STAT_Lin3_Received, data=Lin3ComRxSignalsSR.COMRXL_EOPB_CURR_EOPB_STAT_Lin3
      data receive error event DEECOMRXL_EOPB_CURR_EOPB_STAT_Lin3: start-on-event=COMRXL_EOPB_CURR_EOPB_STAT_Lin3_Error, data=Lin3ComRxSignalsSR.COMRXL_EOPB_CURR_EOPB_STAT_Lin3
      data received event DRECOMRXL_EOPB_LOW_TMP_STAT_EOPB_STAT_Lin3: start-on-event=COMRXL_EOPB_LOW_TMP_STAT_EOPB_STAT_Lin3_Received, data=Lin3ComRxSignalsSR.COMRXL_EOPB_LOW_TMP_STAT_EOPB_STAT_Lin3
      data receive error event DEECOMRXL_EOPB_LOW_TMP_STAT_EOPB_STAT_Lin3: start-on-event=COMRXL_EOPB_LOW_TMP_STAT_EOPB_STAT_Lin3_Error, data=Lin3ComRxSignalsSR.COMRXL_EOPB_LOW_TMP_STAT_EOPB_STAT_Lin3
      data received event DRECOMRXL_EOPB_MONTRNG_RPM_EOPB_STAT_Lin3: start-on-event=COMRXL_EOPB_MONTRNG_RPM_EOPB_STAT_Lin3_Received, data=Lin3ComRxSignalsSR.COMRXL_EOPB_MONTRNG_RPM_EOPB_STAT_Lin3
      data receive error event DEECOMRXL_EOPB_MONTRNG_RPM_EOPB_STAT_Lin3: start-on-event=COMRXL_EOPB_MONTRNG_RPM_EOPB_STAT_Lin3_Error, data=Lin3ComRxSignalsSR.COMRXL_EOPB_MONTRNG_RPM_EOPB_STAT_Lin3
      data received event DRECOMRXL_EOPB_LMP_HM_AN_ON_EOPB_STAT_Lin3: start-on-event=COMRXL_EOPB_LMP_HM_AN_ON_EOPB_STAT_Lin3_Received, data=Lin3ComRxSignalsSR.COMRXL_EOPB_LMP_HM_AN_ON_EOPB_STAT_Lin3
      data receive error event DEECOMRXL_EOPB_LMP_HM_AN_ON_EOPB_STAT_Lin3: start-on-event=COMRXL_EOPB_LMP_HM_AN_ON_EOPB_STAT_Lin3_Error, data=Lin3ComRxSignalsSR.COMRXL_EOPB_LMP_HM_AN_ON_EOPB_STAT_Lin3
      data received event DRECOMRXL_EOPB_OV_TMP_ER_EOPB_STAT_Lin3: start-on-event=COMRXL_EOPB_OV_TMP_ER_EOPB_STAT_Lin3_Received, data=Lin3ComRxSignalsSR.COMRXL_EOPB_OV_TMP_ER_EOPB_STAT_Lin3
      data receive error event DEECOMRXL_EOPB_OV_TMP_ER_EOPB_STAT_Lin3: start-on-event=COMRXL_EOPB_OV_TMP_ER_EOPB_STAT_Lin3_Error, data=Lin3ComRxSignalsSR.COMRXL_EOPB_OV_TMP_ER_EOPB_STAT_Lin3
      data received event DRECOMRXL_EOPB_OV_CUR_ER_EOPB_STAT_Lin3: start-on-event=COMRXL_EOPB_OV_CUR_ER_EOPB_STAT_Lin3_Received, data=Lin3ComRxSignalsSR.COMRXL_EOPB_OV_CUR_ER_EOPB_STAT_Lin3
      data receive error event DEECOMRXL_EOPB_OV_CUR_ER_EOPB_STAT_Lin3: start-on-event=COMRXL_EOPB_OV_CUR_ER_EOPB_STAT_Lin3_Error, data=Lin3ComRxSignalsSR.COMRXL_EOPB_OV_CUR_ER_EOPB_STAT_Lin3
      data received event DRECOMRXL_EOPB_DR_RN_ER_EOPB_STAT_Lin3: start-on-event=COMRXL_EOPB_DR_RN_ER_EOPB_STAT_Lin3_Received, data=Lin3ComRxSignalsSR.COMRXL_EOPB_DR_RN_ER_EOPB_STAT_Lin3
      data receive error event DEECOMRXL_EOPB_DR_RN_ER_EOPB_STAT_Lin3: start-on-event=COMRXL_EOPB_DR_RN_ER_EOPB_STAT_Lin3_Error, data=Lin3ComRxSignalsSR.COMRXL_EOPB_DR_RN_ER_EOPB_STAT_Lin3
      data received event DRECOMRXL_EOPB_VLTG_ER_EOPB_STAT_Lin3: start-on-event=COMRXL_EOPB_VLTG_ER_EOPB_STAT_Lin3_Received, data=Lin3ComRxSignalsSR.COMRXL_EOPB_VLTG_ER_EOPB_STAT_Lin3
      data receive error event DEECOMRXL_EOPB_VLTG_ER_EOPB_STAT_Lin3: start-on-event=COMRXL_EOPB_VLTG_ER_EOPB_STAT_Lin3_Error, data=Lin3ComRxSignalsSR.COMRXL_EOPB_VLTG_ER_EOPB_STAT_Lin3
      data received event DRECOMRXL_EOPB_Stall_Event_EOPB_STAT_Lin3: start-on-event=COMRXL_EOPB_Stall_Event_EOPB_STAT_Lin3_Received, data=Lin3ComRxSignalsSR.COMRXL_EOPB_Stall_Event_EOPB_STAT_Lin3
      data receive error event DEECOMRXL_EOPB_Stall_Event_EOPB_STAT_Lin3: start-on-event=COMRXL_EOPB_Stall_Event_EOPB_STAT_Lin3_Error, data=Lin3ComRxSignalsSR.COMRXL_EOPB_Stall_Event_EOPB_STAT_Lin3
      data received event DRECOMRXL_EOPB_POST_RUN_STAT_EOPB_STAT_Lin3: start-on-event=COMRXL_EOPB_POST_RUN_STAT_EOPB_STAT_Lin3_Received, data=Lin3ComRxSignalsSR.COMRXL_EOPB_POST_RUN_STAT_EOPB_STAT_Lin3
      data receive error event DEECOMRXL_EOPB_POST_RUN_STAT_EOPB_STAT_Lin3: start-on-event=COMRXL_EOPB_POST_RUN_STAT_EOPB_STAT_Lin3_Error, data=Lin3ComRxSignalsSR.COMRXL_EOPB_POST_RUN_STAT_EOPB_STAT_Lin3
      data received event DRECOMRXL_RsErr_EOPB_EOPB_STAT_Lin3: start-on-event=COMRXL_RsErr_EOPB_EOPB_STAT_Lin3_Received, data=Lin3ComRxSignalsSR.COMRXL_RsErr_EOPB_EOPB_STAT_Lin3
      data receive error event DEECOMRXL_RsErr_EOPB_EOPB_STAT_Lin3: start-on-event=COMRXL_RsErr_EOPB_EOPB_STAT_Lin3_Error, data=Lin3ComRxSignalsSR.COMRXL_RsErr_EOPB_EOPB_STAT_Lin3
      data received event DRECOMRXL_EOPB_OIL_TEMP_EOPB_STAT2_Lin3: start-on-event=COMRXL_EOPB_OIL_TEMP_EOPB_STAT2_Lin3_Received, data=Lin3ComRxSignalsSR.COMRXL_EOPB_OIL_TEMP_EOPB_STAT2_Lin3
      data receive error event DEECOMRXL_EOPB_OIL_TEMP_EOPB_STAT2_Lin3: start-on-event=COMRXL_EOPB_OIL_TEMP_EOPB_STAT2_Lin3_Error, data=Lin3ComRxSignalsSR.COMRXL_EOPB_OIL_TEMP_EOPB_STAT2_Lin3
      data received event DRECOMRXL_EOPB_HW_VER_EOPB_VER_Lin3: start-on-event=COMRXL_EOPB_HW_VER_EOPB_VER_Lin3_Received, data=Lin3ComRxSignalsSR.COMRXL_EOPB_HW_VER_EOPB_VER_Lin3
      data receive error event DEECOMRXL_EOPB_HW_VER_EOPB_VER_Lin3: start-on-event=COMRXL_EOPB_HW_VER_EOPB_VER_Lin3_Error, data=Lin3ComRxSignalsSR.COMRXL_EOPB_HW_VER_EOPB_VER_Lin3
      data received event DRECOMRXL_EOPB_SW_VER_EOPB_VER_Lin3: start-on-event=COMRXL_EOPB_SW_VER_EOPB_VER_Lin3_Received, data=Lin3ComRxSignalsSR.COMRXL_EOPB_SW_VER_EOPB_VER_Lin3
      data receive error event DEECOMRXL_EOPB_SW_VER_EOPB_VER_Lin3: start-on-event=COMRXL_EOPB_SW_VER_EOPB_VER_Lin3_Error, data=Lin3ComRxSignalsSR.COMRXL_EOPB_SW_VER_EOPB_VER_Lin3
      data received event DRECOMRXL_HTLBV_PosAct_HTLBV_STAT_Lin3: start-on-event=COMRXL_HTLBV_PosAct_HTLBV_STAT_Lin3_Received, data=Lin3ComRxSignalsSR.COMRXL_HTLBV_PosAct_HTLBV_STAT_Lin3
      data receive error event DEECOMRXL_HTLBV_PosAct_HTLBV_STAT_Lin3: start-on-event=COMRXL_HTLBV_PosAct_HTLBV_STAT_Lin3_Error, data=Lin3ComRxSignalsSR.COMRXL_HTLBV_PosAct_HTLBV_STAT_Lin3
      data received event DRECOMRXL_HTLBV_ERR_HTLBV_STAT_Lin3: start-on-event=COMRXL_HTLBV_ERR_HTLBV_STAT_Lin3_Received, data=Lin3ComRxSignalsSR.COMRXL_HTLBV_ERR_HTLBV_STAT_Lin3
      data receive error event DEECOMRXL_HTLBV_ERR_HTLBV_STAT_Lin3: start-on-event=COMRXL_HTLBV_ERR_HTLBV_STAT_Lin3_Error, data=Lin3ComRxSignalsSR.COMRXL_HTLBV_ERR_HTLBV_STAT_Lin3
      data received event DRECOMRXL_HTLBV_MotorVolt_HTLBV_STAT_Lin3: start-on-event=COMRXL_HTLBV_MotorVolt_HTLBV_STAT_Lin3_Received, data=Lin3ComRxSignalsSR.COMRXL_HTLBV_MotorVolt_HTLBV_STAT_Lin3
      data receive error event DEECOMRXL_HTLBV_MotorVolt_HTLBV_STAT_Lin3: start-on-event=COMRXL_HTLBV_MotorVolt_HTLBV_STAT_Lin3_Error, data=Lin3ComRxSignalsSR.COMRXL_HTLBV_MotorVolt_HTLBV_STAT_Lin3
      data received event DRECOMRXL_HTLBV_Sts_HTLBV_STAT_Lin3: start-on-event=COMRXL_HTLBV_Sts_HTLBV_STAT_Lin3_Received, data=Lin3ComRxSignalsSR.COMRXL_HTLBV_Sts_HTLBV_STAT_Lin3
      data receive error event DEECOMRXL_HTLBV_Sts_HTLBV_STAT_Lin3: start-on-event=COMRXL_HTLBV_Sts_HTLBV_STAT_Lin3_Error, data=Lin3ComRxSignalsSR.COMRXL_HTLBV_Sts_HTLBV_STAT_Lin3
      data received event DRECOMRXL_RsErr_HTLBV_HTLBV_STAT_Lin3: start-on-event=COMRXL_RsErr_HTLBV_HTLBV_STAT_Lin3_Received, data=Lin3ComRxSignalsSR.COMRXL_RsErr_HTLBV_HTLBV_STAT_Lin3
      data receive error event DEECOMRXL_RsErr_HTLBV_HTLBV_STAT_Lin3: start-on-event=COMRXL_RsErr_HTLBV_HTLBV_STAT_Lin3_Error, data=Lin3ComRxSignalsSR.COMRXL_RsErr_HTLBV_HTLBV_STAT_Lin3
      data received event DRECOMRXL_HTLBV_CalStat_HTLBV_STAT_Lin3: start-on-event=COMRXL_HTLBV_CalStat_HTLBV_STAT_Lin3_Received, data=Lin3ComRxSignalsSR.COMRXL_HTLBV_CalStat_HTLBV_STAT_Lin3
      data receive error event DEECOMRXL_HTLBV_CalStat_HTLBV_STAT_Lin3: start-on-event=COMRXL_HTLBV_CalStat_HTLBV_STAT_Lin3_Error, data=Lin3ComRxSignalsSR.COMRXL_HTLBV_CalStat_HTLBV_STAT_Lin3
      data received event DRECOMRXL_PECP2_RPM_TGT_PERCT_PECP2_STAT_GLOBAL_Lin3: start-on-event=COMRXL_PECP2_RPM_TGT_PERCT_PECP2_STAT_GLOBAL_Lin3_Received, data=Lin3ComRxSignalsSR.COMRXL_PECP2_RPM_TGT_PERCT_PECP2_STAT_GLOBAL_Lin3
      data receive error event DEECOMRXL_PECP2_RPM_TGT_PERCT_PECP2_STAT_GLOBAL_Lin3: start-on-event=COMRXL_PECP2_RPM_TGT_PERCT_PECP2_STAT_GLOBAL_Lin3_Error, data=Lin3ComRxSignalsSR.COMRXL_PECP2_RPM_TGT_PERCT_PECP2_STAT_GLOBAL_Lin3
      data received event DRECOMRXL_PECP2_RPM_ACTL_PERCT_PECP2_STAT_GLOBAL_Lin3: start-on-event=COMRXL_PECP2_RPM_ACTL_PERCT_PECP2_STAT_GLOBAL_Lin3_Received, data=Lin3ComRxSignalsSR.COMRXL_PECP2_RPM_ACTL_PERCT_PECP2_STAT_GLOBAL_Lin3
      data receive error event DEECOMRXL_PECP2_RPM_ACTL_PERCT_PECP2_STAT_GLOBAL_Lin3: start-on-event=COMRXL_PECP2_RPM_ACTL_PERCT_PECP2_STAT_GLOBAL_Lin3_Error, data=Lin3ComRxSignalsSR.COMRXL_PECP2_RPM_ACTL_PERCT_PECP2_STAT_GLOBAL_Lin3
      data received event DRECOMRXL_PECP2_VLTG_PECP2_STAT_GLOBAL_Lin3: start-on-event=COMRXL_PECP2_VLTG_PECP2_STAT_GLOBAL_Lin3_Received, data=Lin3ComRxSignalsSR.COMRXL_PECP2_VLTG_PECP2_STAT_GLOBAL_Lin3
      data receive error event DEECOMRXL_PECP2_VLTG_PECP2_STAT_GLOBAL_Lin3: start-on-event=COMRXL_PECP2_VLTG_PECP2_STAT_GLOBAL_Lin3_Error, data=Lin3ComRxSignalsSR.COMRXL_PECP2_VLTG_PECP2_STAT_GLOBAL_Lin3
      data received event DRECOMRXL_PECP2_TEMP_PECP2_STAT_GLOBAL_Lin3: start-on-event=COMRXL_PECP2_TEMP_PECP2_STAT_GLOBAL_Lin3_Received, data=Lin3ComRxSignalsSR.COMRXL_PECP2_TEMP_PECP2_STAT_GLOBAL_Lin3
      data receive error event DEECOMRXL_PECP2_TEMP_PECP2_STAT_GLOBAL_Lin3: start-on-event=COMRXL_PECP2_TEMP_PECP2_STAT_GLOBAL_Lin3_Error, data=Lin3ComRxSignalsSR.COMRXL_PECP2_TEMP_PECP2_STAT_GLOBAL_Lin3
      data received event DRECOMRXL_PECP2_CURR_PECP2_STAT_GLOBAL_Lin3: start-on-event=COMRXL_PECP2_CURR_PECP2_STAT_GLOBAL_Lin3_Received, data=Lin3ComRxSignalsSR.COMRXL_PECP2_CURR_PECP2_STAT_GLOBAL_Lin3
      data receive error event DEECOMRXL_PECP2_CURR_PECP2_STAT_GLOBAL_Lin3: start-on-event=COMRXL_PECP2_CURR_PECP2_STAT_GLOBAL_Lin3_Error, data=Lin3ComRxSignalsSR.COMRXL_PECP2_CURR_PECP2_STAT_GLOBAL_Lin3
      data received event DRECOMRXL_PECP2_FL_SAFE_ACTVTD_PECP2_STAT_GLOBAL_Lin3: start-on-event=COMRXL_PECP2_FL_SAFE_ACTVTD_PECP2_STAT_GLOBAL_Lin3_Received, data=Lin3ComRxSignalsSR.COMRXL_PECP2_FL_SAFE_ACTVTD_PECP2_STAT_GLOBAL_Lin3
      data receive error event DEECOMRXL_PECP2_FL_SAFE_ACTVTD_PECP2_STAT_GLOBAL_Lin3: start-on-event=COMRXL_PECP2_FL_SAFE_ACTVTD_PECP2_STAT_GLOBAL_Lin3_Error, data=Lin3ComRxSignalsSR.COMRXL_PECP2_FL_SAFE_ACTVTD_PECP2_STAT_GLOBAL_Lin3
      data received event DRECOMRXL_PECP2_LMP_HM_AN_ON_PECP2_STAT_GLOBAL_Lin3: start-on-event=COMRXL_PECP2_LMP_HM_AN_ON_PECP2_STAT_GLOBAL_Lin3_Received, data=Lin3ComRxSignalsSR.COMRXL_PECP2_LMP_HM_AN_ON_PECP2_STAT_GLOBAL_Lin3
      data receive error event DEECOMRXL_PECP2_LMP_HM_AN_ON_PECP2_STAT_GLOBAL_Lin3: start-on-event=COMRXL_PECP2_LMP_HM_AN_ON_PECP2_STAT_GLOBAL_Lin3_Error, data=Lin3ComRxSignalsSR.COMRXL_PECP2_LMP_HM_AN_ON_PECP2_STAT_GLOBAL_Lin3
      data received event DRECOMRXL_PECP2_AIR_PRE_ERR_PECP2_STAT_GLOBAL_Lin3: start-on-event=COMRXL_PECP2_AIR_PRE_ERR_PECP2_STAT_GLOBAL_Lin3_Received, data=Lin3ComRxSignalsSR.COMRXL_PECP2_AIR_PRE_ERR_PECP2_STAT_GLOBAL_Lin3
      data receive error event DEECOMRXL_PECP2_AIR_PRE_ERR_PECP2_STAT_GLOBAL_Lin3: start-on-event=COMRXL_PECP2_AIR_PRE_ERR_PECP2_STAT_GLOBAL_Lin3_Error, data=Lin3ComRxSignalsSR.COMRXL_PECP2_AIR_PRE_ERR_PECP2_STAT_GLOBAL_Lin3
      data received event DRECOMRXL_PECP2_OVR_TMP_ERR_PECP2_STAT_GLOBAL_Lin3: start-on-event=COMRXL_PECP2_OVR_TMP_ERR_PECP2_STAT_GLOBAL_Lin3_Received, data=Lin3ComRxSignalsSR.COMRXL_PECP2_OVR_TMP_ERR_PECP2_STAT_GLOBAL_Lin3
      data receive error event DEECOMRXL_PECP2_OVR_TMP_ERR_PECP2_STAT_GLOBAL_Lin3: start-on-event=COMRXL_PECP2_OVR_TMP_ERR_PECP2_STAT_GLOBAL_Lin3_Error, data=Lin3ComRxSignalsSR.COMRXL_PECP2_OVR_TMP_ERR_PECP2_STAT_GLOBAL_Lin3
      data received event DRECOMRXL_PECP2_OVR_CUR_ERR_PECP2_STAT_GLOBAL_Lin3: start-on-event=COMRXL_PECP2_OVR_CUR_ERR_PECP2_STAT_GLOBAL_Lin3_Received, data=Lin3ComRxSignalsSR.COMRXL_PECP2_OVR_CUR_ERR_PECP2_STAT_GLOBAL_Lin3
      data receive error event DEECOMRXL_PECP2_OVR_CUR_ERR_PECP2_STAT_GLOBAL_Lin3: start-on-event=COMRXL_PECP2_OVR_CUR_ERR_PECP2_STAT_GLOBAL_Lin3_Error, data=Lin3ComRxSignalsSR.COMRXL_PECP2_OVR_CUR_ERR_PECP2_STAT_GLOBAL_Lin3
      data received event DRECOMRXL_PECP2_DR_RN_ERR_PECP2_STAT_GLOBAL_Lin3: start-on-event=COMRXL_PECP2_DR_RN_ERR_PECP2_STAT_GLOBAL_Lin3_Received, data=Lin3ComRxSignalsSR.COMRXL_PECP2_DR_RN_ERR_PECP2_STAT_GLOBAL_Lin3
      data receive error event DEECOMRXL_PECP2_DR_RN_ERR_PECP2_STAT_GLOBAL_Lin3: start-on-event=COMRXL_PECP2_DR_RN_ERR_PECP2_STAT_GLOBAL_Lin3_Error, data=Lin3ComRxSignalsSR.COMRXL_PECP2_DR_RN_ERR_PECP2_STAT_GLOBAL_Lin3
      data received event DRECOMRXL_PECP2_VLTG_ERR_PECP2_STAT_GLOBAL_Lin3: start-on-event=COMRXL_PECP2_VLTG_ERR_PECP2_STAT_GLOBAL_Lin3_Received, data=Lin3ComRxSignalsSR.COMRXL_PECP2_VLTG_ERR_PECP2_STAT_GLOBAL_Lin3
      data receive error event DEECOMRXL_PECP2_VLTG_ERR_PECP2_STAT_GLOBAL_Lin3: start-on-event=COMRXL_PECP2_VLTG_ERR_PECP2_STAT_GLOBAL_Lin3_Error, data=Lin3ComRxSignalsSR.COMRXL_PECP2_VLTG_ERR_PECP2_STAT_GLOBAL_Lin3
      data received event DRECOMRXL_PECP2_DBLK_ACTV_PECP2_STAT_GLOBAL_Lin3: start-on-event=COMRXL_PECP2_DBLK_ACTV_PECP2_STAT_GLOBAL_Lin3_Received, data=Lin3ComRxSignalsSR.COMRXL_PECP2_DBLK_ACTV_PECP2_STAT_GLOBAL_Lin3
      data receive error event DEECOMRXL_PECP2_DBLK_ACTV_PECP2_STAT_GLOBAL_Lin3: start-on-event=COMRXL_PECP2_DBLK_ACTV_PECP2_STAT_GLOBAL_Lin3_Error, data=Lin3ComRxSignalsSR.COMRXL_PECP2_DBLK_ACTV_PECP2_STAT_GLOBAL_Lin3
      data received event DRECOMRXL_PECP2_MONTRNG_RPM_PECP2_STAT_GLOBAL_Lin3: start-on-event=COMRXL_PECP2_MONTRNG_RPM_PECP2_STAT_GLOBAL_Lin3_Received, data=Lin3ComRxSignalsSR.COMRXL_PECP2_MONTRNG_RPM_PECP2_STAT_GLOBAL_Lin3
      data receive error event DEECOMRXL_PECP2_MONTRNG_RPM_PECP2_STAT_GLOBAL_Lin3: start-on-event=COMRXL_PECP2_MONTRNG_RPM_PECP2_STAT_GLOBAL_Lin3_Error, data=Lin3ComRxSignalsSR.COMRXL_PECP2_MONTRNG_RPM_PECP2_STAT_GLOBAL_Lin3
      data received event DRECOMRXL_PECP2_NODE_ERR_PECP2_STAT_GLOBAL_Lin3: start-on-event=COMRXL_PECP2_NODE_ERR_PECP2_STAT_GLOBAL_Lin3_Received, data=Lin3ComRxSignalsSR.COMRXL_PECP2_NODE_ERR_PECP2_STAT_GLOBAL_Lin3
      data receive error event DEECOMRXL_PECP2_NODE_ERR_PECP2_STAT_GLOBAL_Lin3: start-on-event=COMRXL_PECP2_NODE_ERR_PECP2_STAT_GLOBAL_Lin3_Error, data=Lin3ComRxSignalsSR.COMRXL_PECP2_NODE_ERR_PECP2_STAT_GLOBAL_Lin3
      data received event DRECOMRXL_PECP2_POST_RUN_STAT_PECP2_STAT_GLOBAL_Lin3: start-on-event=COMRXL_PECP2_POST_RUN_STAT_PECP2_STAT_GLOBAL_Lin3_Received, data=Lin3ComRxSignalsSR.COMRXL_PECP2_POST_RUN_STAT_PECP2_STAT_GLOBAL_Lin3
      data receive error event DEECOMRXL_PECP2_POST_RUN_STAT_PECP2_STAT_GLOBAL_Lin3: start-on-event=COMRXL_PECP2_POST_RUN_STAT_PECP2_STAT_GLOBAL_Lin3_Error, data=Lin3ComRxSignalsSR.COMRXL_PECP2_POST_RUN_STAT_PECP2_STAT_GLOBAL_Lin3
      data received event DRECOMRXL_RsErr_PECP2_PUMP_PECP2_STAT_GLOBAL_Lin3: start-on-event=COMRXL_RsErr_PECP2_PUMP_PECP2_STAT_GLOBAL_Lin3_Received, data=Lin3ComRxSignalsSR.COMRXL_RsErr_PECP2_PUMP_PECP2_STAT_GLOBAL_Lin3
      data receive error event DEECOMRXL_RsErr_PECP2_PUMP_PECP2_STAT_GLOBAL_Lin3: start-on-event=COMRXL_RsErr_PECP2_PUMP_PECP2_STAT_GLOBAL_Lin3_Error, data=Lin3ComRxSignalsSR.COMRXL_RsErr_PECP2_PUMP_PECP2_STAT_GLOBAL_Lin3
      data received event DRECOMRXL_PECP2_VERSION_PECP2_VER_Lin3: start-on-event=COMRXL_PECP2_VERSION_PECP2_VER_Lin3_Received, data=Lin3ComRxSignalsSR.COMRXL_PECP2_VERSION_PECP2_VER_Lin3
      data receive error event DEECOMRXL_PECP2_VERSION_PECP2_VER_Lin3: start-on-event=COMRXL_PECP2_VERSION_PECP2_VER_Lin3_Error, data=Lin3ComRxSignalsSR.COMRXL_PECP2_VERSION_PECP2_VER_Lin3
      data received event DRECOMRXL_PECP2_SUPPLIER_PECP2_VER_Lin3: start-on-event=COMRXL_PECP2_SUPPLIER_PECP2_VER_Lin3_Received, data=Lin3ComRxSignalsSR.COMRXL_PECP2_SUPPLIER_PECP2_VER_Lin3
      data receive error event DEECOMRXL_PECP2_SUPPLIER_PECP2_VER_Lin3: start-on-event=COMRXL_PECP2_SUPPLIER_PECP2_VER_Lin3_Error, data=Lin3ComRxSignalsSR.COMRXL_PECP2_SUPPLIER_PECP2_VER_Lin3
      data received event DRECOMRXL_PowerPanel2_Button_State_PowerPanel2_STAT_Lin3: start-on-event=COMRXL_PowerPanel2_Button_State_PowerPanel2_STAT_Lin3_Received, data=Lin3ComRxSignalsSR.COMRXL_PowerPanel2_Button_State_PowerPanel2_STAT_Lin3
      data receive error event DEECOMRXL_PowerPanel2_Button_State_PowerPanel2_STAT_Lin3: start-on-event=COMRXL_PowerPanel2_Button_State_PowerPanel2_STAT_Lin3_Error, data=Lin3ComRxSignalsSR.COMRXL_PowerPanel2_Button_State_PowerPanel2_STAT_Lin3
      data received event DRECOMRXL_PowerPanel2_Lid_Switch_Sts_120A_PowerPanel2_STAT_Lin3: start-on-event=COMRXL_PowerPanel2_Lid_Switch_Sts_120A_PowerPanel2_STAT_Lin3_Received, data=Lin3ComRxSignalsSR.COMRXL_PowerPanel2_Lid_Switch_Sts_120A_PowerPanel2_STAT_Lin3
      data receive error event DEECOMRXL_PowerPanel2_Lid_Switch_Sts_120A_PowerPanel2_STAT_Lin3: start-on-event=COMRXL_PowerPanel2_Lid_Switch_Sts_120A_PowerPanel2_STAT_Lin3_Error, data=Lin3ComRxSignalsSR.COMRXL_PowerPanel2_Lid_Switch_Sts_120A_PowerPanel2_STAT_Lin3
      data received event DRECOMRXL_PowerPanel2_Lid_Switch_Sts_120B_PowerPanel2_STAT_Lin3: start-on-event=COMRXL_PowerPanel2_Lid_Switch_Sts_120B_PowerPanel2_STAT_Lin3_Received, data=Lin3ComRxSignalsSR.COMRXL_PowerPanel2_Lid_Switch_Sts_120B_PowerPanel2_STAT_Lin3
      data receive error event DEECOMRXL_PowerPanel2_Lid_Switch_Sts_120B_PowerPanel2_STAT_Lin3: start-on-event=COMRXL_PowerPanel2_Lid_Switch_Sts_120B_PowerPanel2_STAT_Lin3_Error, data=Lin3ComRxSignalsSR.COMRXL_PowerPanel2_Lid_Switch_Sts_120B_PowerPanel2_STAT_Lin3
      data received event DRECOMRXL_PowerPanel2_Lid_Switch_Sts_240_PowerPanel2_STAT_Lin3: start-on-event=COMRXL_PowerPanel2_Lid_Switch_Sts_240_PowerPanel2_STAT_Lin3_Received, data=Lin3ComRxSignalsSR.COMRXL_PowerPanel2_Lid_Switch_Sts_240_PowerPanel2_STAT_Lin3
      data receive error event DEECOMRXL_PowerPanel2_Lid_Switch_Sts_240_PowerPanel2_STAT_Lin3: start-on-event=COMRXL_PowerPanel2_Lid_Switch_Sts_240_PowerPanel2_STAT_Lin3_Error, data=Lin3ComRxSignalsSR.COMRXL_PowerPanel2_Lid_Switch_Sts_240_PowerPanel2_STAT_Lin3
      data received event DRECOMRXL_PowerPanel2_AC_Present_Sens1_PowerPanel2_STAT_Lin3: start-on-event=COMRXL_PowerPanel2_AC_Present_Sens1_PowerPanel2_STAT_Lin3_Received, data=Lin3ComRxSignalsSR.COMRXL_PowerPanel2_AC_Present_Sens1_PowerPanel2_STAT_Lin3
      data receive error event DEECOMRXL_PowerPanel2_AC_Present_Sens1_PowerPanel2_STAT_Lin3: start-on-event=COMRXL_PowerPanel2_AC_Present_Sens1_PowerPanel2_STAT_Lin3_Error, data=Lin3ComRxSignalsSR.COMRXL_PowerPanel2_AC_Present_Sens1_PowerPanel2_STAT_Lin3
      data received event DRECOMRXL_PowerPanel2_AC_Present_Sens2_PowerPanel2_STAT_Lin3: start-on-event=COMRXL_PowerPanel2_AC_Present_Sens2_PowerPanel2_STAT_Lin3_Received, data=Lin3ComRxSignalsSR.COMRXL_PowerPanel2_AC_Present_Sens2_PowerPanel2_STAT_Lin3
      data receive error event DEECOMRXL_PowerPanel2_AC_Present_Sens2_PowerPanel2_STAT_Lin3: start-on-event=COMRXL_PowerPanel2_AC_Present_Sens2_PowerPanel2_STAT_Lin3_Error, data=Lin3ComRxSignalsSR.COMRXL_PowerPanel2_AC_Present_Sens2_PowerPanel2_STAT_Lin3
      data received event DRECOMRXL_PowerPanel2_Fault_Reason_PowerPanel2_STAT_Lin3: start-on-event=COMRXL_PowerPanel2_Fault_Reason_PowerPanel2_STAT_Lin3_Received, data=Lin3ComRxSignalsSR.COMRXL_PowerPanel2_Fault_Reason_PowerPanel2_STAT_Lin3
      data receive error event DEECOMRXL_PowerPanel2_Fault_Reason_PowerPanel2_STAT_Lin3: start-on-event=COMRXL_PowerPanel2_Fault_Reason_PowerPanel2_STAT_Lin3_Error, data=Lin3ComRxSignalsSR.COMRXL_PowerPanel2_Fault_Reason_PowerPanel2_STAT_Lin3
      data received event DRECOMRXL_RsErr_SPP2_PowerPanel2_STAT_Lin3: start-on-event=COMRXL_RsErr_SPP2_PowerPanel2_STAT_Lin3_Received, data=Lin3ComRxSignalsSR.COMRXL_RsErr_SPP2_PowerPanel2_STAT_Lin3
      data receive error event DEECOMRXL_RsErr_SPP2_PowerPanel2_STAT_Lin3: start-on-event=COMRXL_RsErr_SPP2_PowerPanel2_STAT_Lin3_Error, data=Lin3ComRxSignalsSR.COMRXL_RsErr_SPP2_PowerPanel2_STAT_Lin3
      45 x data received event:
        DRESendLINR_AGS_PosRq: start-on-event=SendLINR_AGS_PosRq, data=SendLINR_AGS_PosRq.SendLINR_AGS_PosRq
        DRESendLINR_AGS_CalRq: start-on-event=SendLINR_AGS_CalRq, data=SendLINR_AGS_CalRq.SendLINR_AGS_CalRq
        DRESendLINR_AGS_BoostRq: start-on-event=SendLINR_AGS_BoostRq, data=SendLINR_AGS_BoostRq.SendLINR_AGS_BoostRq
        DRESendLINR_M2SRes2Bit: start-on-event=SendLINR_M2SRes2Bit, data=SendLINR_M2SRes2Bit.SendLINR_M2SRes2Bit
        DRESendLINR_M2SResByte{1..3}: start-on-event=SendLINR_M2SResByte{1..3}, data=SendLINR_M2SResByte{1..3}.SendLINR_M2SResByte{1..3}
        DRESendLINR_CEXV_PosRq: start-on-event=SendLINR_CEXV_PosRq, data=SendLINR_CEXV_PosRq.SendLINR_CEXV_PosRq
        DRESendLINR_CEXV_CalCmd: start-on-event=SendLINR_CEXV_CalCmd, data=SendLINR_CEXV_CalCmd.SendLINR_CEXV_CalCmd
        DRESendLINR_CPIM_SET_IND{1..5}: start-on-event=SendLINR_CPIM_SET_IND{1..5}, data=SendLINR_CPIM_SET_IND{1..5}.SendLINR_CPIM_SET_IND{1..5}
        DRESendLINR_CPIM_Blink_Rate: start-on-event=SendLINR_CPIM_Blink_Rate, data=SendLINR_CPIM_Blink_Rate.SendLINR_CPIM_Blink_Rate
        DRESendLINR_CPIM_IND_Color: start-on-event=SendLINR_CPIM_IND_Color, data=SendLINR_CPIM_IND_Color.SendLINR_CPIM_IND_Color
        DRESendLINR_ChrgPortLock_Cmd: start-on-event=SendLINR_ChrgPortLock_Cmd, data=SendLINR_ChrgPortLock_Cmd.SendLINR_ChrgPortLock_Cmd
        DRESendLINR_Set_Icon1_cmd: start-on-event=SendLINR_Set_Icon1_cmd, data=SendLINR_Set_Icon1_cmd.SendLINR_Set_Icon1_cmd
        DRESendLINR_Set_Icon2_cmd: start-on-event=SendLINR_Set_Icon2_cmd, data=SendLINR_Set_Icon2_cmd.SendLINR_Set_Icon2_cmd
        DRESendLINR_DAY_LGT_MD_CPIM: start-on-event=SendLINR_DAY_LGT_MD_CPIM, data=SendLINR_DAY_LGT_MD_CPIM.SendLINR_DAY_LGT_MD_CPIM
        DRESendLINR_Backlight_Cmd: start-on-event=SendLINR_Backlight_Cmd, data=SendLINR_Backlight_Cmd.SendLINR_Backlight_Cmd
        DRESendLINR_HvWtrHeatrPwrCnsAllwd: start-on-event=SendLINR_HvWtrHeatrPwrCnsAllwd, data=SendLINR_HvWtrHeatrPwrCnsAllwd.SendLINR_HvWtrHeatrPwrCnsAllwd
        DRESendLINR_HvWtrHeatrWtrTDes: start-on-event=SendLINR_HvWtrHeatrWtrTDes, data=SendLINR_HvWtrHeatrWtrTDes.SendLINR_HvWtrHeatrWtrTDes
        DRESendLINR_HvCooltHeatrEnad: start-on-event=SendLINR_HvCooltHeatrEnad, data=SendLINR_HvCooltHeatrEnad.SendLINR_HvCooltHeatrEnad
        DRESendLINR_HVH_OverheatUnlock: start-on-event=SendLINR_HVH_OverheatUnlock, data=SendLINR_HVH_OverheatUnlock.SendLINR_HVH_OverheatUnlock
        DRESendLINR_EOPB_RPM_COM: start-on-event=SendLINR_EOPB_RPM_COM, data=SendLINR_EOPB_RPM_COM.SendLINR_EOPB_RPM_COM
        DRESendLINR_EOPB_POST_RUN_COM: start-on-event=SendLINR_EOPB_POST_RUN_COM, data=SendLINR_EOPB_POST_RUN_COM.SendLINR_EOPB_POST_RUN_COM
        DRESendLINR_HTLBV_PosRq: start-on-event=SendLINR_HTLBV_PosRq, data=SendLINR_HTLBV_PosRq.SendLINR_HTLBV_PosRq
        DRESendLINR_HTLBV_PosSv: start-on-event=SendLINR_HTLBV_PosSv, data=SendLINR_HTLBV_PosSv.SendLINR_HTLBV_PosSv
        DRESendLINR_HTLBV_CalRq: start-on-event=SendLINR_HTLBV_CalRq, data=SendLINR_HTLBV_CalRq.SendLINR_HTLBV_CalRq
        DRESendLINR_PECP2_RPM_REQ_PERCT: start-on-event=SendLINR_PECP2_RPM_REQ_PERCT, data=SendLINR_PECP2_RPM_REQ_PERCT.SendLINR_PECP2_RPM_REQ_PERCT
        DRESendLINR_PECP2_POST_RUN_REQ: start-on-event=SendLINR_PECP2_POST_RUN_REQ, data=SendLINR_PECP2_POST_RUN_REQ.SendLINR_PECP2_POST_RUN_REQ
        DRESendLINR_PECP2_FL_SAFE_ACTVT: start-on-event=SendLINR_PECP2_FL_SAFE_ACTVT, data=SendLINR_PECP2_FL_SAFE_ACTVT.SendLINR_PECP2_FL_SAFE_ACTVT
        DRESendLINR_PowerPanel2_LED_A_Cmnd: start-on-event=SendLINR_PowerPanel2_LED_A_Cmnd, data=SendLINR_PowerPanel2_LED_A_Cmnd.SendLINR_PowerPanel2_LED_A_Cmnd
        DRESendLINR_PowerPanel2_LED_B_Cmnd: start-on-event=SendLINR_PowerPanel2_LED_B_Cmnd, data=SendLINR_PowerPanel2_LED_B_Cmnd.SendLINR_PowerPanel2_LED_B_Cmnd
        DRESendLINR_DAY_LGT_MD_PowerPanel2: start-on-event=SendLINR_DAY_LGT_MD_PowerPanel2, data=SendLINR_DAY_LGT_MD_PowerPanel2.SendLINR_DAY_LGT_MD_PowerPanel2
        DRESignalLINR_AGS_RdyForSleep: start-on-event=SignalLINR_AGS_RdyForSleep, data=SignalLINR_AGS_RdyForSleep.SignalLINR_AGS_RdyForSleep
          disabled-mode:
            MdulPwrMod.AppMode_MDGP_ESH_Mode.RUN
            MdulPwrMod.AppMode_MDGP_ESH_Mode.STARTUP
            MdulPwrMod.AppMode_MDGP_ESH_Mode.SHUTDOWN
            MdulPwrMod.AppMode_MDGP_ESH_Mode.WAKEUP
        DRESignalLINR_CEXV_RdyForSleep: start-on-event=SignalLINR_CEXV_RdyForSleep, data=SignalLINR_CEXV_RdyForSleep.SignalLINR_CEXV_RdyForSleep
          disabled-mode:
            MdulPwrMod.AppMode_MDGP_ESH_Mode.RUN
            MdulPwrMod.AppMode_MDGP_ESH_Mode.STARTUP
            MdulPwrMod.AppMode_MDGP_ESH_Mode.SHUTDOWN
            MdulPwrMod.AppMode_MDGP_ESH_Mode.WAKEUP
        DRESignalLINR_CPIM_RdyForSleep: start-on-event=SignalLINR_CPIM_RdyForSleep, data=SignalLINR_CPIM_RdyForSleep.SignalLINR_CPIM_RdyForSleep
          disabled-mode:
            MdulPwrMod.AppMode_MDGP_ESH_Mode.RUN
            MdulPwrMod.AppMode_MDGP_ESH_Mode.STARTUP
            MdulPwrMod.AppMode_MDGP_ESH_Mode.SHUTDOWN
            MdulPwrMod.AppMode_MDGP_ESH_Mode.WAKEUP
        DRESignalLINR_ECH_RdyForSleep: start-on-event=SignalLINR_ECH_RdyForSleep, data=SignalLINR_ECH_RdyForSleep.SignalLINR_ECH_RdyForSleep
          disabled-mode:
            MdulPwrMod.AppMode_MDGP_ESH_Mode.RUN
            MdulPwrMod.AppMode_MDGP_ESH_Mode.STARTUP
            MdulPwrMod.AppMode_MDGP_ESH_Mode.SHUTDOWN
            MdulPwrMod.AppMode_MDGP_ESH_Mode.WAKEUP
        DRESignalLINR_EOPB_RdyForSleep: start-on-event=SignalLINR_EOPB_RdyForSleep, data=SignalLINR_EOPB_RdyForSleep.SignalLINR_EOPB_RdyForSleep
          disabled-mode:
            MdulPwrMod.AppMode_MDGP_ESH_Mode.RUN
            MdulPwrMod.AppMode_MDGP_ESH_Mode.STARTUP
            MdulPwrMod.AppMode_MDGP_ESH_Mode.SHUTDOWN
            MdulPwrMod.AppMode_MDGP_ESH_Mode.WAKEUP
        DRESignalLINR_HTLBV_RdyForSleep: start-on-event=SignalLINR_HTLBV_RdyForSleep, data=SignalLINR_HTLBV_RdyForSleep.SignalLINR_HTLBV_RdyForSleep
          disabled-mode:
            MdulPwrMod.AppMode_MDGP_ESH_Mode.RUN
            MdulPwrMod.AppMode_MDGP_ESH_Mode.STARTUP
            MdulPwrMod.AppMode_MDGP_ESH_Mode.SHUTDOWN
            MdulPwrMod.AppMode_MDGP_ESH_Mode.WAKEUP
        DRESignalLINR_PECP2_RdyForSleep: start-on-event=SignalLINR_PECP2_RdyForSleep, data=SignalLINR_PECP2_RdyForSleep.SignalLINR_PECP2_RdyForSleep
          disabled-mode:
            MdulPwrMod.AppMode_MDGP_ESH_Mode.RUN
            MdulPwrMod.AppMode_MDGP_ESH_Mode.STARTUP
            MdulPwrMod.AppMode_MDGP_ESH_Mode.SHUTDOWN
            MdulPwrMod.AppMode_MDGP_ESH_Mode.WAKEUP
        DRESignalLINR_SPP2_RdyForSleep: start-on-event=SignalLINR_SPP2_RdyForSleep, data=SignalLINR_SPP2_RdyForSleep.SignalLINR_SPP2_RdyForSleep
          disabled-mode:
            MdulPwrMod.AppMode_MDGP_ESH_Mode.RUN
            MdulPwrMod.AppMode_MDGP_ESH_Mode.STARTUP
            MdulPwrMod.AppMode_MDGP_ESH_Mode.SHUTDOWN
            MdulPwrMod.AppMode_MDGP_ESH_Mode.WAKEUP
        DRECOMRXL_PowerPanel2_LED_A_Feedback_PowerPanel2_STAT_Lin3: start-on-event=COMRXL_PowerPanel2_LED_A_Feedback_PowerPanel2_STAT_Lin3_Received, data=Lin3ComRxSignalsSR.COMRXL_PowerPanel2_LED_A_Feedback_PowerPanel2_STAT_Lin3
